VERSION ""

NS_ :

BS_:

BU_:

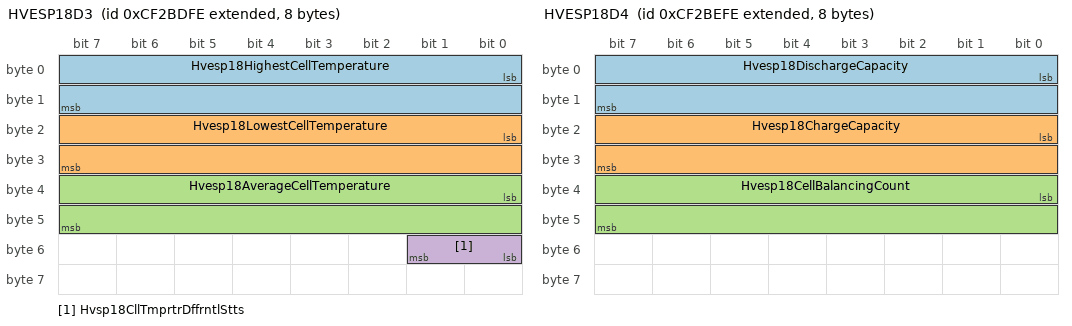
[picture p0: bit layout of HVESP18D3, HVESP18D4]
BO_ 2364718590 HVESP18D3: 8 Vector__XXX
 SG_ Hvesp18HighestCellTemperature : 0|16@1+ (0.03125,-273) [-273|1734.96875] "degC" Vector__XXX
 SG_ Hvesp18LowestCellTemperature : 16|16@1+ (0.03125,-273) [-273|1734.96875] "degC" Vector__XXX
 SG_ Hvesp18AverageCellTemperature : 32|16@1+ (0.03125,-273) [-273|1734.96875] "degC" Vector__XXX
 SG_ Hvsp18CllTmprtrDffrntlStts : 48|2@1+ (1,0) [0|3] "" Vector__XXX

BO_ 2364718846 HVESP18D4: 8 Vector__XXX
 SG_ Hvesp18DischargeCapacity : 0|16@1+ (0.01,0) [0|642.55] "Ah" Vector__XXX
 SG_ Hvesp18ChargeCapacity : 16|16@1+ (0.01,0) [0|642.55] "Ah" Vector__XXX
 SG_ Hvesp18CellBalancingCount : 32|16@1+ (1,0) [0|64255] "count" Vector__XXX

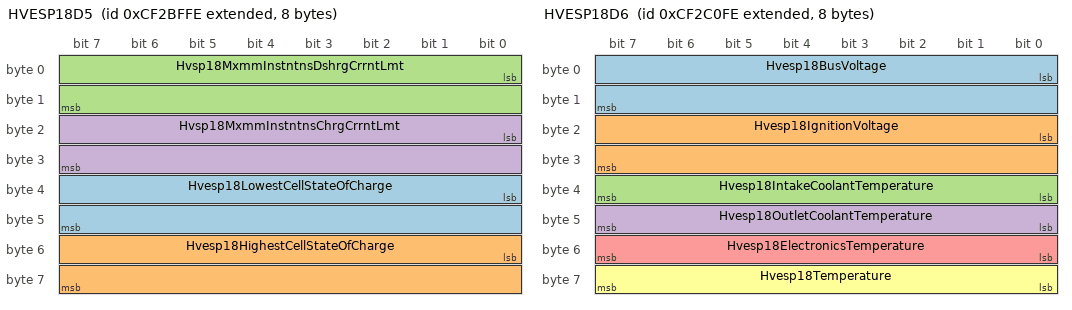
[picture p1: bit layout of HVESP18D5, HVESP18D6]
BO_ 2364719102 HVESP18D5: 8 Vector__XXX
 SG_ Hvesp18LowestCellStateOfCharge : 32|16@1+ (0.0015625,0) [0|100.3984375] "%" Vector__XXX
 SG_ Hvesp18HighestCellStateOfCharge : 48|16@1+ (0.0015625,0) [0|100.3984375] "%" Vector__XXX
 SG_ Hvsp18MxmmInstntnsDshrgCrrntLmt : 0|16@1+ (0.05,-1600) [-1600|0] "A" Vector__XXX
 SG_ Hvsp18MxmmInstntnsChrgCrrntLmt : 16|16@1+ (0.05,-1600) [0|1612.75] "A" Vector__XXX

BO_ 2364719358 HVESP18D6: 8 Vector__XXX
 SG_ Hvesp18BusVoltage : 0|16@1+ (0.05,0) [0|3212.75] "V" Vector__XXX
 SG_ Hvesp18IgnitionVoltage : 16|16@1+ (0.01,0) [0|642.55] "V" Vector__XXX
 SG_ Hvesp18IntakeCoolantTemperature : 32|8@1+ (1,-40) [-40|210] "degC" Vector__XXX
 SG_ Hvesp18OutletCoolantTemperature : 40|8@1+ (1,-40) [-40|210] "degC" Vector__XXX
 SG_ Hvesp18ElectronicsTemperature : 48|8@1+ (1,-40) [-40|210] "degC" Vector__XXX
 SG_ Hvesp18Temperature : 56|8@1+ (1,-40) [-40|210] "degC" Vector__XXX

BO_ 2364719614 HVESP18S1: 8 Vector__XXX
 SG_ Hvsp18HghVltgBsPstvCnttrStt : 0|2@1+ (1,0) [0|3] "" Vector__XXX
 SG_ Hvsp18HghVltgBsNgtvCnttrStt : 2|2@1+ (1,0) [0|3] "" Vector__XXX
 SG_ Hvsp18HghVltgBsDsnntFrwrnng : 4|4@1+ (1,0) [0|15] "" Vector__XXX
 SG_ Hvsp18HghVltgBsPrChrgRlStt : 8|2@1+ (1,0) [0|3] "" Vector__XXX
 SG_ Hvsp18CntrOfPkCnttrStt : 10|2@1+ (1,0) [0|3] "" Vector__XXX
 SG_ Hvsp18HghVltgBsAtvIsltnTstStts : 12|4@1+ (1,0) [0|15] "" Vector__XXX
 SG_ Hvsp18HghVltgBsPssvIsltnTstStts : 16|4@1+ (1,0) [0|15] "" Vector__XXX
 SG_ Hvesp18HvilStatus : 20|2@1+ (1,0) [0|3] "" Vector__XXX
 SG_ Hvesp18InertiaSwitchStatus : 22|2@1+ (1,0) [0|3] "" Vector__XXX
 SG_ Hvesp18StateOfChargeStatus : 24|4@1+ (1,0) [0|15] "" Vector__XXX
 SG_ Hvesp18CellBalanceStatus : 28|2@1+ (1,0) [0|3] "" Vector__XXX
 SG_ Hvesp18CellBalancingActive : 30|2@1+ (1,0) [0|3] "" Vector__XXX
 SG_ Hvesp18InternalChargerStatus : 32|2@1+ (1,0) [0|3] "" Vector__XXX
 SG_ Hvsp18HghVltgBsCnntnStts : 40|4@1+ (1,0) [0|15] "" Vector__XXX
 SG_ Hvesp18OperationalStatus : 44|4@1+ (1,0) [0|15] "" Vector__XXX
 SG_ Hvesp18Status1Counter : 52|4@1+ (1,0) [0|15] "" Vector__XXX
 SG_ Hvesp18Status1Crc : 56|8@1+ (1,0) [0|250] "count" Vector__XXX

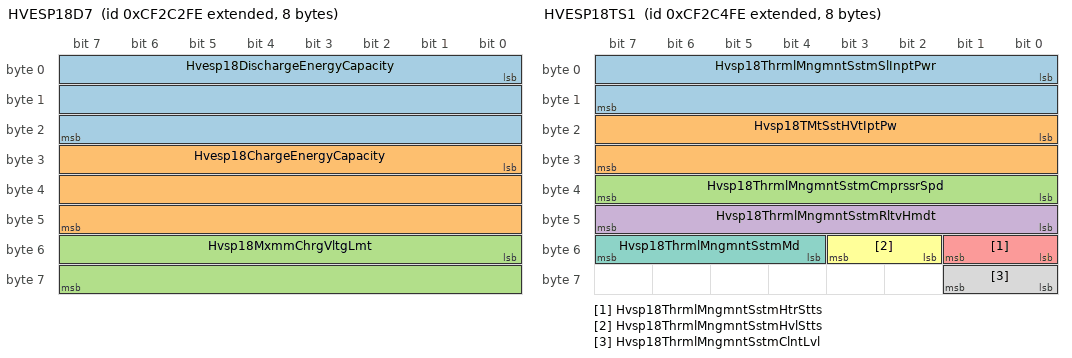
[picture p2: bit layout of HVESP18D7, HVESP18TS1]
BO_ 2364719870 HVESP18D7: 8 Vector__XXX
 SG_ Hvesp18DischargeEnergyCapacity : 0|24@1+ (0.001,0) [0|16449.535] "kWh" Vector__XXX
 SG_ Hvesp18ChargeEnergyCapacity : 24|24@1+ (0.001,0) [0|16449.535] "kWh" Vector__XXX
 SG_ Hvsp18MxmmChrgVltgLmt : 48|16@1+ (0.05,0) [0|3212.75] "V" Vector__XXX

BO_ 2364720126 HVESP18MS1: 8 Vector__XXX
 SG_ Hvesp18Module1OperationalStatus : 0|2@1+ (1,0) [0|3] "" Vector__XXX
 SG_ Hvesp18Module2OperationalStatus : 2|2@1+ (1,0) [0|3] "" Vector__XXX
 SG_ Hvesp18Module3OperationalStatus : 4|2@1+ (1,0) [0|3] "" Vector__XXX
 SG_ Hvesp18Module4OperationalStatus : 6|2@1+ (1,0) [0|3] "" Vector__XXX
 SG_ Hvesp18Module5OperationalStatus : 8|2@1+ (1,0) [0|3] "" Vector__XXX
 SG_ Hvesp18Module6OperationalStatus : 10|2@1+ (1,0) [0|3] "" Vector__XXX
 SG_ Hvesp18Module7OperationalStatus : 12|2@1+ (1,0) [0|3] "" Vector__XXX
 SG_ Hvesp18Module8OperationalStatus : 14|2@1+ (1,0) [0|3] "" Vector__XXX
 SG_ Hvesp18Module9OperationalStatus : 16|2@1+ (1,0) [0|3] "" Vector__XXX
 SG_ Hvsp18Mdl10OprtnlStts : 18|2@1+ (1,0) [0|3] "" Vector__XXX
 SG_ Hvsp18Mdl11OprtnlStts : 20|2@1+ (1,0) [0|3] "" Vector__XXX
 SG_ Hvsp18Mdl12OprtnlStts : 22|2@1+ (1,0) [0|3] "" Vector__XXX
 SG_ Hvsp18Mdl13OprtnlStts : 24|2@1+ (1,0) [0|3] "" Vector__XXX
 SG_ Hvsp18Mdl14OprtnlStts : 26|2@1+ (1,0) [0|3] "" Vector__XXX
 SG_ Hvsp18Mdl15OprtnlStts : 28|2@1+ (1,0) [0|3] "" Vector__XXX
 SG_ Hvsp18Mdl16OprtnlStts : 30|2@1+ (1,0) [0|3] "" Vector__XXX
 SG_ Hvsp18Mdl17OprtnlStts : 32|2@1+ (1,0) [0|3] "" Vector__XXX
 SG_ Hvsp18Mdl18OprtnlStts : 34|2@1+ (1,0) [0|3] "" Vector__XXX
 SG_ Hvsp18Mdl19OprtnlStts : 36|2@1+ (1,0) [0|3] "" Vector__XXX
 SG_ Hvsp18Mdl20OprtnlStts : 38|2@1+ (1,0) [0|3] "" Vector__XXX
 SG_ Hvsp18Mdl21OprtnlStts : 40|2@1+ (1,0) [0|3] "" Vector__XXX
 SG_ Hvsp18Mdl22OprtnlStts : 42|2@1+ (1,0) [0|3] "" Vector__XXX
 SG_ Hvsp18Mdl23OprtnlStts : 44|2@1+ (1,0) [0|3] "" Vector__XXX
 SG_ Hvsp18Mdl24OprtnlStts : 46|2@1+ (1,0) [0|3] "" Vector__XXX
 SG_ Hvsp18Mdl25OprtnlStts : 48|2@1+ (1,0) [0|3] "" Vector__XXX
 SG_ Hvsp18Mdl26OprtnlStts : 50|2@1+ (1,0) [0|3] "" Vector__XXX
 SG_ Hvsp18Mdl27OprtnlStts : 52|2@1+ (1,0) [0|3] "" Vector__XXX
 SG_ Hvsp18Mdl28OprtnlStts : 54|2@1+ (1,0) [0|3] "" Vector__XXX
 SG_ Hvsp18Mdl29OprtnlStts : 56|2@1+ (1,0) [0|3] "" Vector__XXX
 SG_ Hvsp18Mdl30OprtnlStts : 58|2@1+ (1,0) [0|3] "" Vector__XXX
 SG_ Hvsp18Mdl31OprtnlStts : 60|2@1+ (1,0) [0|3] "" Vector__XXX
 SG_ Hvsp18Mdl32OprtnlStts : 62|2@1+ (1,0) [0|3] "" Vector__XXX

BO_ 2364720382 HVESP18TS1: 8 Vector__XXX
 SG_ Hvsp18ThrmlMngmntSstmSlInptPwr : 0|16@1+ (0.5,0) [0|32127.5] "W" Vector__XXX
 SG_ Hvsp18TMtSstHVtIptPw : 16|16@1+ (0.5,0) [0|32127.5] "W" Vector__XXX
 SG_ Hvsp18ThrmlMngmntSstmCmprssrSpd : 32|8@1+ (32,0) [0|8000] "rpm" Vector__XXX
 SG_ Hvsp18ThrmlMngmntSstmRltvHmdt : 40|8@1+ (0.4,0) [0|100] "%" Vector__XXX
 SG_ Hvsp18ThrmlMngmntSstmHtrStts : 48|2@1+ (1,0) [0|3] "" Vector__XXX
 SG_ Hvsp18ThrmlMngmntSstmHvlStts : 50|2@1+ (1,0) [0|3] "" Vector__XXX
 SG_ Hvsp18ThrmlMngmntSstmMd : 52|4@1+ (1,0) [0|15] "" Vector__XXX
 SG_ Hvsp18ThrmlMngmntSstmClntLvl : 56|2@1+ (1,0) [0|3] "" Vector__XXX

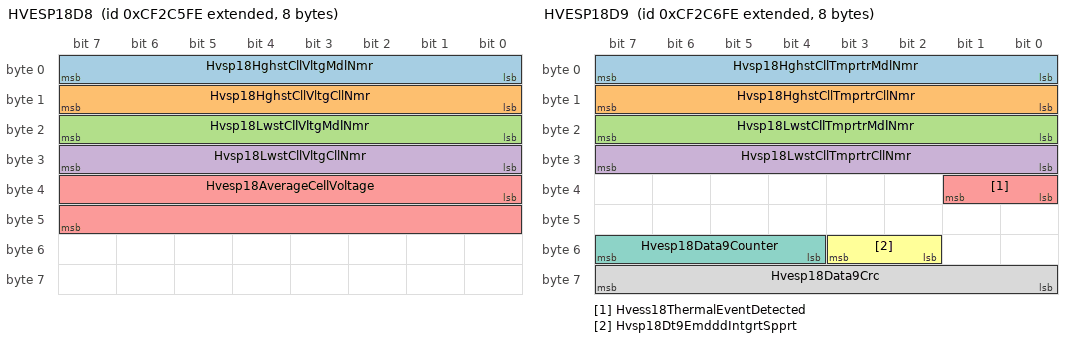
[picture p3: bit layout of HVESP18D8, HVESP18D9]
BO_ 2364720638 HVESP18D8: 8 Vector__XXX
 SG_ Hvsp18HghstCllVltgMdlNmr : 0|8@1+ (1,0) [0|250] "count" Vector__XXX
 SG_ Hvsp18HghstCllVltgCllNmr : 8|8@1+ (1,0) [0|250] "count" Vector__XXX
 SG_ Hvsp18LwstCllVltgMdlNmr : 16|8@1+ (1,0) [0|250] "count" Vector__XXX
 SG_ Hvsp18LwstCllVltgCllNmr : 24|8@1+ (1,0) [0|250] "count" Vector__XXX
 SG_ Hvesp18AverageCellVoltage : 32|16@1+ (0.001,0) [0|64.255] "V" Vector__XXX

BO_ 2364720894 HVESP18D9: 8 Vector__XXX
 SG_ Hvsp18HghstCllTmprtrMdlNmr : 0|8@1+ (1,0) [0|250] "count" Vector__XXX
 SG_ Hvsp18HghstCllTmprtrCllNmr : 8|8@1+ (1,0) [0|250] "count" Vector__XXX
 SG_ Hvsp18LwstCllTmprtrMdlNmr : 16|8@1+ (1,0) [0|250] "count" Vector__XXX
 SG_ Hvsp18LwstCllTmprtrCllNmr : 24|8@1+ (1,0) [0|250] "count" Vector__XXX
 SG_ Hvess18ThermalEventDetected : 32|2@1+ (1,0) [0|3] "" Vector__XXX
 SG_ Hvsp18Dt9EmdddIntgrtSpprt : 50|2@1+ (1,0) [0|3] "" Vector__XXX
 SG_ Hvesp18Data9Counter : 52|4@1+ (1,0) [0|15] "" Vector__XXX
 SG_ Hvesp18Data9Crc : 56|8@1+ (1,0) [0|250] "count" Vector__XXX

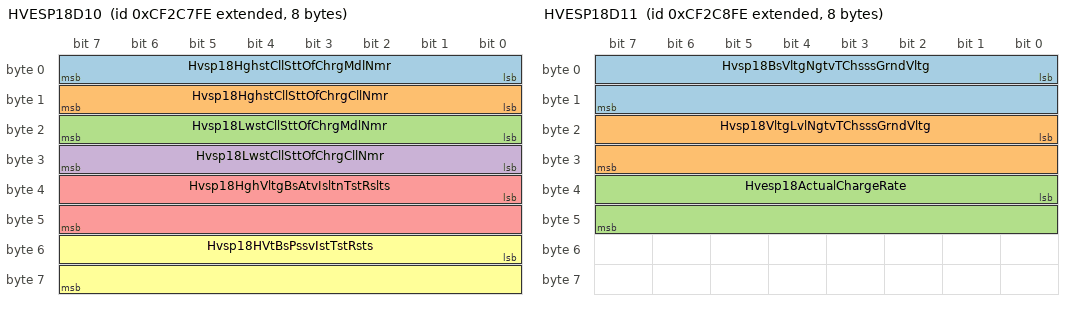
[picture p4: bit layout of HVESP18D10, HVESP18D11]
BO_ 2364721150 HVESP18D10: 8 Vector__XXX
 SG_ Hvsp18HghstCllSttOfChrgMdlNmr : 0|8@1+ (1,0) [0|250] "count" Vector__XXX
 SG_ Hvsp18HghstCllSttOfChrgCllNmr : 8|8@1+ (1,0) [0|250] "count" Vector__XXX
 SG_ Hvsp18LwstCllSttOfChrgMdlNmr : 16|8@1+ (1,0) [0|250] "count" Vector__XXX
 SG_ Hvsp18LwstCllSttOfChrgCllNmr : 24|8@1+ (1,0) [0|250] "count" Vector__XXX
 SG_ Hvsp18HghVltgBsAtvIsltnTstRslts : 32|16@1+ (0.1,0) [0|6425.5] "OhmPerV" Vector__XXX
 SG_ Hvsp18HVtBsPssvIstTstRsts : 48|16@1+ (0.1,0) [0|6425.5] "OhmPerV" Vector__XXX

BO_ 2364721406 HVESP18D11: 8 Vector__XXX
 SG_ Hvsp18BsVltgNgtvTChsssGrndVltg : 0|16@1+ (0.05,0) [0|3212.75] "V" Vector__XXX
 SG_ Hvsp18VltgLvlNgtvTChsssGrndVltg : 16|16@1+ (0.05,0) [0|3212.75] "V" Vector__XXX
 SG_ Hvesp18ActualChargeRate : 32|16@1+ (0.05,0) [0|3212.75] "kW" Vector__XXX

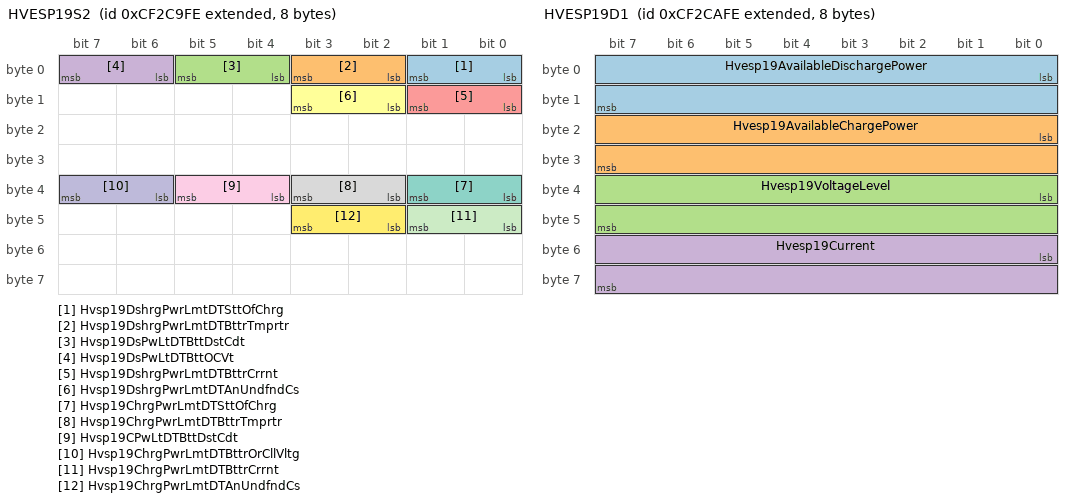
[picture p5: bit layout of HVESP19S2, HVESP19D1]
BO_ 2364721662 HVESP19S2: 8 Vector__XXX
 SG_ Hvsp19DshrgPwrLmtDTSttOfChrg : 0|2@1+ (1,0) [0|3] "" Vector__XXX
 SG_ Hvsp19DshrgPwrLmtDTBttrTmprtr : 2|2@1+ (1,0) [0|3] "" Vector__XXX
 SG_ Hvsp19DsPwLtDTBttDstCdt : 4|2@1+ (1,0) [0|3] "" Vector__XXX
 SG_ Hvsp19DsPwLtDTBttOCVt : 6|2@1+ (1,0) [0|3] "" Vector__XXX
 SG_ Hvsp19DshrgPwrLmtDTBttrCrrnt : 8|2@1+ (1,0) [0|3] "" Vector__XXX
 SG_ Hvsp19DshrgPwrLmtDTAnUndfndCs : 10|2@1+ (1,0) [0|3] "" Vector__XXX
 SG_ Hvsp19ChrgPwrLmtDTSttOfChrg : 32|2@1+ (1,0) [0|3] "" Vector__XXX
 SG_ Hvsp19ChrgPwrLmtDTBttrTmprtr : 34|2@1+ (1,0) [0|3] "" Vector__XXX
 SG_ Hvsp19CPwLtDTBttDstCdt : 36|2@1+ (1,0) [0|3] "" Vector__XXX
 SG_ Hvsp19ChrgPwrLmtDTBttrOrCllVltg : 38|2@1+ (1,0) [0|3] "" Vector__XXX
 SG_ Hvsp19ChrgPwrLmtDTBttrCrrnt : 40|2@1+ (1,0) [0|3] "" Vector__XXX
 SG_ Hvsp19ChrgPwrLmtDTAnUndfndCs : 42|2@1+ (1,0) [0|3] "" Vector__XXX

BO_ 2364721918 HVESP19D1: 8 Vector__XXX
 SG_ Hvesp19AvailableDischargePower : 0|16@1+ (0.05,0) [0|3212.75] "kW" Vector__XXX
 SG_ Hvesp19AvailableChargePower : 16|16@1+ (0.05,0) [0|3212.75] "kW" Vector__XXX
 SG_ Hvesp19VoltageLevel : 32|16@1+ (0.05,0) [0|3212.75] "V" Vector__XXX
 SG_ Hvesp19Current : 48|16@1+ (0.05,-1600) [-1600|1612.75] "A" Vector__XXX

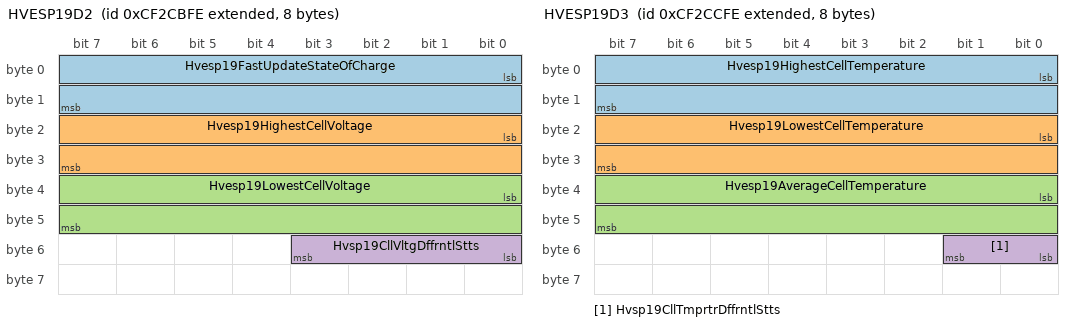
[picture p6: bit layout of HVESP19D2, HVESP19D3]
BO_ 2364722174 HVESP19D2: 8 Vector__XXX
 SG_ Hvesp19FastUpdateStateOfCharge : 0|16@1+ (0.0015625,0) [0|100.3984375] "%" Vector__XXX
 SG_ Hvesp19HighestCellVoltage : 16|16@1+ (0.001,0) [0|64.255] "V" Vector__XXX
 SG_ Hvesp19LowestCellVoltage : 32|16@1+ (0.001,0) [0|64.255] "V" Vector__XXX
 SG_ Hvsp19CllVltgDffrntlStts : 48|4@1+ (1,0) [0|15] "" Vector__XXX

BO_ 2364722430 HVESP19D3: 8 Vector__XXX
 SG_ Hvesp19HighestCellTemperature : 0|16@1+ (0.03125,-273) [-273|1734.96875] "degC" Vector__XXX
 SG_ Hvesp19LowestCellTemperature : 16|16@1+ (0.03125,-273) [-273|1734.96875] "degC" Vector__XXX
 SG_ Hvesp19AverageCellTemperature : 32|16@1+ (0.03125,-273) [-273|1734.96875] "degC" Vector__XXX
 SG_ Hvsp19CllTmprtrDffrntlStts : 48|2@1+ (1,0) [0|3] "" Vector__XXX

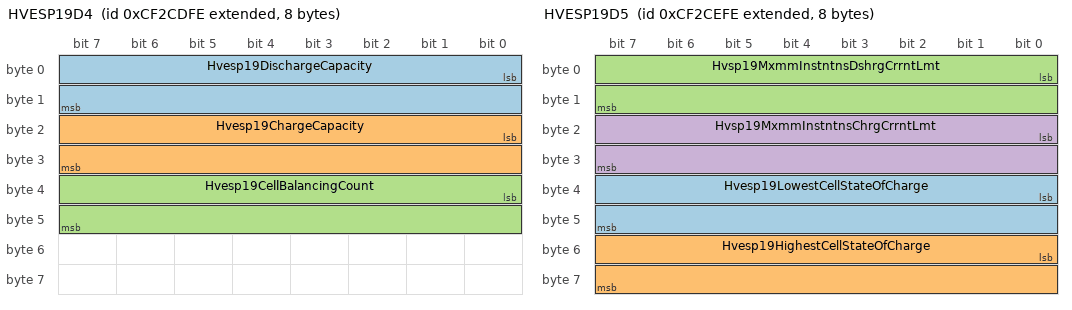
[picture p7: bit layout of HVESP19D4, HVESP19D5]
BO_ 2364722686 HVESP19D4: 8 Vector__XXX
 SG_ Hvesp19DischargeCapacity : 0|16@1+ (0.01,0) [0|642.55] "Ah" Vector__XXX
 SG_ Hvesp19ChargeCapacity : 16|16@1+ (0.01,0) [0|642.55] "Ah" Vector__XXX
 SG_ Hvesp19CellBalancingCount : 32|16@1+ (1,0) [0|64255] "count" Vector__XXX

BO_ 2364722942 HVESP19D5: 8 Vector__XXX
 SG_ Hvesp19LowestCellStateOfCharge : 32|16@1+ (0.0015625,0) [0|100.3984375] "%" Vector__XXX
 SG_ Hvesp19HighestCellStateOfCharge : 48|16@1+ (0.0015625,0) [0|100.3984375] "%" Vector__XXX
 SG_ Hvsp19MxmmInstntnsDshrgCrrntLmt : 0|16@1+ (0.05,-1600) [-1600|0] "A" Vector__XXX
 SG_ Hvsp19MxmmInstntnsChrgCrrntLmt : 16|16@1+ (0.05,-1600) [0|1612.75] "A" Vector__XXX

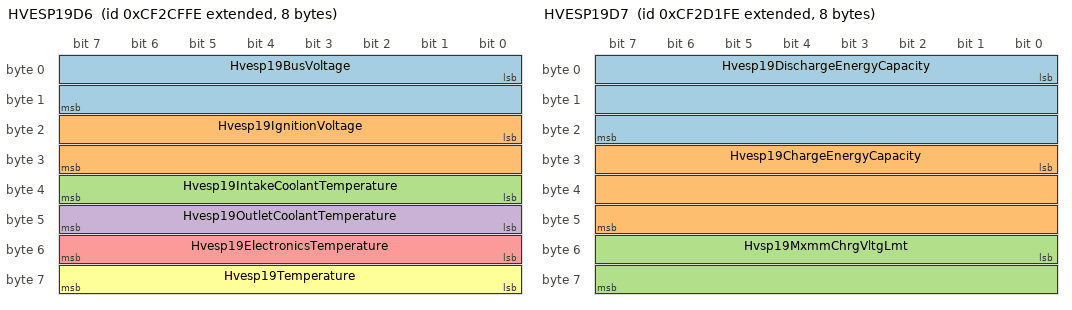
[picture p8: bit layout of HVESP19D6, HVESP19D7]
BO_ 2364723198 HVESP19D6: 8 Vector__XXX
 SG_ Hvesp19BusVoltage : 0|16@1+ (0.05,0) [0|3212.75] "V" Vector__XXX
 SG_ Hvesp19IgnitionVoltage : 16|16@1+ (0.01,0) [0|642.55] "V" Vector__XXX
 SG_ Hvesp19IntakeCoolantTemperature : 32|8@1+ (1,-40) [-40|210] "degC" Vector__XXX
 SG_ Hvesp19OutletCoolantTemperature : 40|8@1+ (1,-40) [-40|210] "degC" Vector__XXX
 SG_ Hvesp19ElectronicsTemperature : 48|8@1+ (1,-40) [-40|210] "degC" Vector__XXX
 SG_ Hvesp19Temperature : 56|8@1+ (1,-40) [-40|210] "degC" Vector__XXX

BO_ 2364723454 HVESP19S1: 8 Vector__XXX
 SG_ Hvsp19HghVltgBsPstvCnttrStt : 0|2@1+ (1,0) [0|3] "" Vector__XXX
 SG_ Hvsp19HghVltgBsNgtvCnttrStt : 2|2@1+ (1,0) [0|3] "" Vector__XXX
 SG_ Hvsp19HghVltgBsDsnntFrwrnng : 4|4@1+ (1,0) [0|15] "" Vector__XXX
 SG_ Hvsp19HghVltgBsPrChrgRlStt : 8|2@1+ (1,0) [0|3] "" Vector__XXX
 SG_ Hvsp19CntrOfPkCnttrStt : 10|2@1+ (1,0) [0|3] "" Vector__XXX
 SG_ Hvsp19HghVltgBsAtvIsltnTstStts : 12|4@1+ (1,0) [0|15] "" Vector__XXX
 SG_ Hvsp19HghVltgBsPssvIsltnTstStts : 16|4@1+ (1,0) [0|15] "" Vector__XXX
 SG_ Hvesp19HvilStatus : 20|2@1+ (1,0) [0|3] "" Vector__XXX
 SG_ Hvesp19InertiaSwitchStatus : 22|2@1+ (1,0) [0|3] "" Vector__XXX
 SG_ Hvesp19StateOfChargeStatus : 24|4@1+ (1,0) [0|15] "" Vector__XXX
 SG_ Hvesp19CellBalanceStatus : 28|2@1+ (1,0) [0|3] "" Vector__XXX
 SG_ Hvesp19CellBalancingActive : 30|2@1+ (1,0) [0|3] "" Vector__XXX
 SG_ Hvesp19InternalChargerStatus : 32|2@1+ (1,0) [0|3] "" Vector__XXX
 SG_ Hvsp19HghVltgBsCnntnStts : 40|4@1+ (1,0) [0|15] "" Vector__XXX
 SG_ Hvesp19OperationalStatus : 44|4@1+ (1,0) [0|15] "" Vector__XXX
 SG_ Hvesp19Status1Counter : 52|4@1+ (1,0) [0|15] "" Vector__XXX
 SG_ Hvesp19Status1Crc : 56|8@1+ (1,0) [0|250] "count" Vector__XXX

BO_ 2364723710 HVESP19D7: 8 Vector__XXX
 SG_ Hvesp19DischargeEnergyCapacity : 0|24@1+ (0.001,0) [0|16449.535] "kWh" Vector__XXX
 SG_ Hvesp19ChargeEnergyCapacity : 24|24@1+ (0.001,0) [0|16449.535] "kWh" Vector__XXX
 SG_ Hvsp19MxmmChrgVltgLmt : 48|16@1+ (0.05,0) [0|3212.75] "V" Vector__XXX

BO_ 2364723966 HVESP19MS1: 8 Vector__XXX
 SG_ Hvesp19Module1OperationalStatus : 0|2@1+ (1,0) [0|3] "" Vector__XXX
 SG_ Hvesp19Module2OperationalStatus : 2|2@1+ (1,0) [0|3] "" Vector__XXX
 SG_ Hvesp19Module3OperationalStatus : 4|2@1+ (1,0) [0|3] "" Vector__XXX
 SG_ Hvesp19Module4OperationalStatus : 6|2@1+ (1,0) [0|3] "" Vector__XXX
 SG_ Hvesp19Module5OperationalStatus : 8|2@1+ (1,0) [0|3] "" Vector__XXX
 SG_ Hvesp19Module6OperationalStatus : 10|2@1+ (1,0) [0|3] "" Vector__XXX
 SG_ Hvesp19Module7OperationalStatus : 12|2@1+ (1,0) [0|3] "" Vector__XXX
 SG_ Hvesp19Module8OperationalStatus : 14|2@1+ (1,0) [0|3] "" Vector__XXX
 SG_ Hvesp19Module9OperationalStatus : 16|2@1+ (1,0) [0|3] "" Vector__XXX
 SG_ Hvsp19Mdl10OprtnlStts : 18|2@1+ (1,0) [0|3] "" Vector__XXX
 SG_ Hvsp19Mdl11OprtnlStts : 20|2@1+ (1,0) [0|3] "" Vector__XXX
 SG_ Hvsp19Mdl12OprtnlStts : 22|2@1+ (1,0) [0|3] "" Vector__XXX
 SG_ Hvsp19Mdl13OprtnlStts : 24|2@1+ (1,0) [0|3] "" Vector__XXX
 SG_ Hvsp19Mdl14OprtnlStts : 26|2@1+ (1,0) [0|3] "" Vector__XXX
 SG_ Hvsp19Mdl15OprtnlStts : 28|2@1+ (1,0) [0|3] "" Vector__XXX
 SG_ Hvsp19Mdl16OprtnlStts : 30|2@1+ (1,0) [0|3] "" Vector__XXX
 SG_ Hvsp19Mdl17OprtnlStts : 32|2@1+ (1,0) [0|3] "" Vector__XXX
 SG_ Hvsp19Mdl18OprtnlStts : 34|2@1+ (1,0) [0|3] "" Vector__XXX
 SG_ Hvsp19Mdl19OprtnlStts : 36|2@1+ (1,0) [0|3] "" Vector__XXX
 SG_ Hvsp19Mdl20OprtnlStts : 38|2@1+ (1,0) [0|3] "" Vector__XXX
 SG_ Hvsp19Mdl21OprtnlStts : 40|2@1+ (1,0) [0|3] "" Vector__XXX
 SG_ Hvsp19Mdl22OprtnlStts : 42|2@1+ (1,0) [0|3] "" Vector__XXX
 SG_ Hvsp19Mdl23OprtnlStts : 44|2@1+ (1,0) [0|3] "" Vector__XXX
 SG_ Hvsp19Mdl24OprtnlStts : 46|2@1+ (1,0) [0|3] "" Vector__XXX
 SG_ Hvsp19Mdl25OprtnlStts : 48|2@1+ (1,0) [0|3] "" Vector__XXX
 SG_ Hvsp19Mdl26OprtnlStts : 50|2@1+ (1,0) [0|3] "" Vector__XXX
 SG_ Hvsp19Mdl27OprtnlStts : 52|2@1+ (1,0) [0|3] "" Vector__XXX
 SG_ Hvsp19Mdl28OprtnlStts : 54|2@1+ (1,0) [0|3] "" Vector__XXX
 SG_ Hvsp19Mdl29OprtnlStts : 56|2@1+ (1,0) [0|3] "" Vector__XXX
 SG_ Hvsp19Mdl30OprtnlStts : 58|2@1+ (1,0) [0|3] "" Vector__XXX
 SG_ Hvsp19Mdl31OprtnlStts : 60|2@1+ (1,0) [0|3] "" Vector__XXX
 SG_ Hvsp19Mdl32OprtnlStts : 62|2@1+ (1,0) [0|3] "" Vector__XXX

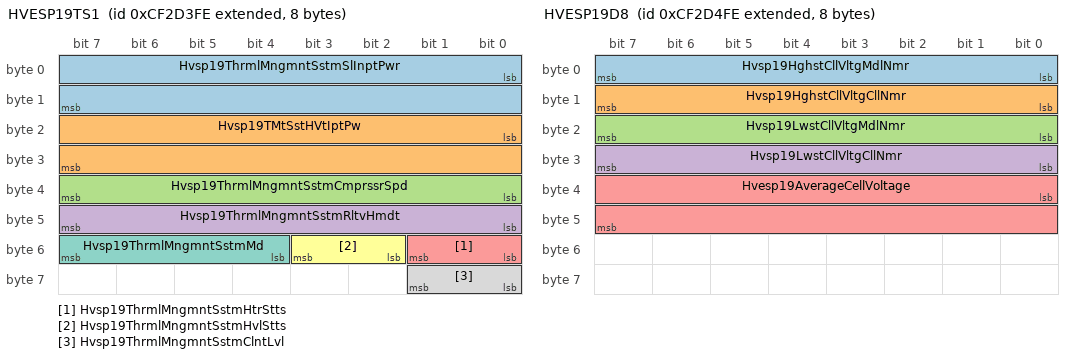
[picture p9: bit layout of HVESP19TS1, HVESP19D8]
BO_ 2364724222 HVESP19TS1: 8 Vector__XXX
 SG_ Hvsp19ThrmlMngmntSstmSlInptPwr : 0|16@1+ (0.5,0) [0|32127.5] "W" Vector__XXX
 SG_ Hvsp19TMtSstHVtIptPw : 16|16@1+ (0.5,0) [0|32127.5] "W" Vector__XXX
 SG_ Hvsp19ThrmlMngmntSstmCmprssrSpd : 32|8@1+ (32,0) [0|8000] "rpm" Vector__XXX
 SG_ Hvsp19ThrmlMngmntSstmRltvHmdt : 40|8@1+ (0.4,0) [0|100] "%" Vector__XXX
 SG_ Hvsp19ThrmlMngmntSstmHtrStts : 48|2@1+ (1,0) [0|3] "" Vector__XXX
 SG_ Hvsp19ThrmlMngmntSstmHvlStts : 50|2@1+ (1,0) [0|3] "" Vector__XXX
 SG_ Hvsp19ThrmlMngmntSstmMd : 52|4@1+ (1,0) [0|15] "" Vector__XXX
 SG_ Hvsp19ThrmlMngmntSstmClntLvl : 56|2@1+ (1,0) [0|3] "" Vector__XXX

BO_ 2364724478 HVESP19D8: 8 Vector__XXX
 SG_ Hvsp19HghstCllVltgMdlNmr : 0|8@1+ (1,0) [0|250] "count" Vector__XXX
 SG_ Hvsp19HghstCllVltgCllNmr : 8|8@1+ (1,0) [0|250] "count" Vector__XXX
 SG_ Hvsp19LwstCllVltgMdlNmr : 16|8@1+ (1,0) [0|250] "count" Vector__XXX
 SG_ Hvsp19LwstCllVltgCllNmr : 24|8@1+ (1,0) [0|250] "count" Vector__XXX
 SG_ Hvesp19AverageCellVoltage : 32|16@1+ (0.001,0) [0|64.255] "V" Vector__XXX

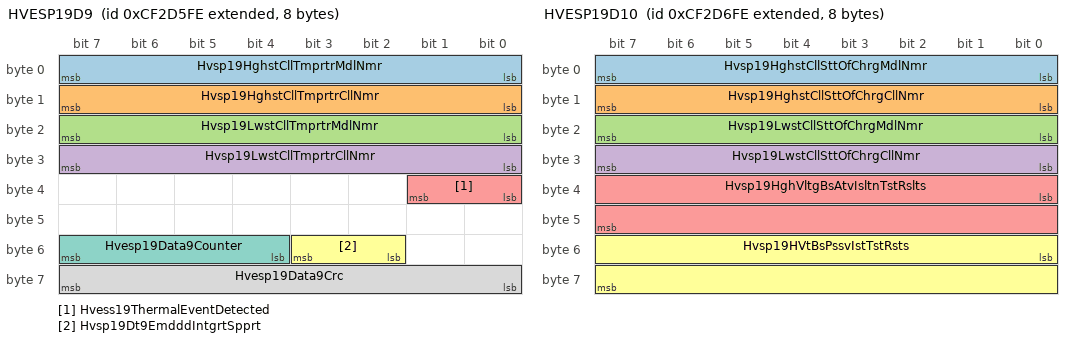
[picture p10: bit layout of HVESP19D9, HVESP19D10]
BO_ 2364724734 HVESP19D9: 8 Vector__XXX
 SG_ Hvsp19HghstCllTmprtrMdlNmr : 0|8@1+ (1,0) [0|250] "count" Vector__XXX
 SG_ Hvsp19HghstCllTmprtrCllNmr : 8|8@1+ (1,0) [0|250] "count" Vector__XXX
 SG_ Hvsp19LwstCllTmprtrMdlNmr : 16|8@1+ (1,0) [0|250] "count" Vector__XXX
 SG_ Hvsp19LwstCllTmprtrCllNmr : 24|8@1+ (1,0) [0|250] "count" Vector__XXX
 SG_ Hvess19ThermalEventDetected : 32|2@1+ (1,0) [0|3] "" Vector__XXX
 SG_ Hvsp19Dt9EmdddIntgrtSpprt : 50|2@1+ (1,0) [0|3] "" Vector__XXX
 SG_ Hvesp19Data9Counter : 52|4@1+ (1,0) [0|15] "" Vector__XXX
 SG_ Hvesp19Data9Crc : 56|8@1+ (1,0) [0|250] "count" Vector__XXX

BO_ 2364724990 HVESP19D10: 8 Vector__XXX
 SG_ Hvsp19HghstCllSttOfChrgMdlNmr : 0|8@1+ (1,0) [0|250] "count" Vector__XXX
 SG_ Hvsp19HghstCllSttOfChrgCllNmr : 8|8@1+ (1,0) [0|250] "count" Vector__XXX
 SG_ Hvsp19LwstCllSttOfChrgMdlNmr : 16|8@1+ (1,0) [0|250] "count" Vector__XXX
 SG_ Hvsp19LwstCllSttOfChrgCllNmr : 24|8@1+ (1,0) [0|250] "count" Vector__XXX
 SG_ Hvsp19HghVltgBsAtvIsltnTstRslts : 32|16@1+ (0.1,0) [0|6425.5] "OhmPerV" Vector__XXX
 SG_ Hvsp19HVtBsPssvIstTstRsts : 48|16@1+ (0.1,0) [0|6425.5] "OhmPerV" Vector__XXX

BO_ 2364725246 HVESP19D11: 8 Vector__XXX
 SG_ Hvsp19BsVltgNgtvTChsssGrndVltg : 0|16@1+ (0.05,0) [0|3212.75] "V" Vector__XXX
 SG_ Hvsp19VltgLvlNgtvTChsssGrndVltg : 16|16@1+ (0.05,0) [0|3212.75] "V" Vector__XXX
 SG_ Hvesp19ActualChargeRate : 32|16@1+ (0.05,0) [0|3212.75] "kW" Vector__XXX

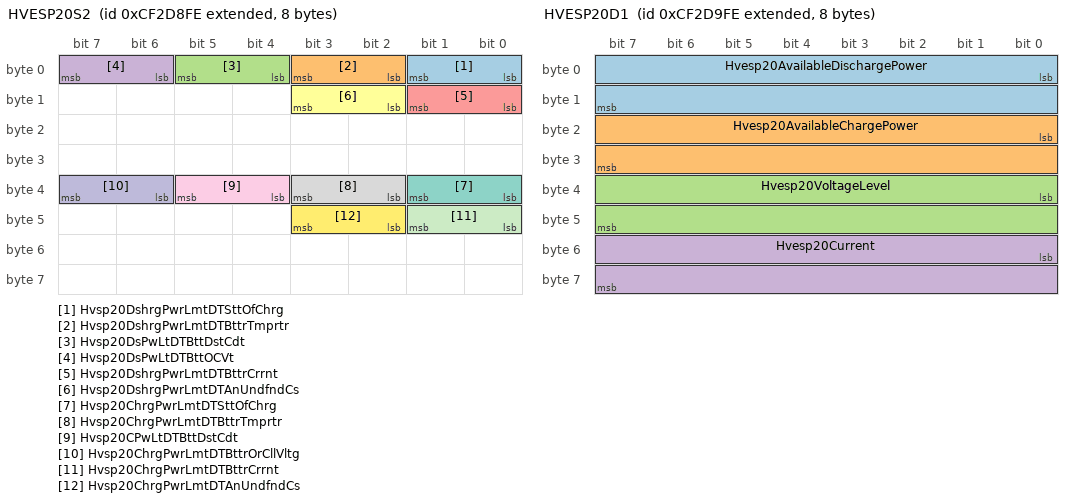
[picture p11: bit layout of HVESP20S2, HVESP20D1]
BO_ 2364725502 HVESP20S2: 8 Vector__XXX
 SG_ Hvsp20DshrgPwrLmtDTSttOfChrg : 0|2@1+ (1,0) [0|3] "" Vector__XXX
 SG_ Hvsp20DshrgPwrLmtDTBttrTmprtr : 2|2@1+ (1,0) [0|3] "" Vector__XXX
 SG_ Hvsp20DsPwLtDTBttDstCdt : 4|2@1+ (1,0) [0|3] "" Vector__XXX
 SG_ Hvsp20DsPwLtDTBttOCVt : 6|2@1+ (1,0) [0|3] "" Vector__XXX
 SG_ Hvsp20DshrgPwrLmtDTBttrCrrnt : 8|2@1+ (1,0) [0|3] "" Vector__XXX
 SG_ Hvsp20DshrgPwrLmtDTAnUndfndCs : 10|2@1+ (1,0) [0|3] "" Vector__XXX
 SG_ Hvsp20ChrgPwrLmtDTSttOfChrg : 32|2@1+ (1,0) [0|3] "" Vector__XXX
 SG_ Hvsp20ChrgPwrLmtDTBttrTmprtr : 34|2@1+ (1,0) [0|3] "" Vector__XXX
 SG_ Hvsp20CPwLtDTBttDstCdt : 36|2@1+ (1,0) [0|3] "" Vector__XXX
 SG_ Hvsp20ChrgPwrLmtDTBttrOrCllVltg : 38|2@1+ (1,0) [0|3] "" Vector__XXX
 SG_ Hvsp20ChrgPwrLmtDTBttrCrrnt : 40|2@1+ (1,0) [0|3] "" Vector__XXX
 SG_ Hvsp20ChrgPwrLmtDTAnUndfndCs : 42|2@1+ (1,0) [0|3] "" Vector__XXX

BO_ 2364725758 HVESP20D1: 8 Vector__XXX
 SG_ Hvesp20AvailableDischargePower : 0|16@1+ (0.05,0) [0|3212.75] "kW" Vector__XXX
 SG_ Hvesp20AvailableChargePower : 16|16@1+ (0.05,0) [0|3212.75] "kW" Vector__XXX
 SG_ Hvesp20VoltageLevel : 32|16@1+ (0.05,0) [0|3212.75] "V" Vector__XXX
 SG_ Hvesp20Current : 48|16@1+ (0.05,-1600) [-1600|1612.75] "A" Vector__XXX

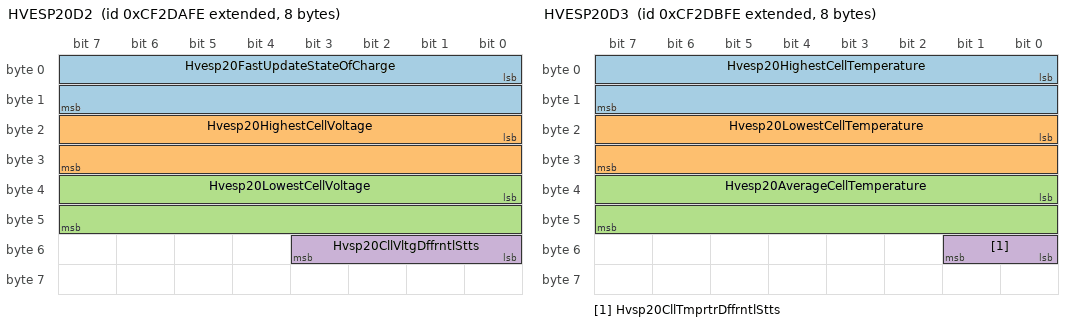
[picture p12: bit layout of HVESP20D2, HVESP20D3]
BO_ 2364726014 HVESP20D2: 8 Vector__XXX
 SG_ Hvesp20FastUpdateStateOfCharge : 0|16@1+ (0.0015625,0) [0|100.3984375] "%" Vector__XXX
 SG_ Hvesp20HighestCellVoltage : 16|16@1+ (0.001,0) [0|64.255] "V" Vector__XXX
 SG_ Hvesp20LowestCellVoltage : 32|16@1+ (0.001,0) [0|64.255] "V" Vector__XXX
 SG_ Hvsp20CllVltgDffrntlStts : 48|4@1+ (1,0) [0|15] "" Vector__XXX

BO_ 2364726270 HVESP20D3: 8 Vector__XXX
 SG_ Hvesp20HighestCellTemperature : 0|16@1+ (0.03125,-273) [-273|1734.96875] "degC" Vector__XXX
 SG_ Hvesp20LowestCellTemperature : 16|16@1+ (0.03125,-273) [-273|1734.96875] "degC" Vector__XXX
 SG_ Hvesp20AverageCellTemperature : 32|16@1+ (0.03125,-273) [-273|1734.96875] "degC" Vector__XXX
 SG_ Hvsp20CllTmprtrDffrntlStts : 48|2@1+ (1,0) [0|3] "" Vector__XXX

BO_ 2364726526 HVESP20D4: 8 Vector__XXX
 SG_ Hvesp20DischargeCapacity : 0|16@1+ (0.01,0) [0|642.55] "Ah" Vector__XXX
 SG_ Hvesp20ChargeCapacity : 16|16@1+ (0.01,0) [0|642.55] "Ah" Vector__XXX
 SG_ Hvesp20CellBalancingCount : 32|16@1+ (1,0) [0|64255] "count" Vector__XXX

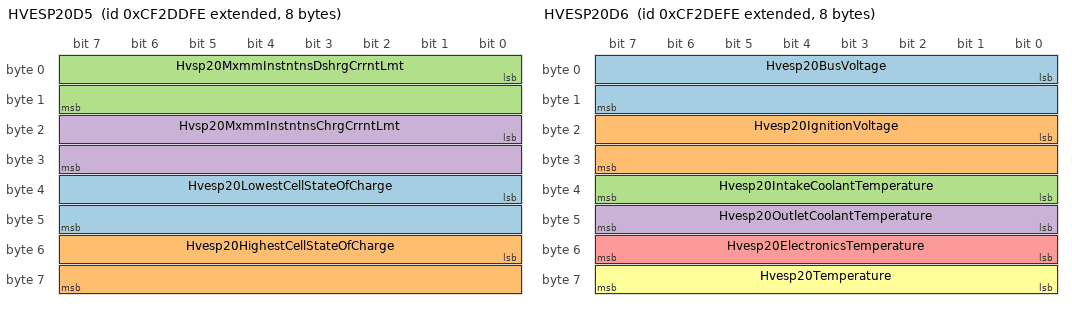
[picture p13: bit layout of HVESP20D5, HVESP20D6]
BO_ 2364726782 HVESP20D5: 8 Vector__XXX
 SG_ Hvesp20LowestCellStateOfCharge : 32|16@1+ (0.0015625,0) [0|100.3984375] "%" Vector__XXX
 SG_ Hvesp20HighestCellStateOfCharge : 48|16@1+ (0.0015625,0) [0|100.3984375] "%" Vector__XXX
 SG_ Hvsp20MxmmInstntnsDshrgCrrntLmt : 0|16@1+ (0.05,-1600) [-1600|0] "A" Vector__XXX
 SG_ Hvsp20MxmmInstntnsChrgCrrntLmt : 16|16@1+ (0.05,-1600) [0|1612.75] "A" Vector__XXX

BO_ 2364727038 HVESP20D6: 8 Vector__XXX
 SG_ Hvesp20BusVoltage : 0|16@1+ (0.05,0) [0|3212.75] "V" Vector__XXX
 SG_ Hvesp20IgnitionVoltage : 16|16@1+ (0.01,0) [0|642.55] "V" Vector__XXX
 SG_ Hvesp20IntakeCoolantTemperature : 32|8@1+ (1,-40) [-40|210] "degC" Vector__XXX
 SG_ Hvesp20OutletCoolantTemperature : 40|8@1+ (1,-40) [-40|210] "degC" Vector__XXX
 SG_ Hvesp20ElectronicsTemperature : 48|8@1+ (1,-40) [-40|210] "degC" Vector__XXX
 SG_ Hvesp20Temperature : 56|8@1+ (1,-40) [-40|210] "degC" Vector__XXX

BO_ 2364727294 HVESP20S1: 8 Vector__XXX
 SG_ Hvsp20HghVltgBsPstvCnttrStt : 0|2@1+ (1,0) [0|3] "" Vector__XXX
 SG_ Hvsp20HghVltgBsNgtvCnttrStt : 2|2@1+ (1,0) [0|3] "" Vector__XXX
 SG_ Hvsp20HghVltgBsDsnntFrwrnng : 4|4@1+ (1,0) [0|15] "" Vector__XXX
 SG_ Hvsp20HghVltgBsPrChrgRlStt : 8|2@1+ (1,0) [0|3] "" Vector__XXX
 SG_ Hvsp20CntrOfPkCnttrStt : 10|2@1+ (1,0) [0|3] "" Vector__XXX
 SG_ Hvsp20HghVltgBsAtvIsltnTstStts : 12|4@1+ (1,0) [0|15] "" Vector__XXX
 SG_ Hvsp20HghVltgBsPssvIsltnTstStts : 16|4@1+ (1,0) [0|15] "" Vector__XXX
 SG_ Hvesp20HvilStatus : 20|2@1+ (1,0) [0|3] "" Vector__XXX
 SG_ Hvesp20InertiaSwitchStatus : 22|2@1+ (1,0) [0|3] "" Vector__XXX
 SG_ Hvesp20StateOfChargeStatus : 24|4@1+ (1,0) [0|15] "" Vector__XXX
 SG_ Hvesp20CellBalanceStatus : 28|2@1+ (1,0) [0|3] "" Vector__XXX
 SG_ Hvesp20CellBalancingActive : 30|2@1+ (1,0) [0|3] "" Vector__XXX
 SG_ Hvesp20InternalChargerStatus : 32|2@1+ (1,0) [0|3] "" Vector__XXX
 SG_ Hvsp20HghVltgBsCnntnStts : 40|4@1+ (1,0) [0|15] "" Vector__XXX
 SG_ Hvesp20OperationalStatus : 44|4@1+ (1,0) [0|15] "" Vector__XXX
 SG_ Hvesp20Status1Counter : 52|4@1+ (1,0) [0|15] "" Vector__XXX
 SG_ Hvesp20Status1Crc : 56|8@1+ (1,0) [0|250] "count" Vector__XXX

BO_ 2364727550 HVESP20D7: 8 Vector__XXX
 SG_ Hvesp20DischargeEnergyCapacity : 0|24@1+ (0.001,0) [0|16449.535] "kWh" Vector__XXX
 SG_ Hvesp20ChargeEnergyCapacity : 24|24@1+ (0.001,0) [0|16449.535] "kWh" Vector__XXX
 SG_ Hvsp20MxmmChrgVltgLmt : 48|16@1+ (0.05,0) [0|3212.75] "V" Vector__XXX

BO_ 2364727806 HVESP20MS1: 8 Vector__XXX
 SG_ Hvesp20Module1OperationalStatus : 0|2@1+ (1,0) [0|3] "" Vector__XXX
 SG_ Hvesp20Module2OperationalStatus : 2|2@1+ (1,0) [0|3] "" Vector__XXX
 SG_ Hvesp20Module3OperationalStatus : 4|2@1+ (1,0) [0|3] "" Vector__XXX
 SG_ Hvesp20Module4OperationalStatus : 6|2@1+ (1,0) [0|3] "" Vector__XXX
 SG_ Hvesp20Module5OperationalStatus : 8|2@1+ (1,0) [0|3] "" Vector__XXX
 SG_ Hvesp20Module6OperationalStatus : 10|2@1+ (1,0) [0|3] "" Vector__XXX
 SG_ Hvesp20Module7OperationalStatus : 12|2@1+ (1,0) [0|3] "" Vector__XXX
 SG_ Hvesp20Module8OperationalStatus : 14|2@1+ (1,0) [0|3] "" Vector__XXX
 SG_ Hvesp20Module9OperationalStatus : 16|2@1+ (1,0) [0|3] "" Vector__XXX
 SG_ Hvsp20Mdl10OprtnlStts : 18|2@1+ (1,0) [0|3] "" Vector__XXX
 SG_ Hvsp20Mdl11OprtnlStts : 20|2@1+ (1,0) [0|3] "" Vector__XXX
 SG_ Hvsp20Mdl12OprtnlStts : 22|2@1+ (1,0) [0|3] "" Vector__XXX
 SG_ Hvsp20Mdl13OprtnlStts : 24|2@1+ (1,0) [0|3] "" Vector__XXX
 SG_ Hvsp20Mdl14OprtnlStts : 26|2@1+ (1,0) [0|3] "" Vector__XXX
 SG_ Hvsp20Mdl15OprtnlStts : 28|2@1+ (1,0) [0|3] "" Vector__XXX
 SG_ Hvsp20Mdl16OprtnlStts : 30|2@1+ (1,0) [0|3] "" Vector__XXX
 SG_ Hvsp20Mdl17OprtnlStts : 32|2@1+ (1,0) [0|3] "" Vector__XXX
 SG_ Hvsp20Mdl18OprtnlStts : 34|2@1+ (1,0) [0|3] "" Vector__XXX
 SG_ Hvsp20Mdl19OprtnlStts : 36|2@1+ (1,0) [0|3] "" Vector__XXX
 SG_ Hvsp20Mdl20OprtnlStts : 38|2@1+ (1,0) [0|3] "" Vector__XXX
 SG_ Hvsp20Mdl21OprtnlStts : 40|2@1+ (1,0) [0|3] "" Vector__XXX
 SG_ Hvsp20Mdl22OprtnlStts : 42|2@1+ (1,0) [0|3] "" Vector__XXX
 SG_ Hvsp20Mdl23OprtnlStts : 44|2@1+ (1,0) [0|3] "" Vector__XXX
 SG_ Hvsp20Mdl24OprtnlStts : 46|2@1+ (1,0) [0|3] "" Vector__XXX
 SG_ Hvsp20Mdl25OprtnlStts : 48|2@1+ (1,0) [0|3] "" Vector__XXX
 SG_ Hvsp20Mdl26OprtnlStts : 50|2@1+ (1,0) [0|3] "" Vector__XXX
 SG_ Hvsp20Mdl27OprtnlStts : 52|2@1+ (1,0) [0|3] "" Vector__XXX
 SG_ Hvsp20Mdl28OprtnlStts : 54|2@1+ (1,0) [0|3] "" Vector__XXX
 SG_ Hvsp20Mdl29OprtnlStts : 56|2@1+ (1,0) [0|3] "" Vector__XXX
 SG_ Hvsp20Mdl30OprtnlStts : 58|2@1+ (1,0) [0|3] "" Vector__XXX
 SG_ Hvsp20Mdl31OprtnlStts : 60|2@1+ (1,0) [0|3] "" Vector__XXX
 SG_ Hvsp20Mdl32OprtnlStts : 62|2@1+ (1,0) [0|3] "" Vector__XXX

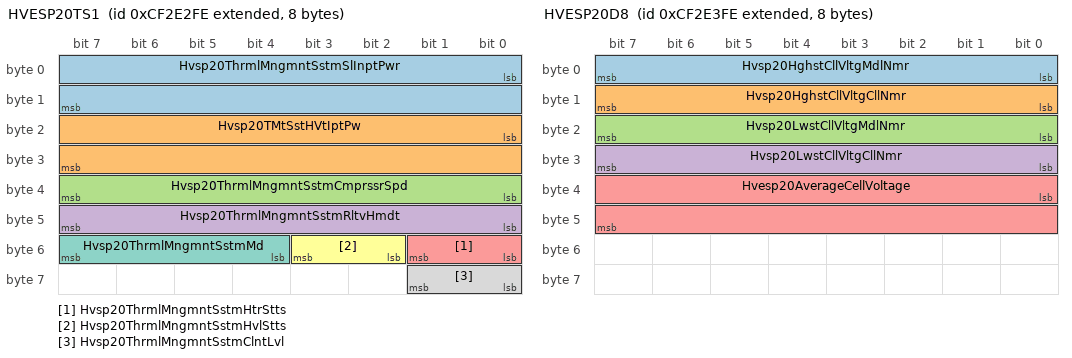
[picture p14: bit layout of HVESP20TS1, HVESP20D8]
BO_ 2364728062 HVESP20TS1: 8 Vector__XXX
 SG_ Hvsp20ThrmlMngmntSstmSlInptPwr : 0|16@1+ (0.5,0) [0|32127.5] "W" Vector__XXX
 SG_ Hvsp20TMtSstHVtIptPw : 16|16@1+ (0.5,0) [0|32127.5] "W" Vector__XXX
 SG_ Hvsp20ThrmlMngmntSstmCmprssrSpd : 32|8@1+ (32,0) [0|8000] "rpm" Vector__XXX
 SG_ Hvsp20ThrmlMngmntSstmRltvHmdt : 40|8@1+ (0.4,0) [0|100] "%" Vector__XXX
 SG_ Hvsp20ThrmlMngmntSstmHtrStts : 48|2@1+ (1,0) [0|3] "" Vector__XXX
 SG_ Hvsp20ThrmlMngmntSstmHvlStts : 50|2@1+ (1,0) [0|3] "" Vector__XXX
 SG_ Hvsp20ThrmlMngmntSstmMd : 52|4@1+ (1,0) [0|15] "" Vector__XXX
 SG_ Hvsp20ThrmlMngmntSstmClntLvl : 56|2@1+ (1,0) [0|3] "" Vector__XXX

BO_ 2364728318 HVESP20D8: 8 Vector__XXX
 SG_ Hvsp20HghstCllVltgMdlNmr : 0|8@1+ (1,0) [0|250] "count" Vector__XXX
 SG_ Hvsp20HghstCllVltgCllNmr : 8|8@1+ (1,0) [0|250] "count" Vector__XXX
 SG_ Hvsp20LwstCllVltgMdlNmr : 16|8@1+ (1,0) [0|250] "count" Vector__XXX
 SG_ Hvsp20LwstCllVltgCllNmr : 24|8@1+ (1,0) [0|250] "count" Vector__XXX
 SG_ Hvesp20AverageCellVoltage : 32|16@1+ (0.001,0) [0|64.255] "V" Vector__XXX

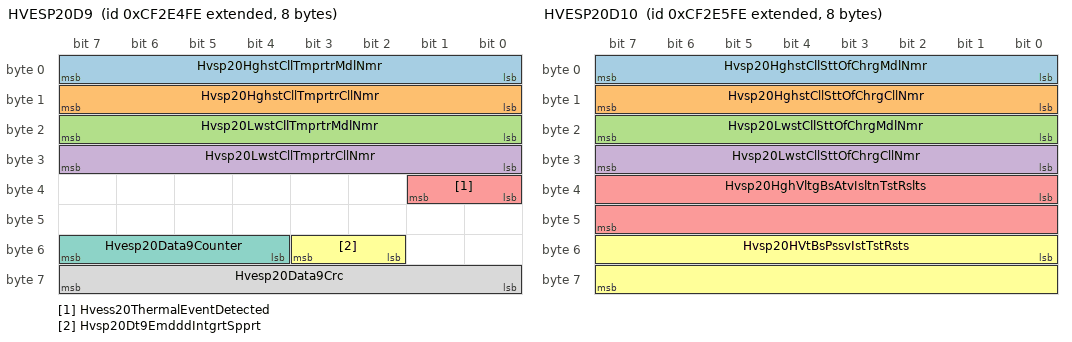
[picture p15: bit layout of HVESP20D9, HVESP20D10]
BO_ 2364728574 HVESP20D9: 8 Vector__XXX
 SG_ Hvsp20HghstCllTmprtrMdlNmr : 0|8@1+ (1,0) [0|250] "count" Vector__XXX
 SG_ Hvsp20HghstCllTmprtrCllNmr : 8|8@1+ (1,0) [0|250] "count" Vector__XXX
 SG_ Hvsp20LwstCllTmprtrMdlNmr : 16|8@1+ (1,0) [0|250] "count" Vector__XXX
 SG_ Hvsp20LwstCllTmprtrCllNmr : 24|8@1+ (1,0) [0|250] "count" Vector__XXX
 SG_ Hvess20ThermalEventDetected : 32|2@1+ (1,0) [0|3] "" Vector__XXX
 SG_ Hvsp20Dt9EmdddIntgrtSpprt : 50|2@1+ (1,0) [0|3] "" Vector__XXX
 SG_ Hvesp20Data9Counter : 52|4@1+ (1,0) [0|15] "" Vector__XXX
 SG_ Hvesp20Data9Crc : 56|8@1+ (1,0) [0|250] "count" Vector__XXX

BO_ 2364728830 HVESP20D10: 8 Vector__XXX
 SG_ Hvsp20HghstCllSttOfChrgMdlNmr : 0|8@1+ (1,0) [0|250] "count" Vector__XXX
 SG_ Hvsp20HghstCllSttOfChrgCllNmr : 8|8@1+ (1,0) [0|250] "count" Vector__XXX
 SG_ Hvsp20LwstCllSttOfChrgMdlNmr : 16|8@1+ (1,0) [0|250] "count" Vector__XXX
 SG_ Hvsp20LwstCllSttOfChrgCllNmr : 24|8@1+ (1,0) [0|250] "count" Vector__XXX
 SG_ Hvsp20HghVltgBsAtvIsltnTstRslts : 32|16@1+ (0.1,0) [0|6425.5] "OhmPerV" Vector__XXX
 SG_ Hvsp20HVtBsPssvIstTstRsts : 48|16@1+ (0.1,0) [0|6425.5] "OhmPerV" Vector__XXX

BO_ 2364729086 HVESP20D11: 8 Vector__XXX
 SG_ Hvsp20BsVltgNgtvTChsssGrndVltg : 0|16@1+ (0.05,0) [0|3212.75] "V" Vector__XXX
 SG_ Hvsp20VltgLvlNgtvTChsssGrndVltg : 16|16@1+ (0.05,0) [0|3212.75] "V" Vector__XXX
 SG_ Hvesp20ActualChargeRate : 32|16@1+ (0.05,0) [0|3212.75] "kW" Vector__XXX

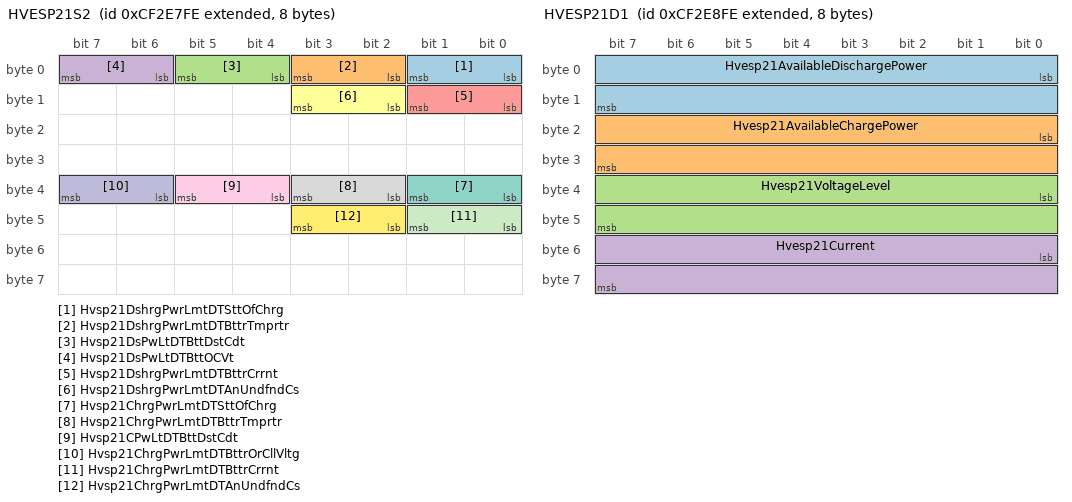
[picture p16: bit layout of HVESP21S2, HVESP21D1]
BO_ 2364729342 HVESP21S2: 8 Vector__XXX
 SG_ Hvsp21DshrgPwrLmtDTSttOfChrg : 0|2@1+ (1,0) [0|3] "" Vector__XXX
 SG_ Hvsp21DshrgPwrLmtDTBttrTmprtr : 2|2@1+ (1,0) [0|3] "" Vector__XXX
 SG_ Hvsp21DsPwLtDTBttDstCdt : 4|2@1+ (1,0) [0|3] "" Vector__XXX
 SG_ Hvsp21DsPwLtDTBttOCVt : 6|2@1+ (1,0) [0|3] "" Vector__XXX
 SG_ Hvsp21DshrgPwrLmtDTBttrCrrnt : 8|2@1+ (1,0) [0|3] "" Vector__XXX
 SG_ Hvsp21DshrgPwrLmtDTAnUndfndCs : 10|2@1+ (1,0) [0|3] "" Vector__XXX
 SG_ Hvsp21ChrgPwrLmtDTSttOfChrg : 32|2@1+ (1,0) [0|3] "" Vector__XXX
 SG_ Hvsp21ChrgPwrLmtDTBttrTmprtr : 34|2@1+ (1,0) [0|3] "" Vector__XXX
 SG_ Hvsp21CPwLtDTBttDstCdt : 36|2@1+ (1,0) [0|3] "" Vector__XXX
 SG_ Hvsp21ChrgPwrLmtDTBttrOrCllVltg : 38|2@1+ (1,0) [0|3] "" Vector__XXX
 SG_ Hvsp21ChrgPwrLmtDTBttrCrrnt : 40|2@1+ (1,0) [0|3] "" Vector__XXX
 SG_ Hvsp21ChrgPwrLmtDTAnUndfndCs : 42|2@1+ (1,0) [0|3] "" Vector__XXX

BO_ 2364729598 HVESP21D1: 8 Vector__XXX
 SG_ Hvesp21AvailableDischargePower : 0|16@1+ (0.05,0) [0|3212.75] "kW" Vector__XXX
 SG_ Hvesp21AvailableChargePower : 16|16@1+ (0.05,0) [0|3212.75] "kW" Vector__XXX
 SG_ Hvesp21VoltageLevel : 32|16@1+ (0.05,0) [0|3212.75] "V" Vector__XXX
 SG_ Hvesp21Current : 48|16@1+ (0.05,-1600) [-1600|1612.75] "A" Vector__XXX

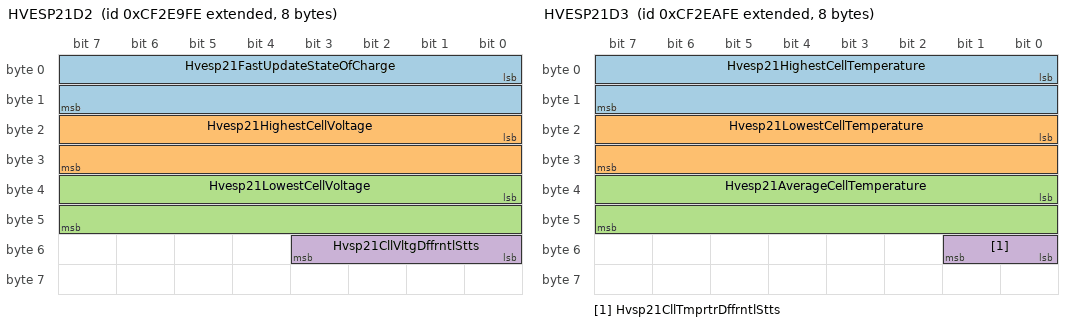
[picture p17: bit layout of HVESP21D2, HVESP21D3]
BO_ 2364729854 HVESP21D2: 8 Vector__XXX
 SG_ Hvesp21FastUpdateStateOfCharge : 0|16@1+ (0.0015625,0) [0|100.3984375] "%" Vector__XXX
 SG_ Hvesp21HighestCellVoltage : 16|16@1+ (0.001,0) [0|64.255] "V" Vector__XXX
 SG_ Hvesp21LowestCellVoltage : 32|16@1+ (0.001,0) [0|64.255] "V" Vector__XXX
 SG_ Hvsp21CllVltgDffrntlStts : 48|4@1+ (1,0) [0|15] "" Vector__XXX

BO_ 2364730110 HVESP21D3: 8 Vector__XXX
 SG_ Hvesp21HighestCellTemperature : 0|16@1+ (0.03125,-273) [-273|1734.96875] "degC" Vector__XXX
 SG_ Hvesp21LowestCellTemperature : 16|16@1+ (0.03125,-273) [-273|1734.96875] "degC" Vector__XXX
 SG_ Hvesp21AverageCellTemperature : 32|16@1+ (0.03125,-273) [-273|1734.96875] "degC" Vector__XXX
 SG_ Hvsp21CllTmprtrDffrntlStts : 48|2@1+ (1,0) [0|3] "" Vector__XXX

BO_ 2364730366 HVESP21D4: 8 Vector__XXX
 SG_ Hvesp21DischargeCapacity : 0|16@1+ (0.01,0) [0|642.55] "Ah" Vector__XXX
 SG_ Hvesp21ChargeCapacity : 16|16@1+ (0.01,0) [0|642.55] "Ah" Vector__XXX
 SG_ Hvesp21CellBalancingCount : 32|16@1+ (1,0) [0|64255] "count" Vector__XXX

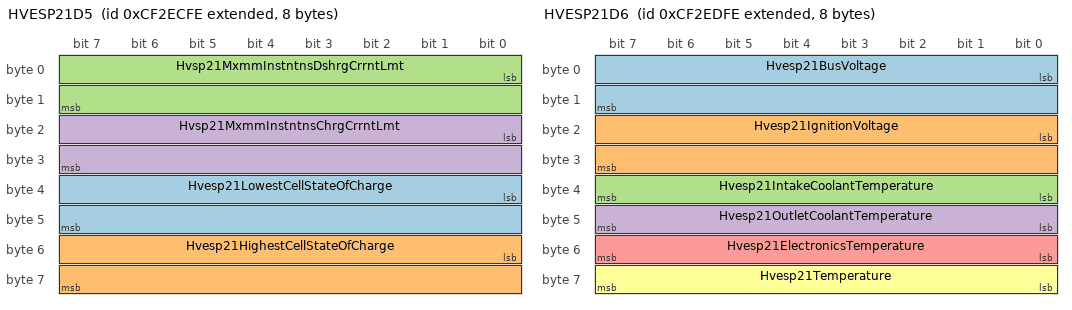
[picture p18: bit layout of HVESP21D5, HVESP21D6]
BO_ 2364730622 HVESP21D5: 8 Vector__XXX
 SG_ Hvesp21LowestCellStateOfCharge : 32|16@1+ (0.0015625,0) [0|100.3984375] "%" Vector__XXX
 SG_ Hvesp21HighestCellStateOfCharge : 48|16@1+ (0.0015625,0) [0|100.3984375] "%" Vector__XXX
 SG_ Hvsp21MxmmInstntnsDshrgCrrntLmt : 0|16@1+ (0.05,-1600) [-1600|0] "A" Vector__XXX
 SG_ Hvsp21MxmmInstntnsChrgCrrntLmt : 16|16@1+ (0.05,-1600) [0|1612.75] "A" Vector__XXX

BO_ 2364730878 HVESP21D6: 8 Vector__XXX
 SG_ Hvesp21BusVoltage : 0|16@1+ (0.05,0) [0|3212.75] "V" Vector__XXX
 SG_ Hvesp21IgnitionVoltage : 16|16@1+ (0.01,0) [0|642.55] "V" Vector__XXX
 SG_ Hvesp21IntakeCoolantTemperature : 32|8@1+ (1,-40) [-40|210] "degC" Vector__XXX
 SG_ Hvesp21OutletCoolantTemperature : 40|8@1+ (1,-40) [-40|210] "degC" Vector__XXX
 SG_ Hvesp21ElectronicsTemperature : 48|8@1+ (1,-40) [-40|210] "degC" Vector__XXX
 SG_ Hvesp21Temperature : 56|8@1+ (1,-40) [-40|210] "degC" Vector__XXX

BO_ 2364731134 HVESP21S1: 8 Vector__XXX
 SG_ Hvsp21HghVltgBsPstvCnttrStt : 0|2@1+ (1,0) [0|3] "" Vector__XXX
 SG_ Hvsp21HghVltgBsNgtvCnttrStt : 2|2@1+ (1,0) [0|3] "" Vector__XXX
 SG_ Hvsp21HghVltgBsDsnntFrwrnng : 4|4@1+ (1,0) [0|15] "" Vector__XXX
 SG_ Hvsp21HghVltgBsPrChrgRlStt : 8|2@1+ (1,0) [0|3] "" Vector__XXX
 SG_ Hvsp21CntrOfPkCnttrStt : 10|2@1+ (1,0) [0|3] "" Vector__XXX
 SG_ Hvsp21HghVltgBsAtvIsltnTstStts : 12|4@1+ (1,0) [0|15] "" Vector__XXX
 SG_ Hvsp21HghVltgBsPssvIsltnTstStts : 16|4@1+ (1,0) [0|15] "" Vector__XXX
 SG_ Hvesp21HvilStatus : 20|2@1+ (1,0) [0|3] "" Vector__XXX
 SG_ Hvesp21InertiaSwitchStatus : 22|2@1+ (1,0) [0|3] "" Vector__XXX
 SG_ Hvesp21StateOfChargeStatus : 24|4@1+ (1,0) [0|15] "" Vector__XXX
 SG_ Hvesp21CellBalanceStatus : 28|2@1+ (1,0) [0|3] "" Vector__XXX
 SG_ Hvesp21CellBalancingActive : 30|2@1+ (1,0) [0|3] "" Vector__XXX
 SG_ Hvesp21InternalChargerStatus : 32|2@1+ (1,0) [0|3] "" Vector__XXX
 SG_ Hvsp21HghVltgBsCnntnStts : 40|4@1+ (1,0) [0|15] "" Vector__XXX
 SG_ Hvesp21OperationalStatus : 44|4@1+ (1,0) [0|15] "" Vector__XXX
 SG_ Hvesp21Status1Counter : 52|4@1+ (1,0) [0|15] "" Vector__XXX
 SG_ Hvesp21Status1Crc : 56|8@1+ (1,0) [0|250] "count" Vector__XXX

BO_ 2364731390 HVESP21D7: 8 Vector__XXX
 SG_ Hvesp21DischargeEnergyCapacity : 0|24@1+ (0.001,0) [0|16449.535] "kWh" Vector__XXX
 SG_ Hvesp21ChargeEnergyCapacity : 24|24@1+ (0.001,0) [0|16449.535] "kWh" Vector__XXX
 SG_ Hvsp21MxmmChrgVltgLmt : 48|16@1+ (0.05,0) [0|3212.75] "V" Vector__XXX

BO_ 2364731646 HVESP21MS1: 8 Vector__XXX
 SG_ Hvesp21Module1OperationalStatus : 0|2@1+ (1,0) [0|3] "" Vector__XXX
 SG_ Hvesp21Module2OperationalStatus : 2|2@1+ (1,0) [0|3] "" Vector__XXX
 SG_ Hvesp21Module3OperationalStatus : 4|2@1+ (1,0) [0|3] "" Vector__XXX
 SG_ Hvesp21Module4OperationalStatus : 6|2@1+ (1,0) [0|3] "" Vector__XXX
 SG_ Hvesp21Module5OperationalStatus : 8|2@1+ (1,0) [0|3] "" Vector__XXX
 SG_ Hvesp21Module6OperationalStatus : 10|2@1+ (1,0) [0|3] "" Vector__XXX
 SG_ Hvesp21Module7OperationalStatus : 12|2@1+ (1,0) [0|3] "" Vector__XXX
 SG_ Hvesp21Module8OperationalStatus : 14|2@1+ (1,0) [0|3] "" Vector__XXX
 SG_ Hvesp21Module9OperationalStatus : 16|2@1+ (1,0) [0|3] "" Vector__XXX
 SG_ Hvsp21Mdl10OprtnlStts : 18|2@1+ (1,0) [0|3] "" Vector__XXX
 SG_ Hvsp21Mdl11OprtnlStts : 20|2@1+ (1,0) [0|3] "" Vector__XXX
 SG_ Hvsp21Mdl12OprtnlStts : 22|2@1+ (1,0) [0|3] "" Vector__XXX
 SG_ Hvsp21Mdl13OprtnlStts : 24|2@1+ (1,0) [0|3] "" Vector__XXX
 SG_ Hvsp21Mdl14OprtnlStts : 26|2@1+ (1,0) [0|3] "" Vector__XXX
 SG_ Hvsp21Mdl15OprtnlStts : 28|2@1+ (1,0) [0|3] "" Vector__XXX
 SG_ Hvsp21Mdl16OprtnlStts : 30|2@1+ (1,0) [0|3] "" Vector__XXX
 SG_ Hvsp21Mdl17OprtnlStts : 32|2@1+ (1,0) [0|3] "" Vector__XXX
 SG_ Hvsp21Mdl18OprtnlStts : 34|2@1+ (1,0) [0|3] "" Vector__XXX
 SG_ Hvsp21Mdl19OprtnlStts : 36|2@1+ (1,0) [0|3] "" Vector__XXX
 SG_ Hvsp21Mdl20OprtnlStts : 38|2@1+ (1,0) [0|3] "" Vector__XXX
 SG_ Hvsp21Mdl21OprtnlStts : 40|2@1+ (1,0) [0|3] "" Vector__XXX
 SG_ Hvsp21Mdl22OprtnlStts : 42|2@1+ (1,0) [0|3] "" Vector__XXX
 SG_ Hvsp21Mdl23OprtnlStts : 44|2@1+ (1,0) [0|3] "" Vector__XXX
 SG_ Hvsp21Mdl24OprtnlStts : 46|2@1+ (1,0) [0|3] "" Vector__XXX
 SG_ Hvsp21Mdl25OprtnlStts : 48|2@1+ (1,0) [0|3] "" Vector__XXX
 SG_ Hvsp21Mdl26OprtnlStts : 50|2@1+ (1,0) [0|3] "" Vector__XXX
 SG_ Hvsp21Mdl27OprtnlStts : 52|2@1+ (1,0) [0|3] "" Vector__XXX
 SG_ Hvsp21Mdl28OprtnlStts : 54|2@1+ (1,0) [0|3] "" Vector__XXX
 SG_ Hvsp21Mdl29OprtnlStts : 56|2@1+ (1,0) [0|3] "" Vector__XXX
 SG_ Hvsp21Mdl30OprtnlStts : 58|2@1+ (1,0) [0|3] "" Vector__XXX
 SG_ Hvsp21Mdl31OprtnlStts : 60|2@1+ (1,0) [0|3] "" Vector__XXX
 SG_ Hvsp21Mdl32OprtnlStts : 62|2@1+ (1,0) [0|3] "" Vector__XXX

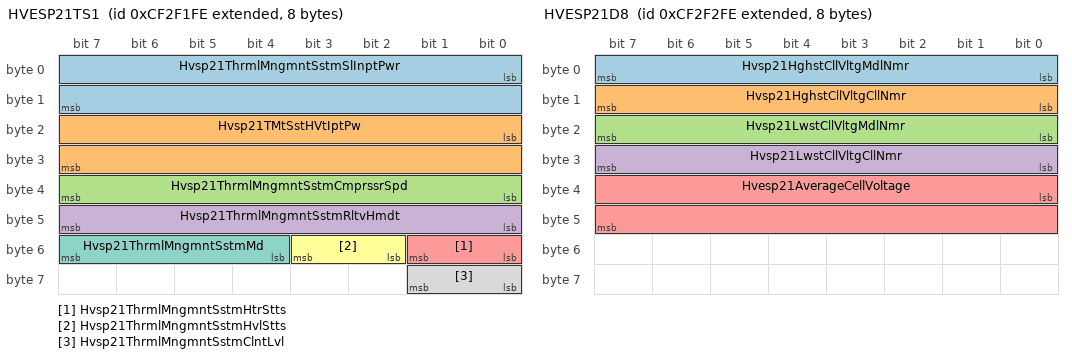
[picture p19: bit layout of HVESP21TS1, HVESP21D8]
BO_ 2364731902 HVESP21TS1: 8 Vector__XXX
 SG_ Hvsp21ThrmlMngmntSstmSlInptPwr : 0|16@1+ (0.5,0) [0|32127.5] "W" Vector__XXX
 SG_ Hvsp21TMtSstHVtIptPw : 16|16@1+ (0.5,0) [0|32127.5] "W" Vector__XXX
 SG_ Hvsp21ThrmlMngmntSstmCmprssrSpd : 32|8@1+ (32,0) [0|8000] "rpm" Vector__XXX
 SG_ Hvsp21ThrmlMngmntSstmRltvHmdt : 40|8@1+ (0.4,0) [0|100] "%" Vector__XXX
 SG_ Hvsp21ThrmlMngmntSstmHtrStts : 48|2@1+ (1,0) [0|3] "" Vector__XXX
 SG_ Hvsp21ThrmlMngmntSstmHvlStts : 50|2@1+ (1,0) [0|3] "" Vector__XXX
 SG_ Hvsp21ThrmlMngmntSstmMd : 52|4@1+ (1,0) [0|15] "" Vector__XXX
 SG_ Hvsp21ThrmlMngmntSstmClntLvl : 56|2@1+ (1,0) [0|3] "" Vector__XXX

BO_ 2364732158 HVESP21D8: 8 Vector__XXX
 SG_ Hvsp21HghstCllVltgMdlNmr : 0|8@1+ (1,0) [0|250] "count" Vector__XXX
 SG_ Hvsp21HghstCllVltgCllNmr : 8|8@1+ (1,0) [0|250] "count" Vector__XXX
 SG_ Hvsp21LwstCllVltgMdlNmr : 16|8@1+ (1,0) [0|250] "count" Vector__XXX
 SG_ Hvsp21LwstCllVltgCllNmr : 24|8@1+ (1,0) [0|250] "count" Vector__XXX
 SG_ Hvesp21AverageCellVoltage : 32|16@1+ (0.001,0) [0|64.255] "V" Vector__XXX

CM_ BO_ 2364718590 "High Voltage Energy Storage Pack 18 Data 3";
CM_ SG_ 2364718590 Hvesp18HighestCellTemperature "HVESP18 Highest Cell Temperature: The highest temperature level reported by any cell in this High Voltage Energy Storage Pack instance. If a single temperature sensor covers more than one cell, the value in this parameter is for the smallest group of...";
CM_ SG_ 2364718590 Hvesp18LowestCellTemperature "HVESP18 Lowest Cell Temperature: The lowest temperature level reported by any cell in this High Voltage Energy Storage Pack instance. If a single temperature sensor covers more than one cell, the value in this parameter is for the smallest group of c...";
CM_ SG_ 2364718590 Hvesp18AverageCellTemperature "HVESP18 Average Cell Temperature: The average temperature level of all cells in this High Voltage Energy Storage Pack instance.This parameter is for one of multiple packs in an HVESS.  If there is only one pack in the system, the HVESS parameters sho...";
CM_ SG_ 2364718590 Hvsp18CllTmprtrDffrntlStts "HVESP18 Cell Temperature Differential Status: Indicates whether or not the differential between the highest and lowest cell temperatures are within acceptable limits per this High Voltage Energy Storage Pack instance. The actual temperature different...";
CM_ BO_ 2364718846 "High Voltage Energy Storage Pack 18 Data 4";
CM_ SG_ 2364718846 Hvesp18DischargeCapacity "HVESP18 Discharge Capacity: The amount of stored electrical charge in this High Voltage Energy Storage Pack instance that is available for use by the hybrid or EV system, i.e. 'how full is the tank'. See SPN 16328 (HVESP18 Discharge Energy Capacity) ...";
CM_ SG_ 2364718846 Hvesp18ChargeCapacity "HVESP18 Charge Capacity: The amount of unused electrical charge storage in this High Voltage Energy Storage Pack instance that is available to be filled by charging, i.e. 'how much empty space is remaining in the tank'. See SPN 16329 (HVESP18 Charge ...";
CM_ SG_ 2364718846 Hvesp18CellBalancingCount "HVESP18 Cell Balancing Count: The number of cells that are currently being balanced in this High Voltage Energy Storage Pack instance.This parameter is for one of multiple packs in an HVESS.  If there is only one pack in the system, the HVESS paramet...";
CM_ BO_ 2364719102 "High Voltage Energy Storage Pack 18 Data 5";
CM_ SG_ 2364719102 Hvesp18LowestCellStateOfCharge "HVESP18 Lowest Cell State of Charge: Indicates the state of charge of the lowest-charged cell in this High Voltage Energy Storage Pack instance. 0% means no charge remaining, 100% means the cell is fully charged. If a single state of charge value cov...";
CM_ SG_ 2364719102 Hvesp18HighestCellStateOfCharge "HVESP18 Highest Cell State of Charge: Indicates the state of charge of the highest-charged cell in this High Voltage Energy Storage Pack instance. 0% means no charge remaining, 100% means the cell is fully charged. If a single state of charge value c...";
CM_ SG_ 2364719102 Hvsp18MxmmInstntnsDshrgCrrntLmt "HVESP18 Maximum Instantaneous Discharge Current Limit: The maximum instantaneous current flow limit out of this High Voltage Energy Storage Pack instance. This parameter is defined from the high voltage energy storage pack's point of view and should ...";
CM_ SG_ 2364719102 Hvsp18MxmmInstntnsChrgCrrntLmt "HVESP18 Maximum Instantaneous Charge Current Limit: The maximum instantaneous current flow limit into this High Voltage Energy Storage Pack instance. This parameter is defined from the high voltage energy storage pack's point of view and should refle...";
CM_ BO_ 2364719358 "High Voltage Energy Storage Pack 18 Data 6";
CM_ SG_ 2364719358 Hvesp18BusVoltage "HVESP18 Bus Voltage: The voltage level of the high voltage bus, as measured by this High Voltage Energy Storage Pack instance on the bus side (not the battery side) of its contactors.This parameter is for one of multiple packs in an HVESS.  If there ...";
CM_ SG_ 2364719358 Hvesp18IgnitionVoltage "HVESP18 Ignition Voltage: The voltage level at the ignition input of this High Voltage Energy Storage Pack controller.This parameter is for one of multiple packs in an HVESS.  If there is only one pack in the system, the HVESS parameters should be us...";
CM_ SG_ 2364719358 Hvesp18IntakeCoolantTemperature "HVESP18 Intake Coolant Temperature: The temperature of liquid coolant as it enters this High Voltage Energy Storage Pack instance.This parameter is for one of multiple packs in an HVESS.  If there is only one pack in the system, the HVESS parameters ...";
CM_ SG_ 2364719358 Hvesp18OutletCoolantTemperature "HVESP18 Outlet Coolant Temperature: The temperature of liquid coolant as it exits this High Voltage Energy Storage Pack instance.This parameter is for one of multiple packs in an HVESS.  If there is only one pack in the system, the HVESS parameters s...";
CM_ SG_ 2364719358 Hvesp18ElectronicsTemperature "HVESP18 Electronics Temperature: The temperature of the electronics or control modules in this High Voltage Energy Storage Pack instance.  If there are multiple temperature sensors then this parameter would be set to the maximum sensor reading.This p...";
CM_ SG_ 2364719358 Hvesp18Temperature "HVESP18 Temperature: The temperature of this High Voltage Energy Storage Pack instance. The value may be determined from a unique sensor specifically for this purpose, or by aggregating various temperature sensor readings within the pack.This paramet...";
CM_ BO_ 2364719614 "High Voltage Energy Storage Pack 18 Status 1";
CM_ SG_ 2364719614 Hvsp18HghVltgBsPstvCnttrStt "HVESP18 High-Voltage Bus (Positive) Contactor State: Position of this High Voltage Energy Storage Pack instance positive side bus contactor.  When this contactor is closed, the positive side of this HVES instance is connected to the positive side of ...";
CM_ SG_ 2364719614 Hvsp18HghVltgBsNgtvCnttrStt "HVESP18 High-Voltage Bus (Negative) Contactor State: Position of this High Voltage Energy Storage Pack instance negative side bus contactor. When this contactor is closed, the negative side of this HVES instance is connected to the negative side of t...";
CM_ SG_ 2364719614 Hvsp18HghVltgBsDsnntFrwrnng "HVESP18 High-Voltage Bus Disconnect Forewarning: Indicates that this High Voltage Energy Storage Pack instance is about to disconnect from the high voltage bus due to unacceptable conditions.This parameter is for one of multiple packs in an HVESS. If...";
CM_ SG_ 2364719614 Hvsp18HghVltgBsPrChrgRlStt "HVESP18 High-Voltage Bus Pre-Charge Relay State: Position of the high-voltage bus contactor pre-charge relay.  When this relay is closed, this High Voltage Energy Storage Pack instance is bringing the high-voltage bus up to its operating level.This p...";
CM_ SG_ 2364719614 Hvsp18CntrOfPkCnttrStt "HVESP18 Center of Pack Contactor State: Position of the center high-voltage contactor. When this contactor is closed, the positive half of this High Voltage Energy Storage Pack instance is connected to the negative half. If a system controls the posi...";
CM_ SG_ 2364719614 Hvsp18HghVltgBsAtvIsltnTstStts "HVESP18 High-Voltage Bus Active Isolation Test Status: Status of the high-voltage bus electrical active isolation test as performed by this High Voltage Energy Storage Pack instance.This parameter is for one of multiple packs in an HVESS. If there is...";
CM_ SG_ 2364719614 Hvsp18HghVltgBsPssvIsltnTstStts "HVESP18 High-Voltage Bus Passive Isolation Test Status: Status of the high-voltage bus electrical passive isolation test as performed by this High Voltage Energy Storage Pack instance.This parameter is for one of multiple packs in an HVESS. If there ...";
CM_ SG_ 2364719614 Hvesp18HvilStatus "HVESP18 HVIL Status: Status of the High Voltage Interlock Loop from the viewpoint of this High Voltage Energy Storage Pack instance.This parameter is for one of multiple packs in an HVESS. If there is only one pack in the system, the HVESS parameters...";
CM_ SG_ 2364719614 Hvesp18InertiaSwitchStatus "HVESP18 Inertia Switch Status: Switch indicating that an impact has been sensed by this High Voltage Energy Storage Pack instance. The impact indication may require action by another controller, or by this HVES instance itself.  For example, a contro...";
CM_ SG_ 2364719614 Hvesp18StateOfChargeStatus "HVESP18 State of Charge Status: Status of this High Voltage Energy Storage Pack instance State of Charge (SOC).  Note:  A given HVES controller may not support all of the states.This parameter is for one of multiple packs in an HVESS.  If there is on...";
CM_ SG_ 2364719614 Hvesp18CellBalanceStatus "HVESP18 Cell Balance Status: Indicates whether or not the cells in this High Voltage Energy Storage Pack instance are balanced.This parameter is for one of multiple packs in an HVESS.  If there is only one pack in the system, the HVESS parameters sho...";
CM_ SG_ 2364719614 Hvesp18CellBalancingActive "HVESP18 Cell Balancing Active: Indicates whether or not the cells in this High Voltage Energy Storage Pack instance are currently being balanced.This parameter is for one of multiple packs in an HVESS.  If there is only one pack in the system, the HV...";
CM_ SG_ 2364719614 Hvesp18InternalChargerStatus "HVESP18 Internal Charger Status: Indicates that the charger in this HVES instance is on.  External chargers may use the External Energy Source Connection Status (SPN 7898) and related SPs.This parameter is for one of multiple packs in an HVESS. If th...";
CM_ SG_ 2364719614 Hvsp18HghVltgBsCnntnStts "HVESP18 High-Voltage Bus Connection Status: This parameter provides high level feedback on this High Voltage Energy Storage Pack instance high voltage bus connection. For specific contactor information, see SPN 16311 (HVESP18 High-Voltage Bus (Positi...";
CM_ SG_ 2364719614 Hvesp18OperationalStatus "HVESP18 Operational Status: Provides feedback on where this High Voltage Energy Storage Pack instance is in its operating spectrum, and includes feedback in response to the Operation Consent [i.e. SPN 16269 (HVESP18 Operation Consent)] and Power Down...";
CM_ SG_ 2364719614 Hvesp18Status1Counter "HVESP18 Status 1 Counter: The message counter is used to detect situations where the transmitting ECU malfunction repeats the same frame all the time. The receiver of the information may use the counter parameter to detect this situation. The transmi...";
CM_ SG_ 2364719614 Hvesp18Status1Crc "HVESP18 Status 1 CRC: The CRC is defined as follows: - Length: 8 bits- Polynomial: x^8+x^5+x^3+x^2+x+1- Initial Value: FFh- Input Data Reflection: Not reflected- Result Data Reflection: Not reflected- XOR value: FFh SAE makes no claim of the function...";
CM_ BO_ 2364719870 "High Voltage Energy Storage Pack 18 Data 7";
CM_ SG_ 2364719870 Hvesp18DischargeEnergyCapacity "HVESP18 Discharge Energy Capacity: The amount of stored electrical energy in this High Voltage Energy Storage Pack instance that is available for use by the hybrid or EV system, i.e. 'how full is the tank'. See SPN 16298 (HVESP18 Discharge Capacity) ...";
CM_ SG_ 2364719870 Hvesp18ChargeEnergyCapacity "HVESP18 Charge Energy Capacity: The amount of unused electrical energy storage available to be filled by charging this High Voltage Energy Storage Pack instance, i.e. 'how much empty space is remaining in the tank'. See SPN 16299 (HVESP18 Charge Capa...";
CM_ SG_ 2364719870 Hvsp18MxmmChrgVltgLmt "HVESP18 Maximum Charge Voltage Limit: The maximum voltage level not to be exceeded while charging this High Voltage Energy Storage Pack instance. If this parameter is not supported, the maximum charge voltage should be limited to SPN 16397 (HVESP18 R...";
CM_ BO_ 2364720126 "High Voltage Energy Storage Pack 18 Module Status 1";
CM_ SG_ 2364720126 Hvesp18Module1OperationalStatus "HVESP18 Module 1 Operational Status: Operational Status of Module 1 in this High Voltage Energy Storage Pack Instance.  Not Operational is used when the module is initializing or not able to function (e.g. internal module level monitors have failed)....";
CM_ SG_ 2364720126 Hvesp18Module2OperationalStatus "HVESP18 Module 2 Operational Status: Operational Status of Module 2 in this High Voltage Energy Storage Pack Instance.  Not Operational is used when the module is initializing or not able to function (e.g. internal module level monitors have failed)....";
CM_ SG_ 2364720126 Hvesp18Module3OperationalStatus "HVESP18 Module 3 Operational Status: Operational Status of Module 3 in this High Voltage Energy Storage Pack Instance.  Not Operational is used when the module is initializing or not able to function (e.g. internal module level monitors have failed)....";
CM_ SG_ 2364720126 Hvesp18Module4OperationalStatus "HVESP18 Module 4 Operational Status: Operational Status of Module 4 in this High Voltage Energy Storage Pack Instance.  Not Operational is used when the module is initializing or not able to function (e.g. internal module level monitors have failed)....";
CM_ SG_ 2364720126 Hvesp18Module5OperationalStatus "HVESP18 Module 5 Operational Status: Operational Status of Module 5 in this High Voltage Energy Storage Pack Instance.  Not Operational is used when the module is initializing or not able to function (e.g. internal module level monitors have failed)....";
CM_ SG_ 2364720126 Hvesp18Module6OperationalStatus "HVESP18 Module 6 Operational Status: Operational Status of Module 6 in this High Voltage Energy Storage Pack Instance.  Not Operational is used when the module is initializing or not able to function (e.g. internal module level monitors have failed)....";
CM_ SG_ 2364720126 Hvesp18Module7OperationalStatus "HVESP18 Module 7 Operational Status: Operational Status of Module 7 in this High Voltage Energy Storage Pack Instance.  Not Operational is used when the module is initializing or not able to function (e.g. internal module level monitors have failed)....";
CM_ SG_ 2364720126 Hvesp18Module8OperationalStatus "HVESP18 Module 8 Operational Status: Operational Status of Module 8 in this High Voltage Energy Storage Pack Instance.  Not Operational is used when the module is initializing or not able to function (e.g. internal module level monitors have failed)....";
CM_ SG_ 2364720126 Hvesp18Module9OperationalStatus "HVESP18 Module 9 Operational Status: Operational Status of Module 9 in this High Voltage Energy Storage Pack Instance.  Not Operational is used when the module is initializing or not able to function (e.g. internal module level monitors have failed)....";
CM_ SG_ 2364720126 Hvsp18Mdl10OprtnlStts "HVESP18 Module 10 Operational Status: Operational Status of Module 10 in this High Voltage Energy Storage Pack Instance.  Not Operational is used when the module is initializing or not able to function (e.g. internal module level monitors have failed...";
CM_ SG_ 2364720126 Hvsp18Mdl11OprtnlStts "HVESP18 Module 11 Operational Status: Operational Status of Module 11 in this High Voltage Energy Storage Pack Instance.  Not Operational is used when the module is initializing or not able to function (e.g. internal module level monitors have failed...";
CM_ SG_ 2364720126 Hvsp18Mdl12OprtnlStts "HVESP18 Module 12 Operational Status: Operational Status of Module 12 in this High Voltage Energy Storage Pack Instance.  Not Operational is used when the module is initializing or not able to function (e.g. internal module level monitors have failed...";
CM_ SG_ 2364720126 Hvsp18Mdl13OprtnlStts "HVESP18 Module 13 Operational Status: Operational Status of Module 13 in this High Voltage Energy Storage Pack Instance.  Not Operational is used when the module is initializing or not able to function (e.g. internal module level monitors have failed...";
CM_ SG_ 2364720126 Hvsp18Mdl14OprtnlStts "HVESP18 Module 14 Operational Status: Operational Status of Module 14 in this High Voltage Energy Storage Pack Instance.  Not Operational is used when the module is initializing or not able to function (e.g. internal module level monitors have failed...";
CM_ SG_ 2364720126 Hvsp18Mdl15OprtnlStts "HVESP18 Module 15 Operational Status: Operational Status of Module 15 in this High Voltage Energy Storage Pack Instance.  Not Operational is used when the module is initializing or not able to function (e.g. internal module level monitors have failed...";
CM_ SG_ 2364720126 Hvsp18Mdl16OprtnlStts "HVESP18 Module 16 Operational Status: Operational Status of Module 16 in this High Voltage Energy Storage Pack Instance.  Not Operational is used when the module is initializing or not able to function (e.g. internal module level monitors have failed...";
CM_ SG_ 2364720126 Hvsp18Mdl17OprtnlStts "HVESP18 Module 17 Operational Status: Operational Status of Module 17 in this High Voltage Energy Storage Pack Instance.  Not Operational is used when the module is initializing or not able to function (e.g. internal module level monitors have failed...";
CM_ SG_ 2364720126 Hvsp18Mdl18OprtnlStts "HVESP18 Module 18 Operational Status: Operational Status of Module 18 in this High Voltage Energy Storage Pack Instance.  Not Operational is used when the module is initializing or not able to function (e.g. internal module level monitors have failed...";
CM_ SG_ 2364720126 Hvsp18Mdl19OprtnlStts "HVESP18 Module 19 Operational Status: Operational Status of Module 19 in this High Voltage Energy Storage Pack Instance.  Not Operational is used when the module is initializing or not able to function (e.g. internal module level monitors have failed...";
CM_ SG_ 2364720126 Hvsp18Mdl20OprtnlStts "HVESP18 Module 20 Operational Status: Operational Status of Module 20 in this High Voltage Energy Storage Pack Instance.  Not Operational is used when the module is initializing or not able to function (e.g. internal module level monitors have failed...";
CM_ SG_ 2364720126 Hvsp18Mdl21OprtnlStts "HVESP18 Module 21 Operational Status: Operational Status of Module 21 in this High Voltage Energy Storage Pack Instance.  Not Operational is used when the module is initializing or not able to function (e.g. internal module level monitors have failed...";
CM_ SG_ 2364720126 Hvsp18Mdl22OprtnlStts "HVESP18 Module 22 Operational Status: Operational Status of Module 22 in this High Voltage Energy Storage Pack Instance.  Not Operational is used when the module is initializing or not able to function (e.g. internal module level monitors have failed...";
CM_ SG_ 2364720126 Hvsp18Mdl23OprtnlStts "HVESP18 Module 23 Operational Status: Operational Status of Module 23 in this High Voltage Energy Storage Pack Instance.  Not Operational is used when the module is initializing or not able to function (e.g. internal module level monitors have failed...";
CM_ SG_ 2364720126 Hvsp18Mdl24OprtnlStts "HVESP18 Module 24 Operational Status: Operational Status of Module 24 in this High Voltage Energy Storage Pack Instance.  Not Operational is used when the module is initializing or not able to function (e.g. internal module level monitors have failed...";
CM_ SG_ 2364720126 Hvsp18Mdl25OprtnlStts "HVESP18 Module 25 Operational Status: Operational Status of Module 25 in this High Voltage Energy Storage Pack Instance.  Not Operational is used when the module is initializing or not able to function (e.g. internal module level monitors have failed...";
CM_ SG_ 2364720126 Hvsp18Mdl26OprtnlStts "HVESP18 Module 26 Operational Status: Operational Status of Module 26 in this High Voltage Energy Storage Pack Instance.  Not Operational is used when the module is initializing or not able to function (e.g. internal module level monitors have failed...";
CM_ SG_ 2364720126 Hvsp18Mdl27OprtnlStts "HVESP18 Module 27 Operational Status: Operational Status of Module 27 in this High Voltage Energy Storage Pack Instance.  Not Operational is used when the module is initializing or not able to function (e.g. internal module level monitors have failed...";
CM_ SG_ 2364720126 Hvsp18Mdl28OprtnlStts "HVESP18 Module 28 Operational Status: Operational Status of Module 28 in this High Voltage Energy Storage Pack Instance.  Not Operational is used when the module is initializing or not able to function (e.g. internal module level monitors have failed...";
CM_ SG_ 2364720126 Hvsp18Mdl29OprtnlStts "HVESP18 Module 29 Operational Status: Operational Status of Module 29 in this High Voltage Energy Storage Pack Instance.  Not Operational is used when the module is initializing or not able to function (e.g. internal module level monitors have failed...";
CM_ SG_ 2364720126 Hvsp18Mdl30OprtnlStts "HVESP18 Module 30 Operational Status: Operational Status of Module 30 in this High Voltage Energy Storage Pack Instance.  Not Operational is used when the module is initializing or not able to function (e.g. internal module level monitors have failed...";
CM_ SG_ 2364720126 Hvsp18Mdl31OprtnlStts "HVESP18 Module 31 Operational Status: Operational Status of Module 31 in this High Voltage Energy Storage Pack Instance.  Not Operational is used when the module is initializing or not able to function (e.g. internal module level monitors have failed...";
CM_ SG_ 2364720126 Hvsp18Mdl32OprtnlStts "HVESP18 Module 32 Operational Status: Operational Status of Module 32 in this High Voltage Energy Storage Pack Instance.  Not Operational is used when the module is initializing or not able to function (e.g. internal module level monitors have failed...";
CM_ BO_ 2364720382 "High Voltage Energy Storage Pack 18 Thermal Management System Status 1";
CM_ SG_ 2364720382 Hvsp18ThrmlMngmntSstmSlInptPwr "HVESP18 Thermal Management System SLI Input Power: This is the low-voltage power consumed by this HVES Thermal Management System (TMS).This parameter is for one of multiple packs in an HVESS.  If there is only one pack in the system, the HVESS parame...";
CM_ SG_ 2364720382 Hvsp18TMtSstHVtIptPw "HVESP18 Thermal Management System High-Voltage Input Power: This is the high-voltage power consumed by this HVES Thermal Management System (TMS).This parameter is for one of multiple packs in an HVESS.  If there is only one pack in the system, the HV...";
CM_ SG_ 2364720382 Hvsp18ThrmlMngmntSstmCmprssrSpd "HVESP18 Thermal Management System Compressor Speed: When this High Voltage Energy Storage Pack Thermal Management System is equipped with an active cooling system (e.g. air conditioner), this is the Compressor Speed.This parameter is for one of multi...";
CM_ SG_ 2364720382 Hvsp18ThrmlMngmntSstmRltvHmdt "HVESP18 Thermal Management System Relative Humidty: When this High Voltage Energy Storage Pack Thermal Management System is equipped with a relative humidity sensor, this is the  measured Relative Humidity.This parameter is for one of multiple packs ...";
CM_ SG_ 2364720382 Hvsp18ThrmlMngmntSstmHtrStts "HVESP18 Thermal Management System Heater Status: The state of this High Voltage Energy Storage Pack heaterThis parameter is for one of multiple packs in an HVESS.  If there is only one pack in the system, the HVESS parameters should be used. If there...";
CM_ SG_ 2364720382 Hvsp18ThrmlMngmntSstmHvlStts "HVESP18 Thermal Management System HVIL Status: In multiple HVES configurations, this is the status of the High Voltage Interlock Loop from the viewpoint of this Thermal Management System.00b = HVIL Closed01b = HVIL Open10b = Error11b = Not AvailableT...";
CM_ SG_ 2364720382 Hvsp18ThrmlMngmntSstmMd "HVESP18 Thermal Management System Mode: Indicates the operating mode of the Thermal Management System.  The heat transfer medium may be (e.g. liquid or air).  The cooling system may be fans, liquid coolant, or a combination of mediums.  The system ma...";
CM_ SG_ 2364720382 Hvsp18ThrmlMngmntSstmClntLvl "HVESP18 Thermal Management System Coolant Level: Indicates the coolant level in this HVES Thermal Management System (TMS).This parameter is for one of multiple packs in an HVESS.  If there is only one pack in the system, the HVESS parameters should b...";
CM_ BO_ 2364720638 "High Voltage Energy Storage Pack 18 Data 8";
CM_ SG_ 2364720638 Hvsp18HghstCllVltgMdlNmr "HVESP18 Highest Cell Voltage Module Number: Identifies the location of the module containing SPN 16291 (HVESP18 Highest Cell Voltage).This parameter is for one of multiple packs in an HVESS. If there is only one pack in the system, the HVESS paramete...";
CM_ SG_ 2364720638 Hvsp18HghstCllVltgCllNmr "HVESP18 Highest Cell Voltage Cell Number: Identifies the location of SPN 16291 (HVESP18 Highest Cell Voltage) within SPN 16371 (HVESP18 Highest Cell Voltage Module Number).This parameter is for one of multiple packs in an HVESS. If there is only one ...";
CM_ SG_ 2364720638 Hvsp18LwstCllVltgMdlNmr "HVESP18 Lowest Cell Voltage Module Number: Identifies the location of the module containing SPN 16292 (HVESP18 Lowest Cell Voltage).This parameter is for one of multiple packs in an HVESS. If there is only one pack in the system, the HVESS parameters...";
CM_ SG_ 2364720638 Hvsp18LwstCllVltgCllNmr "HVESP18 Lowest Cell Voltage Cell Number: Identifies the location of SPN 16292 (HVESP18 Lowest Cell Voltage) within SPN 16373 (HVESP18 Lowest Cell Voltage Module Number).This parameter is for one of multiple packs in an HVESS. If there is only one pac...";
CM_ SG_ 2364720638 Hvesp18AverageCellVoltage "HVESP18 Average Cell Voltage: The average cell voltage in this High Voltage Energy Storage Pack instance.This parameter is for one of multiple packs in an HVESS.  If there is only one pack in the system, the HVESS parameters should be used. If there ...";
CM_ BO_ 2364720894 "High Voltage Energy Storage Pack 18 Data 9";
CM_ SG_ 2364720894 Hvsp18HghstCllTmprtrMdlNmr "HVESP18 Highest Cell Temperature Module Number: Identifies the location of the module containing SPN 16294 (HVESP18 Highest Cell Temperature).This parameter is for one of multiple packs in an HVESS. If there is only one pack in the system, the HVESS ...";
CM_ SG_ 2364720894 Hvsp18HghstCllTmprtrCllNmr "HVESP18 Highest Cell Temperature Cell Number: Identifies the location of SPN 16294 (HVESP18 Highest Cell Temperature) within SPN 16376 (HVESP18 Highest Cell Temperature Module Number).This parameter is for one of multiple packs in an HVESS. If there ...";
CM_ SG_ 2364720894 Hvsp18LwstCllTmprtrMdlNmr "HVESP18 Lowest Cell Temperature Module Number: Identifies the location of the module containing SPN 16295 (HVESP18 Lowest Cell Temperature).This parameter is for one of multiple packs in an HVESS. If there is only one pack in the system, the HVESS pa...";
CM_ SG_ 2364720894 Hvsp18LwstCllTmprtrCllNmr "HVESP18 Lowest Cell Temperature Cell Number: Identifies the location of SPN 16295 (HVESP18 Lowest Cell Temperature) within SPN 16378 (HVESP18 Lowest Cell Temperature Module Number).This parameter is for one of multiple packs in an HVESS. If there is ...";
CM_ SG_ 2364720894 Hvess18ThermalEventDetected "HVESS18 Thermal Event Detected: A sensor has detected the presence of a thermal event at or near High Voltage Energy Storage Pack instance.00b = No Thermal Event Detected01b = Thermal Event Detected10b = Error11b = Not availableThis parameter is for ...";
CM_ SG_ 2364720894 Hvsp18Dt9EmdddIntgrtSpprt "HVESP18 Data 9 Embedded Integrity Support: Indicates SPN 23027 (HVESP18 Data 9 CRC) and SPN 23026 (HVESP18 Data 9 Counter) are supported by the sender.00b = Embedded CRC and Counter are supported by the sender01b = Protection is provided using an ext...";
CM_ SG_ 2364720894 Hvesp18Data9Counter "HVESP18 Data 9 Counter: The message counter is used to detect situations where the transmitting ECU malfunction repeats the same frame all the time. The receiver of the information may use the counter parameter to detect this situation. The transmitt...";
CM_ SG_ 2364720894 Hvesp18Data9Crc "HVESP18 Data 9 CRC: The CRC is defined as follows: - Length: 8 bits- Polynomial: x^8+x^5+x^3+x^2+x+1- Initial Value: FFh- Input Data Reflection: Not reflected- Result Data Reflection: Not reflected- XOR value: FFh SAE makes no claim of the functional...";
CM_ BO_ 2364721150 "High Voltage Energy Storage Pack 18 Data 10";
CM_ SG_ 2364721150 Hvsp18HghstCllSttOfChrgMdlNmr "HVESP18 Highest Cell State of Charge Module Number: Identifies the location of the module containing SPN 16304 (HVESP18 Highest Cell State of Charge).This parameter is for one of multiple packs in an HVESS. If there is only one pack in the system, th...";
CM_ SG_ 2364721150 Hvsp18HghstCllSttOfChrgCllNmr "HVESP18 Highest Cell State of Charge Cell Number: Identifies the location of SPN 16304 (HVESP18 Highest Cell State of Charge) within SPN 16380 (HVESP18 Highest Cell State of Charge Module Number).This parameter is for one of multiple packs in an HVES...";
CM_ SG_ 2364721150 Hvsp18LwstCllSttOfChrgMdlNmr "HVESP18 Lowest Cell State of Charge Module Number: Identifies the location of the module containing SPN 16303 (HVESP18 Lowest Cell State of Charge).This parameter is for one of multiple packs in an HVESS. If there is only one pack in the system, the ...";
CM_ SG_ 2364721150 Hvsp18LwstCllSttOfChrgCllNmr "HVESP18 Lowest Cell State of Charge Cell Number: Identifies the location of SPN 16303 (HVESP18 Lowest Cell State of Charge) within SPN 16382 (HVESP18 Lowest Cell State of Charge Module Number).This parameter is for one of multiple packs in an HVESS. ...";
CM_ SG_ 2364721150 Hvsp18HghVltgBsAtvIsltnTstRslts "HVESP18 High-Voltage Bus Active Isolation Test Results: The isolation resistance expressed in Ohms per Volt that resulted from the High-Voltage Bus Active Isolation Test.See SPN 16316 (HVESP18 High-Voltage Bus Active Isolation Test Status) for test s...";
CM_ SG_ 2364721150 Hvsp18HVtBsPssvIstTstRsts "HVESP18 High-Voltage Bus Passive Isolation Test Results: The isolation resistance expressed in Ohms per Volt that resulted from the High-Voltage Bus Passive Isolation Test.See SPN 16317 (HVESP18 High-Voltage Bus Passive Isolation Test Status) for tes...";
CM_ BO_ 2364721406 "High Voltage Energy Storage Pack 18 Data 11";
CM_ SG_ 2364721406 Hvsp18BsVltgNgtvTChsssGrndVltg "HVESP18 Bus Voltage Negative to Chassis Ground Voltage: Voltage difference between the most negative terminal of the HVES battery and chassis measured on the hybrid or EV system bus side (not the battery side) of any HVES contained output contactor. ...";
CM_ SG_ 2364721406 Hvsp18VltgLvlNgtvTChsssGrndVltg "HVESP18 Voltage Level Negative to Chassis Ground Voltage: Voltage difference between the most negative terminal of the HVES battery and chassis measured at the battery side of any HVES contained output contactor.  This voltage may be used for system ...";
CM_ SG_ 2364721406 Hvesp18ActualChargeRate "HVESP18 Actual Charge Rate: This signal represents the actual present charge rate of this High Voltage Energy Storage Pack instance.This parameter is for one of multiple packs in an HVESS. If there is only one pack in the system, the HVESS parameters...";
CM_ BO_ 2364721662 "High Voltage Energy Storage Pack 19 Status 2";
CM_ SG_ 2364721662 Hvsp19DshrgPwrLmtDTSttOfChrg "HVESP19 Discharge Power Limit Due to State of Charge: Indicates whether or not discharge power of this HVES instance is being limited due to state of charge.This parameter is for one of multiple packs in an HVESS.  If there is only one pack in the sy...";
CM_ SG_ 2364721662 Hvsp19DshrgPwrLmtDTBttrTmprtr "HVESP19 Discharge Power Limit Due to Battery Temperature: Indicates whether or not discharge power of this HVES instance is being limited due to battery temperature.This parameter is for one of multiple packs in an HVESS.  If there is only one pack i...";
CM_ SG_ 2364721662 Hvsp19DsPwLtDTBttDstCdt "HVESP19 Discharge Power Limit Due to Battery Diagnostic Condition: Indicates whether or not discharge power of this HVES instance is being limited due to a battery diagnostic condition.This parameter is for one of multiple packs in an HVESS.  If ther...";
CM_ SG_ 2364721662 Hvsp19DsPwLtDTBttOCVt "HVESP19 Discharge Power Limit Due to Battery or Cell Voltage: Indicates whether or not discharge power of this HVES instance is being limited due to a battery or cell voltage level.This parameter is for one of multiple packs in an HVESS.  If there is...";
CM_ SG_ 2364721662 Hvsp19DshrgPwrLmtDTBttrCrrnt "HVESP19 Discharge Power Limit Due to Battery Current: Indicates whether or not discharge power of this HVES instance is being limited due to battery current.This parameter is for one of multiple packs in an HVESS.  If there is only one pack in the sy...";
CM_ SG_ 2364721662 Hvsp19DshrgPwrLmtDTAnUndfndCs "HVESP19 Discharge Power Limit Due to an Undefined Cause: Indicates whether or not discharge power of this HVES instance is being limited due to an undefined cause.This parameter is for one of multiple packs in an HVESS.  If there is only one pack in ...";
CM_ SG_ 2364721662 Hvsp19ChrgPwrLmtDTSttOfChrg "HVESP19 Charge Power Limit Due to State of Charge: Indicates whether or not charge power of this HVES instance is being limited due to state of charge.This parameter is for one of multiple packs in an HVESS.  If there is only one pack in the system, ...";
CM_ SG_ 2364721662 Hvsp19ChrgPwrLmtDTBttrTmprtr "HVESP19 Charge Power Limit Due to Battery Temperature: Indicates whether or not charge power of this HVES instance is being limited due to battery temperature.This parameter is for one of multiple packs in an HVESS.  If there is only one pack in the ...";
CM_ SG_ 2364721662 Hvsp19CPwLtDTBttDstCdt "HVESP19 Charge Power Limit Due to Battery Diagnostic Condition: Indicates whether or not charge power of this HVES instance is being limited due to a battery diagnostic condition.This parameter is for one of multiple packs in an HVESS.  If there is o...";
CM_ SG_ 2364721662 Hvsp19ChrgPwrLmtDTBttrOrCllVltg "HVESP19 Charge Power Limit Due to Battery or Cell Voltage: Indicates whether or not charge power of this HVES instance is being limited due to a battery or cell voltage level.This parameter is for one of multiple packs in an HVESS.  If there is only ...";
CM_ SG_ 2364721662 Hvsp19ChrgPwrLmtDTBttrCrrnt "HVESP19 Charge Power Limit Due to Battery Current: Indicates whether or not charge power of this HVES instance is being limited due to battery current.This parameter is for one of multiple packs in an HVESS.  If there is only one pack in the system, ...";
CM_ SG_ 2364721662 Hvsp19ChrgPwrLmtDTAnUndfndCs "HVESP19 Charge Power Limit Due to an Undefined Cause: Indicates whether or not charge power of this HVES instance is being limited due to an undefined cause.This parameter is for one of multiple packs in an HVESS.  If there is only one pack in the sy...";
CM_ BO_ 2364721918 "High Voltage Energy Storage Pack 19 Data 1";
CM_ SG_ 2364721918 Hvesp19AvailableDischargePower "HVESP19 Available Discharge Power: The rate at which this High Voltage Energy Storage Pack instance can currently provide energy for propulsion or other uses.This parameter is for one of multiple packs in an HVESS.  If there is only one pack in the s...";
CM_ SG_ 2364721918 Hvesp19AvailableChargePower "HVESP19 Available Charge Power: The rate at which this High Voltage Energy Storage Pack instance can currently receive energy from a regenerative or recharging system.This parameter is for one of multiple packs in an HVESS.  If there is only one pack...";
CM_ SG_ 2364721918 Hvesp19VoltageLevel "HVESP19 Voltage Level: The voltage level of this High Voltage Energy Storage Pack instance. This parameter should be synchronized with SPN 16431 (HVESP19 Current) such that a realized power value can be calculated. If the HVES component physically co...";
CM_ SG_ 2364721918 Hvesp19Current "HVESP19 Current: The current in or out of this High Voltage Energy Storage Pack instance. This parameter should be synchronized with SPN 16430 (HVESP19 Voltage Level) such that a realized power value can be calculated. This parameter is defined from ...";
CM_ BO_ 2364722174 "High Voltage Energy Storage Pack 19 Data 2";
CM_ SG_ 2364722174 Hvesp19FastUpdateStateOfCharge "HVESP19 Fast Update State of Charge: Indicates this High Voltage Energy Storage Pack instance state of charge. 0% means no charge remaining, 100% means the system is fully charged in terms of physical limits of this energy storage pack instance. Acce...";
CM_ SG_ 2364722174 Hvesp19HighestCellVoltage "HVESP19 Highest Cell Voltage: The highest voltage level reported by any cell in this High Voltage Energy Storage Pack instance. If a single voltage sensor covers more than one cell, the value in this parameter is for the smallest group of cells measu...";
CM_ SG_ 2364722174 Hvesp19LowestCellVoltage "HVESP19 Lowest Cell Voltage: The lowest voltage level reported by any cell in this High Voltage Energy Storage Pack instance. If a single voltage sensor covers more than one cell, the value in this parameter is for the smallest group of cells measure...";
CM_ SG_ 2364722174 Hvsp19CllVltgDffrntlStts "HVESP19 Cell Voltage Differential Status: Indicates whether or not the differential between the highest and lowest cell voltages are within acceptable limits, according to this High Voltage Energy Storage Pack instance. The actual voltage differentia...";
CM_ BO_ 2364722430 "High Voltage Energy Storage Pack 19 Data 3";
CM_ SG_ 2364722430 Hvesp19HighestCellTemperature "HVESP19 Highest Cell Temperature: The highest temperature level reported by any cell in this High Voltage Energy Storage Pack instance. If a single temperature sensor covers more than one cell, the value in this parameter is for the smallest group of...";
CM_ SG_ 2364722430 Hvesp19LowestCellTemperature "HVESP19 Lowest Cell Temperature: The lowest temperature level reported by any cell in this High Voltage Energy Storage Pack instance. If a single temperature sensor covers more than one cell, the value in this parameter is for the smallest group of c...";
CM_ SG_ 2364722430 Hvesp19AverageCellTemperature "HVESP19 Average Cell Temperature: The average temperature level of all cells in this High Voltage Energy Storage Pack instance.This parameter is for one of multiple packs in an HVESS.  If there is only one pack in the system, the HVESS parameters sho...";
CM_ SG_ 2364722430 Hvsp19CllTmprtrDffrntlStts "HVESP19 Cell Temperature Differential Status: Indicates whether or not the differential between the highest and lowest cell temperatures are within acceptable limits per this High Voltage Energy Storage Pack instance. The actual temperature different...";
CM_ BO_ 2364722686 "High Voltage Energy Storage Pack 19 Data 4";
CM_ SG_ 2364722686 Hvesp19DischargeCapacity "HVESP19 Discharge Capacity: The amount of stored electrical charge in this High Voltage Energy Storage Pack instance that is available for use by the hybrid or EV system, i.e. 'how full is the tank'. See SPN 16470 (HVESP19 Discharge Energy Capacity) ...";
CM_ SG_ 2364722686 Hvesp19ChargeCapacity "HVESP19 Charge Capacity: The amount of unused electrical charge storage in this High Voltage Energy Storage Pack instance that is available to be filled by charging, i.e. 'how much empty space is remaining in the tank'. See SPN 16471 (HVESP19 Charge ...";
CM_ SG_ 2364722686 Hvesp19CellBalancingCount "HVESP19 Cell Balancing Count: The number of cells that are currently being balanced in this High Voltage Energy Storage Pack instance.This parameter is for one of multiple packs in an HVESS.  If there is only one pack in the system, the HVESS paramet...";
CM_ BO_ 2364722942 "High Voltage Energy Storage Pack 19 Data 5";
CM_ SG_ 2364722942 Hvesp19LowestCellStateOfCharge "HVESP19 Lowest Cell State of Charge: Indicates the state of charge of the lowest-charged cell in this High Voltage Energy Storage Pack instance. 0% means no charge remaining, 100% means the cell is fully charged. If a single state of charge value cov...";
CM_ SG_ 2364722942 Hvesp19HighestCellStateOfCharge "HVESP19 Highest Cell State of Charge: Indicates the state of charge of the highest-charged cell in this High Voltage Energy Storage Pack instance. 0% means no charge remaining, 100% means the cell is fully charged. If a single state of charge value c...";
CM_ SG_ 2364722942 Hvsp19MxmmInstntnsDshrgCrrntLmt "HVESP19 Maximum Instantaneous Discharge Current Limit: The maximum instantaneous current flow limit out of this High Voltage Energy Storage Pack instance. This parameter is defined from the high voltage energy storage pack's point of view and should ...";
CM_ SG_ 2364722942 Hvsp19MxmmInstntnsChrgCrrntLmt "HVESP19 Maximum Instantaneous Charge Current Limit: The maximum instantaneous current flow limit into this High Voltage Energy Storage Pack instance. This parameter is defined from the high voltage energy storage pack's point of view and should refle...";
CM_ BO_ 2364723198 "High Voltage Energy Storage Pack 19 Data 6";
CM_ SG_ 2364723198 Hvesp19BusVoltage "HVESP19 Bus Voltage: The voltage level of the high voltage bus, as measured by this High Voltage Energy Storage Pack instance on the bus side (not the battery side) of its contactors.This parameter is for one of multiple packs in an HVESS.  If there ...";
CM_ SG_ 2364723198 Hvesp19IgnitionVoltage "HVESP19 Ignition Voltage: The voltage level at the ignition input of this High Voltage Energy Storage Pack controller.This parameter is for one of multiple packs in an HVESS.  If there is only one pack in the system, the HVESS parameters should be us...";
CM_ SG_ 2364723198 Hvesp19IntakeCoolantTemperature "HVESP19 Intake Coolant Temperature: The temperature of liquid coolant as it enters this High Voltage Energy Storage Pack instance.This parameter is for one of multiple packs in an HVESS.  If there is only one pack in the system, the HVESS parameters ...";
CM_ SG_ 2364723198 Hvesp19OutletCoolantTemperature "HVESP19 Outlet Coolant Temperature: The temperature of liquid coolant as it exits this High Voltage Energy Storage Pack instance.This parameter is for one of multiple packs in an HVESS.  If there is only one pack in the system, the HVESS parameters s...";
CM_ SG_ 2364723198 Hvesp19ElectronicsTemperature "HVESP19 Electronics Temperature: The temperature of the electronics or control modules in this High Voltage Energy Storage Pack instance.  If there are multiple temperature sensors then this parameter would be set to the maximum sensor reading.This p...";
CM_ SG_ 2364723198 Hvesp19Temperature "HVESP19 Temperature: The temperature of this High Voltage Energy Storage Pack instance. The value may be determined from a unique sensor specifically for this purpose, or by aggregating various temperature sensor readings within the pack.This paramet...";
CM_ BO_ 2364723454 "High Voltage Energy Storage Pack 19 Status 1";
CM_ SG_ 2364723454 Hvsp19HghVltgBsPstvCnttrStt "HVESP19 High-Voltage Bus (Positive) Contactor State: Position of this High Voltage Energy Storage Pack instance positive side bus contactor.  When this contactor is closed, the positive side of this HVES instance is connected to the positive side of ...";
CM_ SG_ 2364723454 Hvsp19HghVltgBsNgtvCnttrStt "HVESP19 High-Voltage Bus (Negative) Contactor State: Position of this High Voltage Energy Storage Pack instance negative side bus contactor. When this contactor is closed, the negative side of this HVES instance is connected to the negative side of t...";
CM_ SG_ 2364723454 Hvsp19HghVltgBsDsnntFrwrnng "HVESP19 High-Voltage Bus Disconnect Forewarning: Indicates that this High Voltage Energy Storage Pack instance is about to disconnect from the high voltage bus due to unacceptable conditions.This parameter is for one of multiple packs in an HVESS. If...";
CM_ SG_ 2364723454 Hvsp19HghVltgBsPrChrgRlStt "HVESP19 High-Voltage Bus Pre-Charge Relay State: Position of the high-voltage bus contactor pre-charge relay.  When this relay is closed, this High Voltage Energy Storage Pack instance is bringing the high-voltage bus up to its operating level.This p...";
CM_ SG_ 2364723454 Hvsp19CntrOfPkCnttrStt "HVESP19 Center of Pack Contactor State: Position of the center high-voltage contactor. When this contactor is closed, the positive half of this High Voltage Energy Storage Pack instance is connected to the negative half. If a system controls the posi...";
CM_ SG_ 2364723454 Hvsp19HghVltgBsAtvIsltnTstStts "HVESP19 High-Voltage Bus Active Isolation Test Status: Status of the high-voltage bus electrical active isolation test as performed by this High Voltage Energy Storage Pack instance.This parameter is for one of multiple packs in an HVESS. If there is...";
CM_ SG_ 2364723454 Hvsp19HghVltgBsPssvIsltnTstStts "HVESP19 High-Voltage Bus Passive Isolation Test Status: Status of the high-voltage bus electrical passive isolation test as performed by this High Voltage Energy Storage Pack instance.This parameter is for one of multiple packs in an HVESS. If there ...";
CM_ SG_ 2364723454 Hvesp19HvilStatus "HVESP19 HVIL Status: Status of the High Voltage Interlock Loop from the viewpoint of this High Voltage Energy Storage Pack instance.This parameter is for one of multiple packs in an HVESS. If there is only one pack in the system, the HVESS parameters...";
CM_ SG_ 2364723454 Hvesp19InertiaSwitchStatus "HVESP19 Inertia Switch Status: Switch indicating that an impact has been sensed by this High Voltage Energy Storage Pack instance. The impact indication may require action by another controller, or by this HVES instance itself.  For example, a contro...";
CM_ SG_ 2364723454 Hvesp19StateOfChargeStatus "HVESP19 State of Charge Status: Status of this High Voltage Energy Storage Pack instance State of Charge (SOC).  Note:  A given HVES controller may not support all of the states.This parameter is for one of multiple packs in an HVESS.  If there is on...";
CM_ SG_ 2364723454 Hvesp19CellBalanceStatus "HVESP19 Cell Balance Status: Indicates whether or not the cells in this High Voltage Energy Storage Pack instance are balanced.This parameter is for one of multiple packs in an HVESS.  If there is only one pack in the system, the HVESS parameters sho...";
CM_ SG_ 2364723454 Hvesp19CellBalancingActive "HVESP19 Cell Balancing Active: Indicates whether or not the cells in this High Voltage Energy Storage Pack instance are currently being balanced.This parameter is for one of multiple packs in an HVESS.  If there is only one pack in the system, the HV...";
CM_ SG_ 2364723454 Hvesp19InternalChargerStatus "HVESP19 Internal Charger Status: Indicates that the charger in this HVES instance is on.  External chargers may use the External Energy Source Connection Status (SPN 7898) and related SPs.This parameter is for one of multiple packs in an HVESS. If th...";
CM_ SG_ 2364723454 Hvsp19HghVltgBsCnntnStts "HVESP19 High-Voltage Bus Connection Status: This parameter provides high level feedback on this High Voltage Energy Storage Pack instance high voltage bus connection. For specific contactor information, see SPN 16453 (HVESP19 High-Voltage Bus (Positi...";
CM_ SG_ 2364723454 Hvesp19OperationalStatus "HVESP19 Operational Status: Provides feedback on where this High Voltage Energy Storage Pack instance is in its operating spectrum, and includes feedback in response to the Operation Consent [i.e. SPN 16411 (HVESP19 Operation Consent)] and Power Down...";
CM_ SG_ 2364723454 Hvesp19Status1Counter "HVESP19 Status 1 Counter: The message counter is used to detect situations where the transmitting ECU malfunction repeats the same frame all the time. The receiver of the information may use the counter parameter to detect this situation. The transmi...";
CM_ SG_ 2364723454 Hvesp19Status1Crc "HVESP19 Status 1 CRC: The CRC is defined as follows: - Length: 8 bits- Polynomial: x^8+x^5+x^3+x^2+x+1- Initial Value: FFh- Input Data Reflection: Not reflected- Result Data Reflection: Not reflected- XOR value: FFh SAE makes no claim of the function...";
CM_ BO_ 2364723710 "High Voltage Energy Storage Pack 19 Data 7";
CM_ SG_ 2364723710 Hvesp19DischargeEnergyCapacity "HVESP19 Discharge Energy Capacity: The amount of stored electrical energy in this High Voltage Energy Storage Pack instance that is available for use by the hybrid or EV system, i.e. 'how full is the tank'. See SPN 16440 (HVESP19 Discharge Capacity) ...";
CM_ SG_ 2364723710 Hvesp19ChargeEnergyCapacity "HVESP19 Charge Energy Capacity: The amount of unused electrical energy storage available to be filled by charging this High Voltage Energy Storage Pack instance, i.e. 'how much empty space is remaining in the tank'. See SPN 16441 (HVESP19 Charge Capa...";
CM_ SG_ 2364723710 Hvsp19MxmmChrgVltgLmt "HVESP19 Maximum Charge Voltage Limit: The maximum voltage level not to be exceeded while charging this High Voltage Energy Storage Pack instance. If this parameter is not supported, the maximum charge voltage should be limited to SPN 16539 (HVESP19 R...";
CM_ BO_ 2364723966 "High Voltage Energy Storage Pack 19 Module Status 1";
CM_ SG_ 2364723966 Hvesp19Module1OperationalStatus "HVESP19 Module 1 Operational Status: Operational Status of Module 1 in this High Voltage Energy Storage Pack Instance.  Not Operational is used when the module is initializing or not able to function (e.g. internal module level monitors have failed)....";
CM_ SG_ 2364723966 Hvesp19Module2OperationalStatus "HVESP19 Module 2 Operational Status: Operational Status of Module 2 in this High Voltage Energy Storage Pack Instance.  Not Operational is used when the module is initializing or not able to function (e.g. internal module level monitors have failed)....";
CM_ SG_ 2364723966 Hvesp19Module3OperationalStatus "HVESP19 Module 3 Operational Status: Operational Status of Module 3 in this High Voltage Energy Storage Pack Instance.  Not Operational is used when the module is initializing or not able to function (e.g. internal module level monitors have failed)....";
CM_ SG_ 2364723966 Hvesp19Module4OperationalStatus "HVESP19 Module 4 Operational Status: Operational Status of Module 4 in this High Voltage Energy Storage Pack Instance.  Not Operational is used when the module is initializing or not able to function (e.g. internal module level monitors have failed)....";
CM_ SG_ 2364723966 Hvesp19Module5OperationalStatus "HVESP19 Module 5 Operational Status: Operational Status of Module 5 in this High Voltage Energy Storage Pack Instance.  Not Operational is used when the module is initializing or not able to function (e.g. internal module level monitors have failed)....";
CM_ SG_ 2364723966 Hvesp19Module6OperationalStatus "HVESP19 Module 6 Operational Status: Operational Status of Module 6 in this High Voltage Energy Storage Pack Instance.  Not Operational is used when the module is initializing or not able to function (e.g. internal module level monitors have failed)....";
CM_ SG_ 2364723966 Hvesp19Module7OperationalStatus "HVESP19 Module 7 Operational Status: Operational Status of Module 7 in this High Voltage Energy Storage Pack Instance.  Not Operational is used when the module is initializing or not able to function (e.g. internal module level monitors have failed)....";
CM_ SG_ 2364723966 Hvesp19Module8OperationalStatus "HVESP19 Module 8 Operational Status: Operational Status of Module 8 in this High Voltage Energy Storage Pack Instance.  Not Operational is used when the module is initializing or not able to function (e.g. internal module level monitors have failed)....";
CM_ SG_ 2364723966 Hvesp19Module9OperationalStatus "HVESP19 Module 9 Operational Status: Operational Status of Module 9 in this High Voltage Energy Storage Pack Instance.  Not Operational is used when the module is initializing or not able to function (e.g. internal module level monitors have failed)....";
CM_ SG_ 2364723966 Hvsp19Mdl10OprtnlStts "HVESP19 Module 10 Operational Status: Operational Status of Module 10 in this High Voltage Energy Storage Pack Instance.  Not Operational is used when the module is initializing or not able to function (e.g. internal module level monitors have failed...";
CM_ SG_ 2364723966 Hvsp19Mdl11OprtnlStts "HVESP19 Module 11 Operational Status: Operational Status of Module 11 in this High Voltage Energy Storage Pack Instance.  Not Operational is used when the module is initializing or not able to function (e.g. internal module level monitors have failed...";
CM_ SG_ 2364723966 Hvsp19Mdl12OprtnlStts "HVESP19 Module 12 Operational Status: Operational Status of Module 12 in this High Voltage Energy Storage Pack Instance.  Not Operational is used when the module is initializing or not able to function (e.g. internal module level monitors have failed...";
CM_ SG_ 2364723966 Hvsp19Mdl13OprtnlStts "HVESP19 Module 13 Operational Status: Operational Status of Module 13 in this High Voltage Energy Storage Pack Instance.  Not Operational is used when the module is initializing or not able to function (e.g. internal module level monitors have failed...";
CM_ SG_ 2364723966 Hvsp19Mdl14OprtnlStts "HVESP19 Module 14 Operational Status: Operational Status of Module 14 in this High Voltage Energy Storage Pack Instance.  Not Operational is used when the module is initializing or not able to function (e.g. internal module level monitors have failed...";
CM_ SG_ 2364723966 Hvsp19Mdl15OprtnlStts "HVESP19 Module 15 Operational Status: Operational Status of Module 15 in this High Voltage Energy Storage Pack Instance.  Not Operational is used when the module is initializing or not able to function (e.g. internal module level monitors have failed...";
CM_ SG_ 2364723966 Hvsp19Mdl16OprtnlStts "HVESP19 Module 16 Operational Status: Operational Status of Module 16 in this High Voltage Energy Storage Pack Instance.  Not Operational is used when the module is initializing or not able to function (e.g. internal module level monitors have failed...";
CM_ SG_ 2364723966 Hvsp19Mdl17OprtnlStts "HVESP19 Module 17 Operational Status: Operational Status of Module 17 in this High Voltage Energy Storage Pack Instance.  Not Operational is used when the module is initializing or not able to function (e.g. internal module level monitors have failed...";
CM_ SG_ 2364723966 Hvsp19Mdl18OprtnlStts "HVESP19 Module 18 Operational Status: Operational Status of Module 18 in this High Voltage Energy Storage Pack Instance.  Not Operational is used when the module is initializing or not able to function (e.g. internal module level monitors have failed...";
CM_ SG_ 2364723966 Hvsp19Mdl19OprtnlStts "HVESP19 Module 19 Operational Status: Operational Status of Module 19 in this High Voltage Energy Storage Pack Instance.  Not Operational is used when the module is initializing or not able to function (e.g. internal module level monitors have failed...";
CM_ SG_ 2364723966 Hvsp19Mdl20OprtnlStts "HVESP19 Module 20 Operational Status: Operational Status of Module 20 in this High Voltage Energy Storage Pack Instance.  Not Operational is used when the module is initializing or not able to function (e.g. internal module level monitors have failed...";
CM_ SG_ 2364723966 Hvsp19Mdl21OprtnlStts "HVESP19 Module 21 Operational Status: Operational Status of Module 21 in this High Voltage Energy Storage Pack Instance.  Not Operational is used when the module is initializing or not able to function (e.g. internal module level monitors have failed...";
CM_ SG_ 2364723966 Hvsp19Mdl22OprtnlStts "HVESP19 Module 22 Operational Status: Operational Status of Module 22 in this High Voltage Energy Storage Pack Instance.  Not Operational is used when the module is initializing or not able to function (e.g. internal module level monitors have failed...";
CM_ SG_ 2364723966 Hvsp19Mdl23OprtnlStts "HVESP19 Module 23 Operational Status: Operational Status of Module 23 in this High Voltage Energy Storage Pack Instance.  Not Operational is used when the module is initializing or not able to function (e.g. internal module level monitors have failed...";
CM_ SG_ 2364723966 Hvsp19Mdl24OprtnlStts "HVESP19 Module 24 Operational Status: Operational Status of Module 24 in this High Voltage Energy Storage Pack Instance.  Not Operational is used when the module is initializing or not able to function (e.g. internal module level monitors have failed...";
CM_ SG_ 2364723966 Hvsp19Mdl25OprtnlStts "HVESP19 Module 25 Operational Status: Operational Status of Module 25 in this High Voltage Energy Storage Pack Instance.  Not Operational is used when the module is initializing or not able to function (e.g. internal module level monitors have failed...";
CM_ SG_ 2364723966 Hvsp19Mdl26OprtnlStts "HVESP19 Module 26 Operational Status: Operational Status of Module 26 in this High Voltage Energy Storage Pack Instance.  Not Operational is used when the module is initializing or not able to function (e.g. internal module level monitors have failed...";
CM_ SG_ 2364723966 Hvsp19Mdl27OprtnlStts "HVESP19 Module 27 Operational Status: Operational Status of Module 27 in this High Voltage Energy Storage Pack Instance.  Not Operational is used when the module is initializing or not able to function (e.g. internal module level monitors have failed...";
CM_ SG_ 2364723966 Hvsp19Mdl28OprtnlStts "HVESP19 Module 28 Operational Status: Operational Status of Module 28 in this High Voltage Energy Storage Pack Instance.  Not Operational is used when the module is initializing or not able to function (e.g. internal module level monitors have failed...";
CM_ SG_ 2364723966 Hvsp19Mdl29OprtnlStts "HVESP19 Module 29 Operational Status: Operational Status of Module 29 in this High Voltage Energy Storage Pack Instance.  Not Operational is used when the module is initializing or not able to function (e.g. internal module level monitors have failed...";
CM_ SG_ 2364723966 Hvsp19Mdl30OprtnlStts "HVESP19 Module 30 Operational Status: Operational Status of Module 30 in this High Voltage Energy Storage Pack Instance.  Not Operational is used when the module is initializing or not able to function (e.g. internal module level monitors have failed...";
CM_ SG_ 2364723966 Hvsp19Mdl31OprtnlStts "HVESP19 Module 31 Operational Status: Operational Status of Module 31 in this High Voltage Energy Storage Pack Instance.  Not Operational is used when the module is initializing or not able to function (e.g. internal module level monitors have failed...";
CM_ SG_ 2364723966 Hvsp19Mdl32OprtnlStts "HVESP19 Module 32 Operational Status: Operational Status of Module 32 in this High Voltage Energy Storage Pack Instance.  Not Operational is used when the module is initializing or not able to function (e.g. internal module level monitors have failed...";
CM_ BO_ 2364724222 "High Voltage Energy Storage Pack 19 Thermal Management System Status 1";
CM_ SG_ 2364724222 Hvsp19ThrmlMngmntSstmSlInptPwr "HVESP19 Thermal Management System SLI Input Power: This is the low-voltage power consumed by this HVES Thermal Management System (TMS).This parameter is for one of multiple packs in an HVESS.  If there is only one pack in the system, the HVESS parame...";
CM_ SG_ 2364724222 Hvsp19TMtSstHVtIptPw "HVESP19 Thermal Management System High-Voltage Input Power: This is the high-voltage power consumed by this HVES Thermal Management System (TMS).This parameter is for one of multiple packs in an HVESS.  If there is only one pack in the system, the HV...";
CM_ SG_ 2364724222 Hvsp19ThrmlMngmntSstmCmprssrSpd "HVESP19 Thermal Management System Compressor Speed: When this High Voltage Energy Storage Pack Thermal Management System is equipped with an active cooling system (e.g. air conditioner), this is the Compressor Speed.This parameter is for one of multi...";
CM_ SG_ 2364724222 Hvsp19ThrmlMngmntSstmRltvHmdt "HVESP19 Thermal Management System Relative Humidty: When this High Voltage Energy Storage Pack Thermal Management System is equipped with a relative humidity sensor, this is the  measured Relative Humidity.This parameter is for one of multiple packs ...";
CM_ SG_ 2364724222 Hvsp19ThrmlMngmntSstmHtrStts "HVESP19 Thermal Management System Heater Status: The state of this High Voltage Energy Storage Pack heaterThis parameter is for one of multiple packs in an HVESS.  If there is only one pack in the system, the HVESS parameters should be used. If there...";
CM_ SG_ 2364724222 Hvsp19ThrmlMngmntSstmHvlStts "HVESP19 Thermal Management System HVIL Status: In multiple HVES configurations, this is the status of the High Voltage Interlock Loop from the viewpoint of this Thermal Management System.00b = HVIL Closed01b = HVIL Open10b = Error11b = Not AvailableT...";
CM_ SG_ 2364724222 Hvsp19ThrmlMngmntSstmMd "HVESP19 Thermal Management System Mode: Indicates the operating mode of the Thermal Management System.  The heat transfer medium may be (e.g. liquid or air).  The cooling system may be fans, liquid coolant, or a combination of mediums.  The system ma...";
CM_ SG_ 2364724222 Hvsp19ThrmlMngmntSstmClntLvl "HVESP19 Thermal Management System Coolant Level: Indicates the coolant level in this HVES Thermal Management System (TMS).This parameter is for one of multiple packs in an HVESS.  If there is only one pack in the system, the HVESS parameters should b...";
CM_ BO_ 2364724478 "High Voltage Energy Storage Pack 19 Data 8";
CM_ SG_ 2364724478 Hvsp19HghstCllVltgMdlNmr "HVESP19 Highest Cell Voltage Module Number: Identifies the location of the module containing SPN 16433 (HVESP19 Highest Cell Voltage).This parameter is for one of multiple packs in an HVESS. If there is only one pack in the system, the HVESS paramete...";
CM_ SG_ 2364724478 Hvsp19HghstCllVltgCllNmr "HVESP19 Highest Cell Voltage Cell Number: Identifies the location of SPN 16433 (HVESP19 Highest Cell Voltage) within SPN 16513 (HVESP19 Highest Cell Voltage Module Number).This parameter is for one of multiple packs in an HVESS. If there is only one ...";
CM_ SG_ 2364724478 Hvsp19LwstCllVltgMdlNmr "HVESP19 Lowest Cell Voltage Module Number: Identifies the location of the module containing SPN 16434 (HVESP19 Lowest Cell Voltage).This parameter is for one of multiple packs in an HVESS. If there is only one pack in the system, the HVESS parameters...";
CM_ SG_ 2364724478 Hvsp19LwstCllVltgCllNmr "HVESP19 Lowest Cell Voltage Cell Number: Identifies the location of SPN 16434 (HVESP19 Lowest Cell Voltage) within SPN 16515 (HVESP19 Lowest Cell Voltage Module Number).This parameter is for one of multiple packs in an HVESS. If there is only one pac...";
CM_ SG_ 2364724478 Hvesp19AverageCellVoltage "HVESP19 Average Cell Voltage: The average cell voltage in this High Voltage Energy Storage Pack instance.This parameter is for one of multiple packs in an HVESS.  If there is only one pack in the system, the HVESS parameters should be used. If there ...";
CM_ BO_ 2364724734 "High Voltage Energy Storage Pack 19 Data 9";
CM_ SG_ 2364724734 Hvsp19HghstCllTmprtrMdlNmr "HVESP19 Highest Cell Temperature Module Number: Identifies the location of the module containing SPN 16436 (HVESP19 Highest Cell Temperature).This parameter is for one of multiple packs in an HVESS. If there is only one pack in the system, the HVESS ...";
CM_ SG_ 2364724734 Hvsp19HghstCllTmprtrCllNmr "HVESP19 Highest Cell Temperature Cell Number: Identifies the location of SPN 16436 (HVESP19 Highest Cell Temperature) within SPN 16518 (HVESP19 Highest Cell Temperature Module Number).This parameter is for one of multiple packs in an HVESS. If there ...";
CM_ SG_ 2364724734 Hvsp19LwstCllTmprtrMdlNmr "HVESP19 Lowest Cell Temperature Module Number: Identifies the location of the module containing SPN 16437 (HVESP19 Lowest Cell Temperature).This parameter is for one of multiple packs in an HVESS. If there is only one pack in the system, the HVESS pa...";
CM_ SG_ 2364724734 Hvsp19LwstCllTmprtrCllNmr "HVESP19 Lowest Cell Temperature Cell Number: Identifies the location of SPN 16437 (HVESP19 Lowest Cell Temperature) within SPN 16520 (HVESP19 Lowest Cell Temperature Module Number).This parameter is for one of multiple packs in an HVESS. If there is ...";
CM_ SG_ 2364724734 Hvess19ThermalEventDetected "HVESS19 Thermal Event Detected: A sensor has detected the presence of a thermal event at or near High Voltage Energy Storage Pack instance.00b = No Thermal Event Detected01b = Thermal Event Detected10b = Error11b = Not availableThis parameter is for ...";
CM_ SG_ 2364724734 Hvsp19Dt9EmdddIntgrtSpprt "HVESP19 Data 9 Embedded Integrity Support: Indicates SPN 23030 (HVESP19 Data 9 CRC) and SPN 23029 (HVESP19 Data 9 Counter) are supported by the sender.00b = Embedded CRC and Counter are supported by the sender01b = Protection is provided using an ext...";
CM_ SG_ 2364724734 Hvesp19Data9Counter "HVESP19 Data 9 Counter: The message counter is used to detect situations where the transmitting ECU malfunction repeats the same frame all the time. The receiver of the information may use the counter parameter to detect this situation. The transmitt...";
CM_ SG_ 2364724734 Hvesp19Data9Crc "HVESP19 Data 9 CRC: The CRC is defined as follows: - Length: 8 bits- Polynomial: x^8+x^5+x^3+x^2+x+1- Initial Value: FFh- Input Data Reflection: Not reflected- Result Data Reflection: Not reflected- XOR value: FFh SAE makes no claim of the functional...";
CM_ BO_ 2364724990 "High Voltage Energy Storage Pack 19 Data 10";
CM_ SG_ 2364724990 Hvsp19HghstCllSttOfChrgMdlNmr "HVESP19 Highest Cell State of Charge Module Number: Identifies the location of the module containing SPN 16446 (HVESP19 Highest Cell State of Charge).This parameter is for one of multiple packs in an HVESS. If there is only one pack in the system, th...";
CM_ SG_ 2364724990 Hvsp19HghstCllSttOfChrgCllNmr "HVESP19 Highest Cell State of Charge Cell Number: Identifies the location of SPN 16446 (HVESP19 Highest Cell State of Charge) within SPN 16522 (HVESP19 Highest Cell State of Charge Module Number).This parameter is for one of multiple packs in an HVES...";
CM_ SG_ 2364724990 Hvsp19LwstCllSttOfChrgMdlNmr "HVESP19 Lowest Cell State of Charge Module Number: Identifies the location of the module containing SPN 16445 (HVESP19 Lowest Cell State of Charge).This parameter is for one of multiple packs in an HVESS. If there is only one pack in the system, the ...";
CM_ SG_ 2364724990 Hvsp19LwstCllSttOfChrgCllNmr "HVESP19 Lowest Cell State of Charge Cell Number: Identifies the location of SPN 16445 (HVESP19 Lowest Cell State of Charge) within SPN 16524 (HVESP19 Lowest Cell State of Charge Module Number).This parameter is for one of multiple packs in an HVESS. ...";
CM_ SG_ 2364724990 Hvsp19HghVltgBsAtvIsltnTstRslts "HVESP19 High-Voltage Bus Active Isolation Test Results: The isolation resistance expressed in Ohms per Volt that resulted from the High-Voltage Bus Active Isolation Test.See SPN 16458 (HVESP19 High-Voltage Bus Active Isolation Test Status) for test s...";
CM_ SG_ 2364724990 Hvsp19HVtBsPssvIstTstRsts "HVESP19 High-Voltage Bus Passive Isolation Test Results: The isolation resistance expressed in Ohms per Volt that resulted from the High-Voltage Bus Passive Isolation Test.See SPN 16459 (HVESP19 High-Voltage Bus Passive Isolation Test Status) for tes...";
CM_ BO_ 2364725246 "High Voltage Energy Storage Pack 19 Data 11";
CM_ SG_ 2364725246 Hvsp19BsVltgNgtvTChsssGrndVltg "HVESP19 Bus Voltage Negative to Chassis Ground Voltage: Voltage difference between the most negative terminal of the HVES battery and chassis measured on the hybrid or EV system bus side (not the battery side) of any HVES contained output contactor. ...";
CM_ SG_ 2364725246 Hvsp19VltgLvlNgtvTChsssGrndVltg "HVESP19 Voltage Level Negative to Chassis Ground Voltage: Voltage difference between the most negative terminal of the HVES battery and chassis measured at the battery side of any HVES contained output contactor.  This voltage may be used for system ...";
CM_ SG_ 2364725246 Hvesp19ActualChargeRate "HVESP19 Actual Charge Rate: This signal represents the actual present charge rate of this High Voltage Energy Storage Pack instance.This parameter is for one of multiple packs in an HVESS. If there is only one pack in the system, the HVESS parameters...";
CM_ BO_ 2364725502 "High Voltage Energy Storage Pack 20 Status 2";
CM_ SG_ 2364725502 Hvsp20DshrgPwrLmtDTSttOfChrg "HVESP20 Discharge Power Limit Due to State of Charge: Indicates whether or not discharge power of this HVES instance is being limited due to state of charge.This parameter is for one of multiple packs in an HVESS.  If there is only one pack in the sy...";
CM_ SG_ 2364725502 Hvsp20DshrgPwrLmtDTBttrTmprtr "HVESP20 Discharge Power Limit Due to Battery Temperature: Indicates whether or not discharge power of this HVES instance is being limited due to battery temperature.This parameter is for one of multiple packs in an HVESS.  If there is only one pack i...";
CM_ SG_ 2364725502 Hvsp20DsPwLtDTBttDstCdt "HVESP20 Discharge Power Limit Due to Battery Diagnostic Condition: Indicates whether or not discharge power of this HVES instance is being limited due to a battery diagnostic condition.This parameter is for one of multiple packs in an HVESS.  If ther...";
CM_ SG_ 2364725502 Hvsp20DsPwLtDTBttOCVt "HVESP20 Discharge Power Limit Due to Battery or Cell Voltage: Indicates whether or not discharge power of this HVES instance is being limited due to a battery or cell voltage level.This parameter is for one of multiple packs in an HVESS.  If there is...";
CM_ SG_ 2364725502 Hvsp20DshrgPwrLmtDTBttrCrrnt "HVESP20 Discharge Power Limit Due to Battery Current: Indicates whether or not discharge power of this HVES instance is being limited due to battery current.This parameter is for one of multiple packs in an HVESS.  If there is only one pack in the sy...";
CM_ SG_ 2364725502 Hvsp20DshrgPwrLmtDTAnUndfndCs "HVESP20 Discharge Power Limit Due to an Undefined Cause: Indicates whether or not discharge power of this HVES instance is being limited due to an undefined cause.This parameter is for one of multiple packs in an HVESS.  If there is only one pack in ...";
CM_ SG_ 2364725502 Hvsp20ChrgPwrLmtDTSttOfChrg "HVESP20 Charge Power Limit Due to State of Charge: Indicates whether or not charge power of this HVES instance is being limited due to state of charge.This parameter is for one of multiple packs in an HVESS.  If there is only one pack in the system, ...";
CM_ SG_ 2364725502 Hvsp20ChrgPwrLmtDTBttrTmprtr "HVESP20 Charge Power Limit Due to Battery Temperature: Indicates whether or not charge power of this HVES instance is being limited due to battery temperature.This parameter is for one of multiple packs in an HVESS.  If there is only one pack in the ...";
CM_ SG_ 2364725502 Hvsp20CPwLtDTBttDstCdt "HVESP20 Charge Power Limit Due to Battery Diagnostic Condition: Indicates whether or not charge power of this HVES instance is being limited due to a battery diagnostic condition.This parameter is for one of multiple packs in an HVESS.  If there is o...";
CM_ SG_ 2364725502 Hvsp20ChrgPwrLmtDTBttrOrCllVltg "HVESP20 Charge Power Limit Due to Battery or Cell Voltage: Indicates whether or not charge power of this HVES instance is being limited due to a battery or cell voltage level.This parameter is for one of multiple packs in an HVESS.  If there is only ...";
CM_ SG_ 2364725502 Hvsp20ChrgPwrLmtDTBttrCrrnt "HVESP20 Charge Power Limit Due to Battery Current: Indicates whether or not charge power of this HVES instance is being limited due to battery current.This parameter is for one of multiple packs in an HVESS.  If there is only one pack in the system, ...";
CM_ SG_ 2364725502 Hvsp20ChrgPwrLmtDTAnUndfndCs "HVESP20 Charge Power Limit Due to an Undefined Cause: Indicates whether or not charge power of this HVES instance is being limited due to an undefined cause.This parameter is for one of multiple packs in an HVESS.  If there is only one pack in the sy...";
CM_ BO_ 2364725758 "High Voltage Energy Storage Pack 20 Data 1";
CM_ SG_ 2364725758 Hvesp20AvailableDischargePower "HVESP20 Available Discharge Power: The rate at which this High Voltage Energy Storage Pack instance can currently provide energy for propulsion or other uses.This parameter is for one of multiple packs in an HVESS.  If there is only one pack in the s...";
CM_ SG_ 2364725758 Hvesp20AvailableChargePower "HVESP20 Available Charge Power: The rate at which this High Voltage Energy Storage Pack instance can currently receive energy from a regenerative or recharging system.This parameter is for one of multiple packs in an HVESS.  If there is only one pack...";
CM_ SG_ 2364725758 Hvesp20VoltageLevel "HVESP20 Voltage Level: The voltage level of this High Voltage Energy Storage Pack instance. This parameter should be synchronized with SPN 16573 (HVESP20 Current) such that a realized power value can be calculated. If the HVES component physically co...";
CM_ SG_ 2364725758 Hvesp20Current "HVESP20 Current: The current in or out of this High Voltage Energy Storage Pack instance. This parameter should be synchronized with SPN 16572 (HVESP20 Voltage Level) such that a realized power value can be calculated. This parameter is defined from ...";
CM_ BO_ 2364726014 "High Voltage Energy Storage Pack 20 Data 2";
CM_ SG_ 2364726014 Hvesp20FastUpdateStateOfCharge "HVESP20 Fast Update State of Charge: Indicates this High Voltage Energy Storage Pack instance state of charge. 0% means no charge remaining, 100% means the system is fully charged in terms of physical limits of this energy storage pack instance. Acce...";
CM_ SG_ 2364726014 Hvesp20HighestCellVoltage "HVESP20 Highest Cell Voltage: The highest voltage level reported by any cell in this High Voltage Energy Storage Pack instance. If a single voltage sensor covers more than one cell, the value in this parameter is for the smallest group of cells measu...";
CM_ SG_ 2364726014 Hvesp20LowestCellVoltage "HVESP20 Lowest Cell Voltage: The lowest voltage level reported by any cell in this High Voltage Energy Storage Pack instance. If a single voltage sensor covers more than one cell, the value in this parameter is for the smallest group of cells measure...";
CM_ SG_ 2364726014 Hvsp20CllVltgDffrntlStts "HVESP20 Cell Voltage Differential Status: Indicates whether or not the differential between the highest and lowest cell voltages are within acceptable limits, according to this High Voltage Energy Storage Pack instance. The actual voltage differentia...";
CM_ BO_ 2364726270 "High Voltage Energy Storage Pack 20 Data 3";
CM_ SG_ 2364726270 Hvesp20HighestCellTemperature "HVESP20 Highest Cell Temperature: The highest temperature level reported by any cell in this High Voltage Energy Storage Pack instance. If a single temperature sensor covers more than one cell, the value in this parameter is for the smallest group of...";
CM_ SG_ 2364726270 Hvesp20LowestCellTemperature "HVESP20 Lowest Cell Temperature: The lowest temperature level reported by any cell in this High Voltage Energy Storage Pack instance. If a single temperature sensor covers more than one cell, the value in this parameter is for the smallest group of c...";
CM_ SG_ 2364726270 Hvesp20AverageCellTemperature "HVESP20 Average Cell Temperature: The average temperature level of all cells in this High Voltage Energy Storage Pack instance.This parameter is for one of multiple packs in an HVESS.  If there is only one pack in the system, the HVESS parameters sho...";
CM_ SG_ 2364726270 Hvsp20CllTmprtrDffrntlStts "HVESP20 Cell Temperature Differential Status: Indicates whether or not the differential between the highest and lowest cell temperatures are within acceptable limits per this High Voltage Energy Storage Pack instance. The actual temperature different...";
CM_ BO_ 2364726526 "High Voltage Energy Storage Pack 20 Data 4";
CM_ SG_ 2364726526 Hvesp20DischargeCapacity "HVESP20 Discharge Capacity: The amount of stored electrical charge in this High Voltage Energy Storage Pack instance that is available for use by the hybrid or EV system, i.e. 'how full is the tank'. See SPN 16612 (HVESP20 Discharge Energy Capacity) ...";
CM_ SG_ 2364726526 Hvesp20ChargeCapacity "HVESP20 Charge Capacity: The amount of unused electrical charge storage in this High Voltage Energy Storage Pack instance that is available to be filled by charging, i.e. 'how much empty space is remaining in the tank'. See SPN 16613 (HVESP20 Charge ...";
CM_ SG_ 2364726526 Hvesp20CellBalancingCount "HVESP20 Cell Balancing Count: The number of cells that are currently being balanced in this High Voltage Energy Storage Pack instance.This parameter is for one of multiple packs in an HVESS.  If there is only one pack in the system, the HVESS paramet...";
CM_ BO_ 2364726782 "High Voltage Energy Storage Pack 20 Data 5";
CM_ SG_ 2364726782 Hvesp20LowestCellStateOfCharge "HVESP20 Lowest Cell State of Charge: Indicates the state of charge of the lowest-charged cell in this High Voltage Energy Storage Pack instance. 0% means no charge remaining, 100% means the cell is fully charged. If a single state of charge value cov...";
CM_ SG_ 2364726782 Hvesp20HighestCellStateOfCharge "HVESP20 Highest Cell State of Charge: Indicates the state of charge of the highest-charged cell in this High Voltage Energy Storage Pack instance. 0% means no charge remaining, 100% means the cell is fully charged. If a single state of charge value c...";
CM_ SG_ 2364726782 Hvsp20MxmmInstntnsDshrgCrrntLmt "HVESP20 Maximum Instantaneous Discharge Current Limit: The maximum instantaneous current flow limit out of this High Voltage Energy Storage Pack instance. This parameter is defined from the high voltage energy storage pack's point of view and should ...";
CM_ SG_ 2364726782 Hvsp20MxmmInstntnsChrgCrrntLmt "HVESP20 Maximum Instantaneous Charge Current Limit: The maximum instantaneous current flow limit into this High Voltage Energy Storage Pack instance. This parameter is defined from the high voltage energy storage pack's point of view and should refle...";
CM_ BO_ 2364727038 "High Voltage Energy Storage Pack 20 Data 6";
CM_ SG_ 2364727038 Hvesp20BusVoltage "HVESP20 Bus Voltage: The voltage level of the high voltage bus, as measured by this High Voltage Energy Storage Pack instance on the bus side (not the battery side) of its contactors.This parameter is for one of multiple packs in an HVESS.  If there ...";
CM_ SG_ 2364727038 Hvesp20IgnitionVoltage "HVESP20 Ignition Voltage: The voltage level at the ignition input of this High Voltage Energy Storage Pack controller.This parameter is for one of multiple packs in an HVESS.  If there is only one pack in the system, the HVESS parameters should be us...";
CM_ SG_ 2364727038 Hvesp20IntakeCoolantTemperature "HVESP20 Intake Coolant Temperature: The temperature of liquid coolant as it enters this High Voltage Energy Storage Pack instance.This parameter is for one of multiple packs in an HVESS.  If there is only one pack in the system, the HVESS parameters ...";
CM_ SG_ 2364727038 Hvesp20OutletCoolantTemperature "HVESP20 Outlet Coolant Temperature: The temperature of liquid coolant as it exits this High Voltage Energy Storage Pack instance.This parameter is for one of multiple packs in an HVESS.  If there is only one pack in the system, the HVESS parameters s...";
CM_ SG_ 2364727038 Hvesp20ElectronicsTemperature "HVESP20 Electronics Temperature: The temperature of the electronics or control modules in this High Voltage Energy Storage Pack instance.  If there are multiple temperature sensors then this parameter would be set to the maximum sensor reading.This p...";
CM_ SG_ 2364727038 Hvesp20Temperature "HVESP20 Temperature: The temperature of this High Voltage Energy Storage Pack instance. The value may be determined from a unique sensor specifically for this purpose, or by aggregating various temperature sensor readings within the pack.This paramet...";
CM_ BO_ 2364727294 "High Voltage Energy Storage Pack 20 Status 1";
CM_ SG_ 2364727294 Hvsp20HghVltgBsPstvCnttrStt "HVESP20 High-Voltage Bus (Positive) Contactor State: Position of this High Voltage Energy Storage Pack instance positive side bus contactor.  When this contactor is closed, the positive side of this HVES instance is connected to the positive side of ...";
CM_ SG_ 2364727294 Hvsp20HghVltgBsNgtvCnttrStt "HVESP20 High-Voltage Bus (Negative) Contactor State: Position of this High Voltage Energy Storage Pack instance negative side bus contactor. When this contactor is closed, the negative side of this HVES instance is connected to the negative side of t...";
CM_ SG_ 2364727294 Hvsp20HghVltgBsDsnntFrwrnng "HVESP20 High-Voltage Bus Disconnect Forewarning: Indicates that this High Voltage Energy Storage Pack instance is about to disconnect from the high voltage bus due to unacceptable conditions.This parameter is for one of multiple packs in an HVESS. If...";
CM_ SG_ 2364727294 Hvsp20HghVltgBsPrChrgRlStt "HVESP20 High-Voltage Bus Pre-Charge Relay State: Position of the high-voltage bus contactor pre-charge relay.  When this relay is closed, this High Voltage Energy Storage Pack instance is bringing the high-voltage bus up to its operating level.This p...";
CM_ SG_ 2364727294 Hvsp20CntrOfPkCnttrStt "HVESP20 Center of Pack Contactor State: Position of the center high-voltage contactor. When this contactor is closed, the positive half of this High Voltage Energy Storage Pack instance is connected to the negative half. If a system controls the posi...";
CM_ SG_ 2364727294 Hvsp20HghVltgBsAtvIsltnTstStts "HVESP20 High-Voltage Bus Active Isolation Test Status: Status of the high-voltage bus electrical active isolation test as performed by this High Voltage Energy Storage Pack instance.This parameter is for one of multiple packs in an HVESS. If there is...";
CM_ SG_ 2364727294 Hvsp20HghVltgBsPssvIsltnTstStts "HVESP20 High-Voltage Bus Passive Isolation Test Status: Status of the high-voltage bus electrical passive isolation test as performed by this High Voltage Energy Storage Pack instance.This parameter is for one of multiple packs in an HVESS. If there ...";
CM_ SG_ 2364727294 Hvesp20HvilStatus "HVESP20 HVIL Status: Status of the High Voltage Interlock Loop from the viewpoint of this High Voltage Energy Storage Pack instance.This parameter is for one of multiple packs in an HVESS. If there is only one pack in the system, the HVESS parameters...";
CM_ SG_ 2364727294 Hvesp20InertiaSwitchStatus "HVESP20 Inertia Switch Status: Switch indicating that an impact has been sensed by this High Voltage Energy Storage Pack instance. The impact indication may require action by another controller, or by this HVES instance itself.  For example, a contro...";
CM_ SG_ 2364727294 Hvesp20StateOfChargeStatus "HVESP20 State of Charge Status: Status of this High Voltage Energy Storage Pack instance State of Charge (SOC).  Note:  A given HVES controller may not support all of the states.This parameter is for one of multiple packs in an HVESS.  If there is on...";
CM_ SG_ 2364727294 Hvesp20CellBalanceStatus "HVESP20 Cell Balance Status: Indicates whether or not the cells in this High Voltage Energy Storage Pack instance are balanced.This parameter is for one of multiple packs in an HVESS.  If there is only one pack in the system, the HVESS parameters sho...";
CM_ SG_ 2364727294 Hvesp20CellBalancingActive "HVESP20 Cell Balancing Active: Indicates whether or not the cells in this High Voltage Energy Storage Pack instance are currently being balanced.This parameter is for one of multiple packs in an HVESS.  If there is only one pack in the system, the HV...";
CM_ SG_ 2364727294 Hvesp20InternalChargerStatus "HVESP20 Internal Charger Status: Indicates that the charger in this HVES instance is on.  External chargers may use the External Energy Source Connection Status (SPN 7898) and related SPs.This parameter is for one of multiple packs in an HVESS. If th...";
CM_ SG_ 2364727294 Hvsp20HghVltgBsCnntnStts "HVESP20 High-Voltage Bus Connection Status: This parameter provides high level feedback on this High Voltage Energy Storage Pack instance high voltage bus connection. For specific contactor information, see SPN 16595 (HVESP20 High-Voltage Bus (Positi...";
CM_ SG_ 2364727294 Hvesp20OperationalStatus "HVESP20 Operational Status: Provides feedback on where this High Voltage Energy Storage Pack instance is in its operating spectrum, and includes feedback in response to the Operation Consent [i.e. SPN 16553 (HVESP20 Operation Consent)] and Power Down...";
CM_ SG_ 2364727294 Hvesp20Status1Counter "HVESP20 Status 1 Counter: The message counter is used to detect situations where the transmitting ECU malfunction repeats the same frame all the time. The receiver of the information may use the counter parameter to detect this situation. The transmi...";
CM_ SG_ 2364727294 Hvesp20Status1Crc "HVESP20 Status 1 CRC: The CRC is defined as follows: - Length: 8 bits- Polynomial: x^8+x^5+x^3+x^2+x+1- Initial Value: FFh- Input Data Reflection: Not reflected- Result Data Reflection: Not reflected- XOR value: FFh SAE makes no claim of the function...";
CM_ BO_ 2364727550 "High Voltage Energy Storage Pack 20 Data 7";
CM_ SG_ 2364727550 Hvesp20DischargeEnergyCapacity "HVESP20 Discharge Energy Capacity: The amount of stored electrical energy in this High Voltage Energy Storage Pack instance that is available for use by the hybrid or EV system, i.e. 'how full is the tank'. See SPN 16582 (HVESP20 Discharge Capacity) ...";
CM_ SG_ 2364727550 Hvesp20ChargeEnergyCapacity "HVESP20 Charge Energy Capacity: The amount of unused electrical energy storage available to be filled by charging this High Voltage Energy Storage Pack instance, i.e. 'how much empty space is remaining in the tank'. See SPN 16583 (HVESP20 Charge Capa...";
CM_ SG_ 2364727550 Hvsp20MxmmChrgVltgLmt "HVESP20 Maximum Charge Voltage Limit: The maximum voltage level not to be exceeded while charging this High Voltage Energy Storage Pack instance. If this parameter is not supported, the maximum charge voltage should be limited to SPN 16681 (HVESP20 R...";
CM_ BO_ 2364727806 "High Voltage Energy Storage Pack 20 Module Status 1";
CM_ SG_ 2364727806 Hvesp20Module1OperationalStatus "HVESP20 Module 1 Operational Status: Operational Status of Module 1 in this High Voltage Energy Storage Pack Instance.  Not Operational is used when the module is initializing or not able to function (e.g. internal module level monitors have failed)....";
CM_ SG_ 2364727806 Hvesp20Module2OperationalStatus "HVESP20 Module 2 Operational Status: Operational Status of Module 2 in this High Voltage Energy Storage Pack Instance.  Not Operational is used when the module is initializing or not able to function (e.g. internal module level monitors have failed)....";
CM_ SG_ 2364727806 Hvesp20Module3OperationalStatus "HVESP20 Module 3 Operational Status: Operational Status of Module 3 in this High Voltage Energy Storage Pack Instance.  Not Operational is used when the module is initializing or not able to function (e.g. internal module level monitors have failed)....";
CM_ SG_ 2364727806 Hvesp20Module4OperationalStatus "HVESP20 Module 4 Operational Status: Operational Status of Module 4 in this High Voltage Energy Storage Pack Instance.  Not Operational is used when the module is initializing or not able to function (e.g. internal module level monitors have failed)....";
CM_ SG_ 2364727806 Hvesp20Module5OperationalStatus "HVESP20 Module 5 Operational Status: Operational Status of Module 5 in this High Voltage Energy Storage Pack Instance.  Not Operational is used when the module is initializing or not able to function (e.g. internal module level monitors have failed)....";
CM_ SG_ 2364727806 Hvesp20Module6OperationalStatus "HVESP20 Module 6 Operational Status: Operational Status of Module 6 in this High Voltage Energy Storage Pack Instance.  Not Operational is used when the module is initializing or not able to function (e.g. internal module level monitors have failed)....";
CM_ SG_ 2364727806 Hvesp20Module7OperationalStatus "HVESP20 Module 7 Operational Status: Operational Status of Module 7 in this High Voltage Energy Storage Pack Instance.  Not Operational is used when the module is initializing or not able to function (e.g. internal module level monitors have failed)....";
CM_ SG_ 2364727806 Hvesp20Module8OperationalStatus "HVESP20 Module 8 Operational Status: Operational Status of Module 8 in this High Voltage Energy Storage Pack Instance.  Not Operational is used when the module is initializing or not able to function (e.g. internal module level monitors have failed)....";
CM_ SG_ 2364727806 Hvesp20Module9OperationalStatus "HVESP20 Module 9 Operational Status: Operational Status of Module 9 in this High Voltage Energy Storage Pack Instance.  Not Operational is used when the module is initializing or not able to function (e.g. internal module level monitors have failed)....";
CM_ SG_ 2364727806 Hvsp20Mdl10OprtnlStts "HVESP20 Module 10 Operational Status: Operational Status of Module 10 in this High Voltage Energy Storage Pack Instance.  Not Operational is used when the module is initializing or not able to function (e.g. internal module level monitors have failed...";
CM_ SG_ 2364727806 Hvsp20Mdl11OprtnlStts "HVESP20 Module 11 Operational Status: Operational Status of Module 11 in this High Voltage Energy Storage Pack Instance.  Not Operational is used when the module is initializing or not able to function (e.g. internal module level monitors have failed...";
CM_ SG_ 2364727806 Hvsp20Mdl12OprtnlStts "HVESP20 Module 12 Operational Status: Operational Status of Module 12 in this High Voltage Energy Storage Pack Instance.  Not Operational is used when the module is initializing or not able to function (e.g. internal module level monitors have failed...";
CM_ SG_ 2364727806 Hvsp20Mdl13OprtnlStts "HVESP20 Module 13 Operational Status: Operational Status of Module 13 in this High Voltage Energy Storage Pack Instance.  Not Operational is used when the module is initializing or not able to function (e.g. internal module level monitors have failed...";
CM_ SG_ 2364727806 Hvsp20Mdl14OprtnlStts "HVESP20 Module 14 Operational Status: Operational Status of Module 14 in this High Voltage Energy Storage Pack Instance.  Not Operational is used when the module is initializing or not able to function (e.g. internal module level monitors have failed...";
CM_ SG_ 2364727806 Hvsp20Mdl15OprtnlStts "HVESP20 Module 15 Operational Status: Operational Status of Module 15 in this High Voltage Energy Storage Pack Instance.  Not Operational is used when the module is initializing or not able to function (e.g. internal module level monitors have failed...";
CM_ SG_ 2364727806 Hvsp20Mdl16OprtnlStts "HVESP20 Module 16 Operational Status: Operational Status of Module 16 in this High Voltage Energy Storage Pack Instance.  Not Operational is used when the module is initializing or not able to function (e.g. internal module level monitors have failed...";
CM_ SG_ 2364727806 Hvsp20Mdl17OprtnlStts "HVESP20 Module 17 Operational Status: Operational Status of Module 17 in this High Voltage Energy Storage Pack Instance.  Not Operational is used when the module is initializing or not able to function (e.g. internal module level monitors have failed...";
CM_ SG_ 2364727806 Hvsp20Mdl18OprtnlStts "HVESP20 Module 18 Operational Status: Operational Status of Module 18 in this High Voltage Energy Storage Pack Instance.  Not Operational is used when the module is initializing or not able to function (e.g. internal module level monitors have failed...";
CM_ SG_ 2364727806 Hvsp20Mdl19OprtnlStts "HVESP20 Module 19 Operational Status: Operational Status of Module 19 in this High Voltage Energy Storage Pack Instance.  Not Operational is used when the module is initializing or not able to function (e.g. internal module level monitors have failed...";
CM_ SG_ 2364727806 Hvsp20Mdl20OprtnlStts "HVESP20 Module 20 Operational Status: Operational Status of Module 20 in this High Voltage Energy Storage Pack Instance.  Not Operational is used when the module is initializing or not able to function (e.g. internal module level monitors have failed...";
CM_ SG_ 2364727806 Hvsp20Mdl21OprtnlStts "HVESP20 Module 21 Operational Status: Operational Status of Module 21 in this High Voltage Energy Storage Pack Instance.  Not Operational is used when the module is initializing or not able to function (e.g. internal module level monitors have failed...";
CM_ SG_ 2364727806 Hvsp20Mdl22OprtnlStts "HVESP20 Module 22 Operational Status: Operational Status of Module 22 in this High Voltage Energy Storage Pack Instance.  Not Operational is used when the module is initializing or not able to function (e.g. internal module level monitors have failed...";
CM_ SG_ 2364727806 Hvsp20Mdl23OprtnlStts "HVESP20 Module 23 Operational Status: Operational Status of Module 23 in this High Voltage Energy Storage Pack Instance.  Not Operational is used when the module is initializing or not able to function (e.g. internal module level monitors have failed...";
CM_ SG_ 2364727806 Hvsp20Mdl24OprtnlStts "HVESP20 Module 24 Operational Status: Operational Status of Module 24 in this High Voltage Energy Storage Pack Instance.  Not Operational is used when the module is initializing or not able to function (e.g. internal module level monitors have failed...";
CM_ SG_ 2364727806 Hvsp20Mdl25OprtnlStts "HVESP20 Module 25 Operational Status: Operational Status of Module 25 in this High Voltage Energy Storage Pack Instance.  Not Operational is used when the module is initializing or not able to function (e.g. internal module level monitors have failed...";
CM_ SG_ 2364727806 Hvsp20Mdl26OprtnlStts "HVESP20 Module 26 Operational Status: Operational Status of Module 26 in this High Voltage Energy Storage Pack Instance.  Not Operational is used when the module is initializing or not able to function (e.g. internal module level monitors have failed...";
CM_ SG_ 2364727806 Hvsp20Mdl27OprtnlStts "HVESP20 Module 27 Operational Status: Operational Status of Module 27 in this High Voltage Energy Storage Pack Instance.  Not Operational is used when the module is initializing or not able to function (e.g. internal module level monitors have failed...";
CM_ SG_ 2364727806 Hvsp20Mdl28OprtnlStts "HVESP20 Module 28 Operational Status: Operational Status of Module 28 in this High Voltage Energy Storage Pack Instance.  Not Operational is used when the module is initializing or not able to function (e.g. internal module level monitors have failed...";
CM_ SG_ 2364727806 Hvsp20Mdl29OprtnlStts "HVESP20 Module 29 Operational Status: Operational Status of Module 29 in this High Voltage Energy Storage Pack Instance.  Not Operational is used when the module is initializing or not able to function (e.g. internal module level monitors have failed...";
CM_ SG_ 2364727806 Hvsp20Mdl30OprtnlStts "HVESP20 Module 30 Operational Status: Operational Status of Module 30 in this High Voltage Energy Storage Pack Instance.  Not Operational is used when the module is initializing or not able to function (e.g. internal module level monitors have failed...";
CM_ SG_ 2364727806 Hvsp20Mdl31OprtnlStts "HVESP20 Module 31 Operational Status: Operational Status of Module 31 in this High Voltage Energy Storage Pack Instance.  Not Operational is used when the module is initializing or not able to function (e.g. internal module level monitors have failed...";
CM_ SG_ 2364727806 Hvsp20Mdl32OprtnlStts "HVESP20 Module 32 Operational Status: Operational Status of Module 32 in this High Voltage Energy Storage Pack Instance.  Not Operational is used when the module is initializing or not able to function (e.g. internal module level monitors have failed...";
CM_ BO_ 2364728062 "High Voltage Energy Storage Pack 20 Thermal Management System Status 1";
CM_ SG_ 2364728062 Hvsp20ThrmlMngmntSstmSlInptPwr "HVESP20 Thermal Management System SLI Input Power: This is the low-voltage power consumed by this HVES Thermal Management System (TMS).This parameter is for one of multiple packs in an HVESS.  If there is only one pack in the system, the HVESS parame...";
CM_ SG_ 2364728062 Hvsp20TMtSstHVtIptPw "HVESP20 Thermal Management System High-Voltage Input Power: This is the high-voltage power consumed by this HVES Thermal Management System (TMS).This parameter is for one of multiple packs in an HVESS.  If there is only one pack in the system, the HV...";
CM_ SG_ 2364728062 Hvsp20ThrmlMngmntSstmCmprssrSpd "HVESP20 Thermal Management System Compressor Speed: When this High Voltage Energy Storage Pack Thermal Management System is equipped with an active cooling system (e.g. air conditioner), this is the Compressor Speed.This parameter is for one of multi...";
CM_ SG_ 2364728062 Hvsp20ThrmlMngmntSstmRltvHmdt "HVESP20 Thermal Management System Relative Humidty: When this High Voltage Energy Storage Pack Thermal Management System is equipped with a relative humidity sensor, this is the  measured Relative Humidity.This parameter is for one of multiple packs ...";
CM_ SG_ 2364728062 Hvsp20ThrmlMngmntSstmHtrStts "HVESP20 Thermal Management System Heater Status: The state of this High Voltage Energy Storage Pack heaterThis parameter is for one of multiple packs in an HVESS.  If there is only one pack in the system, the HVESS parameters should be used. If there...";
CM_ SG_ 2364728062 Hvsp20ThrmlMngmntSstmHvlStts "HVESP20 Thermal Management System HVIL Status: In multiple HVES configurations, this is the status of the High Voltage Interlock Loop from the viewpoint of this Thermal Management System.00b = HVIL Closed01b = HVIL Open10b = Error11b = Not AvailableT...";
CM_ SG_ 2364728062 Hvsp20ThrmlMngmntSstmMd "HVESP20 Thermal Management System Mode: Indicates the operating mode of the Thermal Management System.  The heat transfer medium may be (e.g. liquid or air).  The cooling system may be fans, liquid coolant, or a combination of mediums.  The system ma...";
CM_ SG_ 2364728062 Hvsp20ThrmlMngmntSstmClntLvl "HVESP20 Thermal Management System Coolant Level: Indicates the coolant level in this HVES Thermal Management System (TMS).This parameter is for one of multiple packs in an HVESS.  If there is only one pack in the system, the HVESS parameters should b...";
CM_ BO_ 2364728318 "High Voltage Energy Storage Pack 20 Data 8";
CM_ SG_ 2364728318 Hvsp20HghstCllVltgMdlNmr "HVESP20 Highest Cell Voltage Module Number: Identifies the location of the module containing SPN 16575 (HVESP20 Highest Cell Voltage).This parameter is for one of multiple packs in an HVESS. If there is only one pack in the system, the HVESS paramete...";
CM_ SG_ 2364728318 Hvsp20HghstCllVltgCllNmr "HVESP20 Highest Cell Voltage Cell Number: Identifies the location of SPN 16575 (HVESP20 Highest Cell Voltage) within SPN 16655 (HVESP20 Highest Cell Voltage Module Number).This parameter is for one of multiple packs in an HVESS. If there is only one ...";
CM_ SG_ 2364728318 Hvsp20LwstCllVltgMdlNmr "HVESP20 Lowest Cell Voltage Module Number: Identifies the location of the module containing SPN 16576 (HVESP20 Lowest Cell Voltage).This parameter is for one of multiple packs in an HVESS. If there is only one pack in the system, the HVESS parameters...";
CM_ SG_ 2364728318 Hvsp20LwstCllVltgCllNmr "HVESP20 Lowest Cell Voltage Cell Number: Identifies the location of SPN 16576 (HVESP20 Lowest Cell Voltage) within SPN 16657 (HVESP20 Lowest Cell Voltage Module Number).This parameter is for one of multiple packs in an HVESS. If there is only one pac...";
CM_ SG_ 2364728318 Hvesp20AverageCellVoltage "HVESP20 Average Cell Voltage: The average cell voltage in this High Voltage Energy Storage Pack instance.This parameter is for one of multiple packs in an HVESS.  If there is only one pack in the system, the HVESS parameters should be used. If there ...";
CM_ BO_ 2364728574 "High Voltage Energy Storage Pack 20 Data 9";
CM_ SG_ 2364728574 Hvsp20HghstCllTmprtrMdlNmr "HVESP20 Highest Cell Temperature Module Number: Identifies the location of the module containing SPN 16578 (HVESP20 Highest Cell Temperature).This parameter is for one of multiple packs in an HVESS. If there is only one pack in the system, the HVESS ...";
CM_ SG_ 2364728574 Hvsp20HghstCllTmprtrCllNmr "HVESP20 Highest Cell Temperature Cell Number: Identifies the location of SPN 16578 (HVESP20 Highest Cell Temperature) within SPN 16660 (HVESP20 Highest Cell Temperature Module Number).This parameter is for one of multiple packs in an HVESS. If there ...";
CM_ SG_ 2364728574 Hvsp20LwstCllTmprtrMdlNmr "HVESP20 Lowest Cell Temperature Module Number: Identifies the location of the module containing SPN 16579 (HVESP20 Lowest Cell Temperature).This parameter is for one of multiple packs in an HVESS. If there is only one pack in the system, the HVESS pa...";
CM_ SG_ 2364728574 Hvsp20LwstCllTmprtrCllNmr "HVESP20 Lowest Cell Temperature Cell Number: Identifies the location of SPN 16579 (HVESP20 Lowest Cell Temperature) within SPN 16662 (HVESP20 Lowest Cell Temperature Module Number).This parameter is for one of multiple packs in an HVESS. If there is ...";
CM_ SG_ 2364728574 Hvess20ThermalEventDetected "HVESS20 Thermal Event Detected: A sensor has detected the presence of a thermal event at or near High Voltage Energy Storage Pack instance.00b = No Thermal Event Detected01b = Thermal Event Detected10b = Error11b = Not availableThis parameter is for ...";
CM_ SG_ 2364728574 Hvsp20Dt9EmdddIntgrtSpprt "HVESP20 Data 9 Embedded Integrity Support: Indicates SPN 23033 (HVESP20 Data 9 CRC) and SPN 23032 (HVESP20 Data 9 Counter) are supported by the sender.00b = Embedded CRC and Counter are supported by the sender01b = Protection is provided using an ext...";
CM_ SG_ 2364728574 Hvesp20Data9Counter "HVESP20 Data 9 Counter: The message counter is used to detect situations where the transmitting ECU malfunction repeats the same frame all the time. The receiver of the information may use the counter parameter to detect this situation. The transmitt...";
CM_ SG_ 2364728574 Hvesp20Data9Crc "HVESP20 Data 9 CRC: The CRC is defined as follows: - Length: 8 bits- Polynomial: x^8+x^5+x^3+x^2+x+1- Initial Value: FFh- Input Data Reflection: Not reflected- Result Data Reflection: Not reflected- XOR value: FFh SAE makes no claim of the functional...";
CM_ BO_ 2364728830 "High Voltage Energy Storage Pack 20 Data 10";
CM_ SG_ 2364728830 Hvsp20HghstCllSttOfChrgMdlNmr "HVESP20 Highest Cell State of Charge Module Number: Identifies the location of the module containing SPN 16588 (HVESP20 Highest Cell State of Charge).This parameter is for one of multiple packs in an HVESS. If there is only one pack in the system, th...";
CM_ SG_ 2364728830 Hvsp20HghstCllSttOfChrgCllNmr "HVESP20 Highest Cell State of Charge Cell Number: Identifies the location of SPN 16588 (HVESP20 Highest Cell State of Charge) within SPN 16664 (HVESP20 Highest Cell State of Charge Module Number).This parameter is for one of multiple packs in an HVES...";
CM_ SG_ 2364728830 Hvsp20LwstCllSttOfChrgMdlNmr "HVESP20 Lowest Cell State of Charge Module Number: Identifies the location of the module containing SPN 16587 (HVESP20 Lowest Cell State of Charge).This parameter is for one of multiple packs in an HVESS. If there is only one pack in the system, the ...";
CM_ SG_ 2364728830 Hvsp20LwstCllSttOfChrgCllNmr "HVESP20 Lowest Cell State of Charge Cell Number: Identifies the location of SPN 16587 (HVESP20 Lowest Cell State of Charge) within SPN 16666 (HVESP20 Lowest Cell State of Charge Module Number).This parameter is for one of multiple packs in an HVESS. ...";
CM_ SG_ 2364728830 Hvsp20HghVltgBsAtvIsltnTstRslts "HVESP20 High-Voltage Bus Active Isolation Test Results: The isolation resistance expressed in Ohms per Volt that resulted from the High-Voltage Bus Active Isolation Test.See SPN 16600 (HVESP20 High-Voltage Bus Active Isolation Test Status) for test s...";
CM_ SG_ 2364728830 Hvsp20HVtBsPssvIstTstRsts "HVESP20 High-Voltage Bus Passive Isolation Test Results: The isolation resistance expressed in Ohms per Volt that resulted from the High-Voltage Bus Passive Isolation Test.See SPN 16601 (HVESP20 High-Voltage Bus Passive Isolation Test Status) for tes...";
CM_ BO_ 2364729086 "High Voltage Energy Storage Pack 20 Data 11";
CM_ SG_ 2364729086 Hvsp20BsVltgNgtvTChsssGrndVltg "HVESP20 Bus Voltage Negative to Chassis Ground Voltage: Voltage difference between the most negative terminal of the HVES battery and chassis measured on the hybrid or EV system bus side (not the battery side) of any HVES contained output contactor. ...";
CM_ SG_ 2364729086 Hvsp20VltgLvlNgtvTChsssGrndVltg "HVESP20 Voltage Level Negative to Chassis Ground Voltage: Voltage difference between the most negative terminal of the HVES battery and chassis measured at the battery side of any HVES contained output contactor.  This voltage may be used for system ...";
CM_ SG_ 2364729086 Hvesp20ActualChargeRate "HVESP20 Actual Charge Rate: This signal represents the actual present charge rate of this High Voltage Energy Storage Pack instance.This parameter is for one of multiple packs in an HVESS. If there is only one pack in the system, the HVESS parameters...";
CM_ BO_ 2364729342 "High Voltage Energy Storage Pack 21 Status 2";
CM_ SG_ 2364729342 Hvsp21DshrgPwrLmtDTSttOfChrg "HVESP21 Discharge Power Limit Due to State of Charge: Indicates whether or not discharge power of this HVES instance is being limited due to state of charge.This parameter is for one of multiple packs in an HVESS.  If there is only one pack in the sy...";
CM_ SG_ 2364729342 Hvsp21DshrgPwrLmtDTBttrTmprtr "HVESP21 Discharge Power Limit Due to Battery Temperature: Indicates whether or not discharge power of this HVES instance is being limited due to battery temperature.This parameter is for one of multiple packs in an HVESS.  If there is only one pack i...";
CM_ SG_ 2364729342 Hvsp21DsPwLtDTBttDstCdt "HVESP21 Discharge Power Limit Due to Battery Diagnostic Condition: Indicates whether or not discharge power of this HVES instance is being limited due to a battery diagnostic condition.This parameter is for one of multiple packs in an HVESS.  If ther...";
CM_ SG_ 2364729342 Hvsp21DsPwLtDTBttOCVt "HVESP21 Discharge Power Limit Due to Battery or Cell Voltage: Indicates whether or not discharge power of this HVES instance is being limited due to a battery or cell voltage level.This parameter is for one of multiple packs in an HVESS.  If there is...";
CM_ SG_ 2364729342 Hvsp21DshrgPwrLmtDTBttrCrrnt "HVESP21 Discharge Power Limit Due to Battery Current: Indicates whether or not discharge power of this HVES instance is being limited due to battery current.This parameter is for one of multiple packs in an HVESS.  If there is only one pack in the sy...";
CM_ SG_ 2364729342 Hvsp21DshrgPwrLmtDTAnUndfndCs "HVESP21 Discharge Power Limit Due to an Undefined Cause: Indicates whether or not discharge power of this HVES instance is being limited due to an undefined cause.This parameter is for one of multiple packs in an HVESS.  If there is only one pack in ...";
CM_ SG_ 2364729342 Hvsp21ChrgPwrLmtDTSttOfChrg "HVESP21 Charge Power Limit Due to State of Charge: Indicates whether or not charge power of this HVES instance is being limited due to state of charge.This parameter is for one of multiple packs in an HVESS.  If there is only one pack in the system, ...";
CM_ SG_ 2364729342 Hvsp21ChrgPwrLmtDTBttrTmprtr "HVESP21 Charge Power Limit Due to Battery Temperature: Indicates whether or not charge power of this HVES instance is being limited due to battery temperature.This parameter is for one of multiple packs in an HVESS.  If there is only one pack in the ...";
CM_ SG_ 2364729342 Hvsp21CPwLtDTBttDstCdt "HVESP21 Charge Power Limit Due to Battery Diagnostic Condition: Indicates whether or not charge power of this HVES instance is being limited due to a battery diagnostic condition.This parameter is for one of multiple packs in an HVESS.  If there is o...";
CM_ SG_ 2364729342 Hvsp21ChrgPwrLmtDTBttrOrCllVltg "HVESP21 Charge Power Limit Due to Battery or Cell Voltage: Indicates whether or not charge power of this HVES instance is being limited due to a battery or cell voltage level.This parameter is for one of multiple packs in an HVESS.  If there is only ...";
CM_ SG_ 2364729342 Hvsp21ChrgPwrLmtDTBttrCrrnt "HVESP21 Charge Power Limit Due to Battery Current: Indicates whether or not charge power of this HVES instance is being limited due to battery current.This parameter is for one of multiple packs in an HVESS.  If there is only one pack in the system, ...";
CM_ SG_ 2364729342 Hvsp21ChrgPwrLmtDTAnUndfndCs "HVESP21 Charge Power Limit Due to an Undefined Cause: Indicates whether or not charge power of this HVES instance is being limited due to an undefined cause.This parameter is for one of multiple packs in an HVESS.  If there is only one pack in the sy...";
CM_ BO_ 2364729598 "High Voltage Energy Storage Pack 21 Data 1";
CM_ SG_ 2364729598 Hvesp21AvailableDischargePower "HVESP21 Available Discharge Power: The rate at which this High Voltage Energy Storage Pack instance can currently provide energy for propulsion or other uses.This parameter is for one of multiple packs in an HVESS.  If there is only one pack in the s...";
CM_ SG_ 2364729598 Hvesp21AvailableChargePower "HVESP21 Available Charge Power: The rate at which this High Voltage Energy Storage Pack instance can currently receive energy from a regenerative or recharging system.This parameter is for one of multiple packs in an HVESS.  If there is only one pack...";
CM_ SG_ 2364729598 Hvesp21VoltageLevel "HVESP21 Voltage Level: The voltage level of this High Voltage Energy Storage Pack instance. This parameter should be synchronized with SPN 16715 (HVESP21 Current) such that a realized power value can be calculated. If the HVES component physically co...";
CM_ SG_ 2364729598 Hvesp21Current "HVESP21 Current: The current in or out of this High Voltage Energy Storage Pack instance. This parameter should be synchronized with SPN 16714 (HVESP21 Voltage Level) such that a realized power value can be calculated. This parameter is defined from ...";
CM_ BO_ 2364729854 "High Voltage Energy Storage Pack 21 Data 2";
CM_ SG_ 2364729854 Hvesp21FastUpdateStateOfCharge "HVESP21 Fast Update State of Charge: Indicates this High Voltage Energy Storage Pack instance state of charge. 0% means no charge remaining, 100% means the system is fully charged in terms of physical limits of this energy storage pack instance. Acce...";
CM_ SG_ 2364729854 Hvesp21HighestCellVoltage "HVESP21 Highest Cell Voltage: The highest voltage level reported by any cell in this High Voltage Energy Storage Pack instance. If a single voltage sensor covers more than one cell, the value in this parameter is for the smallest group of cells measu...";
CM_ SG_ 2364729854 Hvesp21LowestCellVoltage "HVESP21 Lowest Cell Voltage: The lowest voltage level reported by any cell in this High Voltage Energy Storage Pack instance. If a single voltage sensor covers more than one cell, the value in this parameter is for the smallest group of cells measure...";
CM_ SG_ 2364729854 Hvsp21CllVltgDffrntlStts "HVESP21 Cell Voltage Differential Status: Indicates whether or not the differential between the highest and lowest cell voltages are within acceptable limits, according to this High Voltage Energy Storage Pack instance. The actual voltage differentia...";
CM_ BO_ 2364730110 "High Voltage Energy Storage Pack 21 Data 3";
CM_ SG_ 2364730110 Hvesp21HighestCellTemperature "HVESP21 Highest Cell Temperature: The highest temperature level reported by any cell in this High Voltage Energy Storage Pack instance. If a single temperature sensor covers more than one cell, the value in this parameter is for the smallest group of...";
CM_ SG_ 2364730110 Hvesp21LowestCellTemperature "HVESP21 Lowest Cell Temperature: The lowest temperature level reported by any cell in this High Voltage Energy Storage Pack instance. If a single temperature sensor covers more than one cell, the value in this parameter is for the smallest group of c...";
CM_ SG_ 2364730110 Hvesp21AverageCellTemperature "HVESP21 Average Cell Temperature: The average temperature level of all cells in this High Voltage Energy Storage Pack instance.This parameter is for one of multiple packs in an HVESS.  If there is only one pack in the system, the HVESS parameters sho...";
CM_ SG_ 2364730110 Hvsp21CllTmprtrDffrntlStts "HVESP21 Cell Temperature Differential Status: Indicates whether or not the differential between the highest and lowest cell temperatures are within acceptable limits per this High Voltage Energy Storage Pack instance. The actual temperature different...";
CM_ BO_ 2364730366 "High Voltage Energy Storage Pack 21 Data 4";
CM_ SG_ 2364730366 Hvesp21DischargeCapacity "HVESP21 Discharge Capacity: The amount of stored electrical charge in this High Voltage Energy Storage Pack instance that is available for use by the hybrid or EV system, i.e. 'how full is the tank'. See SPN 16754 (HVESP21 Discharge Energy Capacity) ...";
CM_ SG_ 2364730366 Hvesp21ChargeCapacity "HVESP21 Charge Capacity: The amount of unused electrical charge storage in this High Voltage Energy Storage Pack instance that is available to be filled by charging, i.e. 'how much empty space is remaining in the tank'. See SPN 16755 (HVESP21 Charge ...";
CM_ SG_ 2364730366 Hvesp21CellBalancingCount "HVESP21 Cell Balancing Count: The number of cells that are currently being balanced in this High Voltage Energy Storage Pack instance.This parameter is for one of multiple packs in an HVESS.  If there is only one pack in the system, the HVESS paramet...";
CM_ BO_ 2364730622 "High Voltage Energy Storage Pack 21 Data 5";
CM_ SG_ 2364730622 Hvesp21LowestCellStateOfCharge "HVESP21 Lowest Cell State of Charge: Indicates the state of charge of the lowest-charged cell in this High Voltage Energy Storage Pack instance. 0% means no charge remaining, 100% means the cell is fully charged. If a single state of charge value cov...";
CM_ SG_ 2364730622 Hvesp21HighestCellStateOfCharge "HVESP21 Highest Cell State of Charge: Indicates the state of charge of the highest-charged cell in this High Voltage Energy Storage Pack instance. 0% means no charge remaining, 100% means the cell is fully charged. If a single state of charge value c...";
CM_ SG_ 2364730622 Hvsp21MxmmInstntnsDshrgCrrntLmt "HVESP21 Maximum Instantaneous Discharge Current Limit: The maximum instantaneous current flow limit out of this High Voltage Energy Storage Pack instance. This parameter is defined from the high voltage energy storage pack's point of view and should ...";
CM_ SG_ 2364730622 Hvsp21MxmmInstntnsChrgCrrntLmt "HVESP21 Maximum Instantaneous Charge Current Limit: The maximum instantaneous current flow limit into this High Voltage Energy Storage Pack instance. This parameter is defined from the high voltage energy storage pack's point of view and should refle...";
CM_ BO_ 2364730878 "High Voltage Energy Storage Pack 21 Data 6";
CM_ SG_ 2364730878 Hvesp21BusVoltage "HVESP21 Bus Voltage: The voltage level of the high voltage bus, as measured by this High Voltage Energy Storage Pack instance on the bus side (not the battery side) of its contactors.This parameter is for one of multiple packs in an HVESS.  If there ...";
CM_ SG_ 2364730878 Hvesp21IgnitionVoltage "HVESP21 Ignition Voltage: The voltage level at the ignition input of this High Voltage Energy Storage Pack controller.This parameter is for one of multiple packs in an HVESS.  If there is only one pack in the system, the HVESS parameters should be us...";
CM_ SG_ 2364730878 Hvesp21IntakeCoolantTemperature "HVESP21 Intake Coolant Temperature: The temperature of liquid coolant as it enters this High Voltage Energy Storage Pack instance.This parameter is for one of multiple packs in an HVESS.  If there is only one pack in the system, the HVESS parameters ...";
CM_ SG_ 2364730878 Hvesp21OutletCoolantTemperature "HVESP21 Outlet Coolant Temperature: The temperature of liquid coolant as it exits this High Voltage Energy Storage Pack instance.This parameter is for one of multiple packs in an HVESS.  If there is only one pack in the system, the HVESS parameters s...";
CM_ SG_ 2364730878 Hvesp21ElectronicsTemperature "HVESP21 Electronics Temperature: The temperature of the electronics or control modules in this High Voltage Energy Storage Pack instance.  If there are multiple temperature sensors then this parameter would be set to the maximum sensor reading.This p...";
CM_ SG_ 2364730878 Hvesp21Temperature "HVESP21 Temperature: The temperature of this High Voltage Energy Storage Pack instance. The value may be determined from a unique sensor specifically for this purpose, or by aggregating various temperature sensor readings within the pack.This paramet...";
CM_ BO_ 2364731134 "High Voltage Energy Storage Pack 21 Status 1";
CM_ SG_ 2364731134 Hvsp21HghVltgBsPstvCnttrStt "HVESP21 High-Voltage Bus (Positive) Contactor State: Position of this High Voltage Energy Storage Pack instance positive side bus contactor.  When this contactor is closed, the positive side of this HVES instance is connected to the positive side of ...";
CM_ SG_ 2364731134 Hvsp21HghVltgBsNgtvCnttrStt "HVESP21 High-Voltage Bus (Negative) Contactor State: Position of this High Voltage Energy Storage Pack instance negative side bus contactor. When this contactor is closed, the negative side of this HVES instance is connected to the negative side of t...";
CM_ SG_ 2364731134 Hvsp21HghVltgBsDsnntFrwrnng "HVESP21 High-Voltage Bus Disconnect Forewarning: Indicates that this High Voltage Energy Storage Pack instance is about to disconnect from the high voltage bus due to unacceptable conditions.This parameter is for one of multiple packs in an HVESS. If...";
CM_ SG_ 2364731134 Hvsp21HghVltgBsPrChrgRlStt "HVESP21 High-Voltage Bus Pre-Charge Relay State: Position of the high-voltage bus contactor pre-charge relay.  When this relay is closed, this High Voltage Energy Storage Pack instance is bringing the high-voltage bus up to its operating level.This p...";
CM_ SG_ 2364731134 Hvsp21CntrOfPkCnttrStt "HVESP21 Center of Pack Contactor State: Position of the center high-voltage contactor. When this contactor is closed, the positive half of this High Voltage Energy Storage Pack instance is connected to the negative half. If a system controls the posi...";
CM_ SG_ 2364731134 Hvsp21HghVltgBsAtvIsltnTstStts "HVESP21 High-Voltage Bus Active Isolation Test Status: Status of the high-voltage bus electrical active isolation test as performed by this High Voltage Energy Storage Pack instance.This parameter is for one of multiple packs in an HVESS. If there is...";
CM_ SG_ 2364731134 Hvsp21HghVltgBsPssvIsltnTstStts "HVESP21 High-Voltage Bus Passive Isolation Test Status: Status of the high-voltage bus electrical passive isolation test as performed by this High Voltage Energy Storage Pack instance.This parameter is for one of multiple packs in an HVESS. If there ...";
CM_ SG_ 2364731134 Hvesp21HvilStatus "HVESP21 HVIL Status: Status of the High Voltage Interlock Loop from the viewpoint of this High Voltage Energy Storage Pack instance.This parameter is for one of multiple packs in an HVESS. If there is only one pack in the system, the HVESS parameters...";
CM_ SG_ 2364731134 Hvesp21InertiaSwitchStatus "HVESP21 Inertia Switch Status: Switch indicating that an impact has been sensed by this High Voltage Energy Storage Pack instance. The impact indication may require action by another controller, or by this HVES instance itself.  For example, a contro...";
CM_ SG_ 2364731134 Hvesp21StateOfChargeStatus "HVESP21 State of Charge Status: Status of this High Voltage Energy Storage Pack instance State of Charge (SOC).  Note:  A given HVES controller may not support all of the states.This parameter is for one of multiple packs in an HVESS.  If there is on...";
CM_ SG_ 2364731134 Hvesp21CellBalanceStatus "HVESP21 Cell Balance Status: Indicates whether or not the cells in this High Voltage Energy Storage Pack instance are balanced.This parameter is for one of multiple packs in an HVESS.  If there is only one pack in the system, the HVESS parameters sho...";
CM_ SG_ 2364731134 Hvesp21CellBalancingActive "HVESP21 Cell Balancing Active: Indicates whether or not the cells in this High Voltage Energy Storage Pack instance are currently being balanced.This parameter is for one of multiple packs in an HVESS.  If there is only one pack in the system, the HV...";
CM_ SG_ 2364731134 Hvesp21InternalChargerStatus "HVESP21 Internal Charger Status: Indicates that the charger in this HVES instance is on.  External chargers may use the External Energy Source Connection Status (SPN 7898) and related SPs.This parameter is for one of multiple packs in an HVESS. If th...";
CM_ SG_ 2364731134 Hvsp21HghVltgBsCnntnStts "HVESP21 High-Voltage Bus Connection Status: This parameter provides high level feedback on this High Voltage Energy Storage Pack instance high voltage bus connection. For specific contactor information, see SPN 16737 (HVESP21 High-Voltage Bus (Positi...";
CM_ SG_ 2364731134 Hvesp21OperationalStatus "HVESP21 Operational Status: Provides feedback on where this High Voltage Energy Storage Pack instance is in its operating spectrum, and includes feedback in response to the Operation Consent [i.e. SPN 16695 (HVESP21 Operation Consent)] and Power Down...";
CM_ SG_ 2364731134 Hvesp21Status1Counter "HVESP21 Status 1 Counter: The message counter is used to detect situations where the transmitting ECU malfunction repeats the same frame all the time. The receiver of the information may use the counter parameter to detect this situation. The transmi...";
CM_ SG_ 2364731134 Hvesp21Status1Crc "HVESP21 Status 1 CRC: The CRC is defined as follows: - Length: 8 bits- Polynomial: x^8+x^5+x^3+x^2+x+1- Initial Value: FFh- Input Data Reflection: Not reflected- Result Data Reflection: Not reflected- XOR value: FFh SAE makes no claim of the function...";
CM_ BO_ 2364731390 "High Voltage Energy Storage Pack 21 Data 7";
CM_ SG_ 2364731390 Hvesp21DischargeEnergyCapacity "HVESP21 Discharge Energy Capacity: The amount of stored electrical energy in this High Voltage Energy Storage Pack instance that is available for use by the hybrid or EV system, i.e. 'how full is the tank'. See SPN 16724 (HVESP21 Discharge Capacity) ...";
CM_ SG_ 2364731390 Hvesp21ChargeEnergyCapacity "HVESP21 Charge Energy Capacity: The amount of unused electrical energy storage available to be filled by charging this High Voltage Energy Storage Pack instance, i.e. 'how much empty space is remaining in the tank'. See SPN 16725 (HVESP21 Charge Capa...";
CM_ SG_ 2364731390 Hvsp21MxmmChrgVltgLmt "HVESP21 Maximum Charge Voltage Limit: The maximum voltage level not to be exceeded while charging this High Voltage Energy Storage Pack instance. If this parameter is not supported, the maximum charge voltage should be limited to SPN 16823 (HVESP21 R...";
CM_ BO_ 2364731646 "High Voltage Energy Storage Pack 21 Module Status 1";
CM_ SG_ 2364731646 Hvesp21Module1OperationalStatus "HVESP21 Module 1 Operational Status: Operational Status of Module 1 in this High Voltage Energy Storage Pack Instance.  Not Operational is used when the module is initializing or not able to function (e.g. internal module level monitors have failed)....";
CM_ SG_ 2364731646 Hvesp21Module2OperationalStatus "HVESP21 Module 2 Operational Status: Operational Status of Module 2 in this High Voltage Energy Storage Pack Instance.  Not Operational is used when the module is initializing or not able to function (e.g. internal module level monitors have failed)....";
CM_ SG_ 2364731646 Hvesp21Module3OperationalStatus "HVESP21 Module 3 Operational Status: Operational Status of Module 3 in this High Voltage Energy Storage Pack Instance.  Not Operational is used when the module is initializing or not able to function (e.g. internal module level monitors have failed)....";
CM_ SG_ 2364731646 Hvesp21Module4OperationalStatus "HVESP21 Module 4 Operational Status: Operational Status of Module 4 in this High Voltage Energy Storage Pack Instance.  Not Operational is used when the module is initializing or not able to function (e.g. internal module level monitors have failed)....";
CM_ SG_ 2364731646 Hvesp21Module5OperationalStatus "HVESP21 Module 5 Operational Status: Operational Status of Module 5 in this High Voltage Energy Storage Pack Instance.  Not Operational is used when the module is initializing or not able to function (e.g. internal module level monitors have failed)....";
CM_ SG_ 2364731646 Hvesp21Module6OperationalStatus "HVESP21 Module 6 Operational Status: Operational Status of Module 6 in this High Voltage Energy Storage Pack Instance.  Not Operational is used when the module is initializing or not able to function (e.g. internal module level monitors have failed)....";
CM_ SG_ 2364731646 Hvesp21Module7OperationalStatus "HVESP21 Module 7 Operational Status: Operational Status of Module 7 in this High Voltage Energy Storage Pack Instance.  Not Operational is used when the module is initializing or not able to function (e.g. internal module level monitors have failed)....";
CM_ SG_ 2364731646 Hvesp21Module8OperationalStatus "HVESP21 Module 8 Operational Status: Operational Status of Module 8 in this High Voltage Energy Storage Pack Instance.  Not Operational is used when the module is initializing or not able to function (e.g. internal module level monitors have failed)....";
CM_ SG_ 2364731646 Hvesp21Module9OperationalStatus "HVESP21 Module 9 Operational Status: Operational Status of Module 9 in this High Voltage Energy Storage Pack Instance.  Not Operational is used when the module is initializing or not able to function (e.g. internal module level monitors have failed)....";
CM_ SG_ 2364731646 Hvsp21Mdl10OprtnlStts "HVESP21 Module 10 Operational Status: Operational Status of Module 10 in this High Voltage Energy Storage Pack Instance.  Not Operational is used when the module is initializing or not able to function (e.g. internal module level monitors have failed...";
CM_ SG_ 2364731646 Hvsp21Mdl11OprtnlStts "HVESP21 Module 11 Operational Status: Operational Status of Module 11 in this High Voltage Energy Storage Pack Instance.  Not Operational is used when the module is initializing or not able to function (e.g. internal module level monitors have failed...";
CM_ SG_ 2364731646 Hvsp21Mdl12OprtnlStts "HVESP21 Module 12 Operational Status: Operational Status of Module 12 in this High Voltage Energy Storage Pack Instance.  Not Operational is used when the module is initializing or not able to function (e.g. internal module level monitors have failed...";
CM_ SG_ 2364731646 Hvsp21Mdl13OprtnlStts "HVESP21 Module 13 Operational Status: Operational Status of Module 13 in this High Voltage Energy Storage Pack Instance.  Not Operational is used when the module is initializing or not able to function (e.g. internal module level monitors have failed...";
CM_ SG_ 2364731646 Hvsp21Mdl14OprtnlStts "HVESP21 Module 14 Operational Status: Operational Status of Module 14 in this High Voltage Energy Storage Pack Instance.  Not Operational is used when the module is initializing or not able to function (e.g. internal module level monitors have failed...";
CM_ SG_ 2364731646 Hvsp21Mdl15OprtnlStts "HVESP21 Module 15 Operational Status: Operational Status of Module 15 in this High Voltage Energy Storage Pack Instance.  Not Operational is used when the module is initializing or not able to function (e.g. internal module level monitors have failed...";
CM_ SG_ 2364731646 Hvsp21Mdl16OprtnlStts "HVESP21 Module 16 Operational Status: Operational Status of Module 16 in this High Voltage Energy Storage Pack Instance.  Not Operational is used when the module is initializing or not able to function (e.g. internal module level monitors have failed...";
CM_ SG_ 2364731646 Hvsp21Mdl17OprtnlStts "HVESP21 Module 17 Operational Status: Operational Status of Module 17 in this High Voltage Energy Storage Pack Instance.  Not Operational is used when the module is initializing or not able to function (e.g. internal module level monitors have failed...";
CM_ SG_ 2364731646 Hvsp21Mdl18OprtnlStts "HVESP21 Module 18 Operational Status: Operational Status of Module 18 in this High Voltage Energy Storage Pack Instance.  Not Operational is used when the module is initializing or not able to function (e.g. internal module level monitors have failed...";
CM_ SG_ 2364731646 Hvsp21Mdl19OprtnlStts "HVESP21 Module 19 Operational Status: Operational Status of Module 19 in this High Voltage Energy Storage Pack Instance.  Not Operational is used when the module is initializing or not able to function (e.g. internal module level monitors have failed...";
CM_ SG_ 2364731646 Hvsp21Mdl20OprtnlStts "HVESP21 Module 20 Operational Status: Operational Status of Module 20 in this High Voltage Energy Storage Pack Instance.  Not Operational is used when the module is initializing or not able to function (e.g. internal module level monitors have failed...";
CM_ SG_ 2364731646 Hvsp21Mdl21OprtnlStts "HVESP21 Module 21 Operational Status: Operational Status of Module 21 in this High Voltage Energy Storage Pack Instance.  Not Operational is used when the module is initializing or not able to function (e.g. internal module level monitors have failed...";
CM_ SG_ 2364731646 Hvsp21Mdl22OprtnlStts "HVESP21 Module 22 Operational Status: Operational Status of Module 22 in this High Voltage Energy Storage Pack Instance.  Not Operational is used when the module is initializing or not able to function (e.g. internal module level monitors have failed...";
CM_ SG_ 2364731646 Hvsp21Mdl23OprtnlStts "HVESP21 Module 23 Operational Status: Operational Status of Module 23 in this High Voltage Energy Storage Pack Instance.  Not Operational is used when the module is initializing or not able to function (e.g. internal module level monitors have failed...";
CM_ SG_ 2364731646 Hvsp21Mdl24OprtnlStts "HVESP21 Module 24 Operational Status: Operational Status of Module 24 in this High Voltage Energy Storage Pack Instance.  Not Operational is used when the module is initializing or not able to function (e.g. internal module level monitors have failed...";
CM_ SG_ 2364731646 Hvsp21Mdl25OprtnlStts "HVESP21 Module 25 Operational Status: Operational Status of Module 25 in this High Voltage Energy Storage Pack Instance.  Not Operational is used when the module is initializing or not able to function (e.g. internal module level monitors have failed...";
CM_ SG_ 2364731646 Hvsp21Mdl26OprtnlStts "HVESP21 Module 26 Operational Status: Operational Status of Module 26 in this High Voltage Energy Storage Pack Instance.  Not Operational is used when the module is initializing or not able to function (e.g. internal module level monitors have failed...";
CM_ SG_ 2364731646 Hvsp21Mdl27OprtnlStts "HVESP21 Module 27 Operational Status: Operational Status of Module 27 in this High Voltage Energy Storage Pack Instance.  Not Operational is used when the module is initializing or not able to function (e.g. internal module level monitors have failed...";
CM_ SG_ 2364731646 Hvsp21Mdl28OprtnlStts "HVESP21 Module 28 Operational Status: Operational Status of Module 28 in this High Voltage Energy Storage Pack Instance.  Not Operational is used when the module is initializing or not able to function (e.g. internal module level monitors have failed...";
CM_ SG_ 2364731646 Hvsp21Mdl29OprtnlStts "HVESP21 Module 29 Operational Status: Operational Status of Module 29 in this High Voltage Energy Storage Pack Instance.  Not Operational is used when the module is initializing or not able to function (e.g. internal module level monitors have failed...";
CM_ SG_ 2364731646 Hvsp21Mdl30OprtnlStts "HVESP21 Module 30 Operational Status: Operational Status of Module 30 in this High Voltage Energy Storage Pack Instance.  Not Operational is used when the module is initializing or not able to function (e.g. internal module level monitors have failed...";
CM_ SG_ 2364731646 Hvsp21Mdl31OprtnlStts "HVESP21 Module 31 Operational Status: Operational Status of Module 31 in this High Voltage Energy Storage Pack Instance.  Not Operational is used when the module is initializing or not able to function (e.g. internal module level monitors have failed...";
CM_ SG_ 2364731646 Hvsp21Mdl32OprtnlStts "HVESP21 Module 32 Operational Status: Operational Status of Module 32 in this High Voltage Energy Storage Pack Instance.  Not Operational is used when the module is initializing or not able to function (e.g. internal module level monitors have failed...";
CM_ BO_ 2364731902 "High Voltage Energy Storage Pack 21 Thermal Management System Status 1";
CM_ SG_ 2364731902 Hvsp21ThrmlMngmntSstmSlInptPwr "HVESP21 Thermal Management System SLI Input Power: This is the low-voltage power consumed by this HVES Thermal Management System (TMS).This parameter is for one of multiple packs in an HVESS.  If there is only one pack in the system, the HVESS parame...";
CM_ SG_ 2364731902 Hvsp21TMtSstHVtIptPw "HVESP21 Thermal Management System High-Voltage Input Power: This is the high-voltage power consumed by this HVES Thermal Management System (TMS).This parameter is for one of multiple packs in an HVESS.  If there is only one pack in the system, the HV...";
CM_ SG_ 2364731902 Hvsp21ThrmlMngmntSstmCmprssrSpd "HVESP21 Thermal Management System Compressor Speed: When this High Voltage Energy Storage Pack Thermal Management System is equipped with an active cooling system (e.g. air conditioner), this is the Compressor Speed.This parameter is for one of multi...";
CM_ SG_ 2364731902 Hvsp21ThrmlMngmntSstmRltvHmdt "HVESP21 Thermal Management System Relative Humidty: When this High Voltage Energy Storage Pack Thermal Management System is equipped with a relative humidity sensor, this is the  measured Relative Humidity.This parameter is for one of multiple packs ...";
CM_ SG_ 2364731902 Hvsp21ThrmlMngmntSstmHtrStts "HVESP21 Thermal Management System Heater Status: The state of this High Voltage Energy Storage Pack heaterThis parameter is for one of multiple packs in an HVESS.  If there is only one pack in the system, the HVESS parameters should be used. If there...";
CM_ SG_ 2364731902 Hvsp21ThrmlMngmntSstmHvlStts "HVESP21 Thermal Management System HVIL Status: In multiple HVES configurations, this is the status of the High Voltage Interlock Loop from the viewpoint of this Thermal Management System.00b = HVIL Closed01b = HVIL Open10b = Error11b = Not AvailableT...";
CM_ SG_ 2364731902 Hvsp21ThrmlMngmntSstmMd "HVESP21 Thermal Management System Mode: Indicates the operating mode of the Thermal Management System.  The heat transfer medium may be (e.g. liquid or air).  The cooling system may be fans, liquid coolant, or a combination of mediums.  The system ma...";
CM_ SG_ 2364731902 Hvsp21ThrmlMngmntSstmClntLvl "HVESP21 Thermal Management System Coolant Level: Indicates the coolant level in this HVES Thermal Management System (TMS).This parameter is for one of multiple packs in an HVESS.  If there is only one pack in the system, the HVESS parameters should b...";
CM_ BO_ 2364732158 "High Voltage Energy Storage Pack 21 Data 8";
CM_ SG_ 2364732158 Hvsp21HghstCllVltgMdlNmr "HVESP21 Highest Cell Voltage Module Number: Identifies the location of the module containing SPN 16717 (HVESP21 Highest Cell Voltage).This parameter is for one of multiple packs in an HVESS. If there is only one pack in the system, the HVESS paramete...";
CM_ SG_ 2364732158 Hvsp21HghstCllVltgCllNmr "HVESP21 Highest Cell Voltage Cell Number: Identifies the location of SPN 16717 (HVESP21 Highest Cell Voltage) within SPN 16797 (HVESP21 Highest Cell Voltage Module Number).This parameter is for one of multiple packs in an HVESS. If there is only one ...";
CM_ SG_ 2364732158 Hvsp21LwstCllVltgMdlNmr "HVESP21 Lowest Cell Voltage Module Number: Identifies the location of the module containing SPN 16718 (HVESP21 Lowest Cell Voltage).This parameter is for one of multiple packs in an HVESS. If there is only one pack in the system, the HVESS parameters...";
CM_ SG_ 2364732158 Hvsp21LwstCllVltgCllNmr "HVESP21 Lowest Cell Voltage Cell Number: Identifies the location of SPN 16718 (HVESP21 Lowest Cell Voltage) within SPN 16799 (HVESP21 Lowest Cell Voltage Module Number).This parameter is for one of multiple packs in an HVESS. If there is only one pac...";
CM_ SG_ 2364732158 Hvesp21AverageCellVoltage "HVESP21 Average Cell Voltage: The average cell voltage in this High Voltage Energy Storage Pack instance.This parameter is for one of multiple packs in an HVESS.  If there is only one pack in the system, the HVESS parameters should be used. If there ...";
BA_DEF_ SG_  "SPN" INT 0 524287;
BA_DEF_ BO_  "VFrameFormat" ENUM  "StandardCAN","ExtendedCAN","reserved","J1939PG";
BA_DEF_DEF_  "SPN" 0;
BA_DEF_DEF_  "VFrameFormat" "J1939PG";
BA_ "SPN" SG_ 2364718590 Hvesp18HighestCellTemperature 16294;
BA_ "SPN" SG_ 2364718590 Hvesp18LowestCellTemperature 16295;
BA_ "SPN" SG_ 2364718590 Hvesp18AverageCellTemperature 16296;
BA_ "SPN" SG_ 2364718590 Hvsp18CllTmprtrDffrntlStts 16297;
BA_ "SPN" SG_ 2364718846 Hvesp18DischargeCapacity 16298;
BA_ "SPN" SG_ 2364718846 Hvesp18ChargeCapacity 16299;
BA_ "SPN" SG_ 2364718846 Hvesp18CellBalancingCount 16300;
BA_ "SPN" SG_ 2364719102 Hvesp18LowestCellStateOfCharge 16303;
BA_ "SPN" SG_ 2364719102 Hvesp18HighestCellStateOfCharge 16304;
BA_ "SPN" SG_ 2364719102 Hvsp18MxmmInstntnsDshrgCrrntLmt 16301;
BA_ "SPN" SG_ 2364719102 Hvsp18MxmmInstntnsChrgCrrntLmt 16302;
BA_ "SPN" SG_ 2364719358 Hvesp18BusVoltage 16305;
BA_ "SPN" SG_ 2364719358 Hvesp18IgnitionVoltage 16306;
BA_ "SPN" SG_ 2364719358 Hvesp18IntakeCoolantTemperature 16307;
BA_ "SPN" SG_ 2364719358 Hvesp18OutletCoolantTemperature 16308;
BA_ "SPN" SG_ 2364719358 Hvesp18ElectronicsTemperature 16309;
BA_ "SPN" SG_ 2364719358 Hvesp18Temperature 16310;
BA_ "SPN" SG_ 2364719614 Hvsp18HghVltgBsPstvCnttrStt 16311;
BA_ "SPN" SG_ 2364719614 Hvsp18HghVltgBsNgtvCnttrStt 16312;
BA_ "SPN" SG_ 2364719614 Hvsp18HghVltgBsDsnntFrwrnng 16313;
BA_ "SPN" SG_ 2364719614 Hvsp18HghVltgBsPrChrgRlStt 16314;
BA_ "SPN" SG_ 2364719614 Hvsp18CntrOfPkCnttrStt 16315;
BA_ "SPN" SG_ 2364719614 Hvsp18HghVltgBsAtvIsltnTstStts 16316;
BA_ "SPN" SG_ 2364719614 Hvsp18HghVltgBsPssvIsltnTstStts 16317;
BA_ "SPN" SG_ 2364719614 Hvesp18HvilStatus 16318;
BA_ "SPN" SG_ 2364719614 Hvesp18InertiaSwitchStatus 16319;
BA_ "SPN" SG_ 2364719614 Hvesp18StateOfChargeStatus 16320;
BA_ "SPN" SG_ 2364719614 Hvesp18CellBalanceStatus 16321;
BA_ "SPN" SG_ 2364719614 Hvesp18CellBalancingActive 16322;
BA_ "SPN" SG_ 2364719614 Hvesp18InternalChargerStatus 16323;
BA_ "SPN" SG_ 2364719614 Hvsp18HghVltgBsCnntnStts 16324;
BA_ "SPN" SG_ 2364719614 Hvesp18OperationalStatus 16325;
BA_ "SPN" SG_ 2364719614 Hvesp18Status1Counter 16326;
BA_ "SPN" SG_ 2364719614 Hvesp18Status1Crc 16327;
BA_ "SPN" SG_ 2364719870 Hvesp18DischargeEnergyCapacity 16328;
BA_ "SPN" SG_ 2364719870 Hvesp18ChargeEnergyCapacity 16329;
BA_ "SPN" SG_ 2364719870 Hvsp18MxmmChrgVltgLmt 16330;
BA_ "SPN" SG_ 2364720126 Hvesp18Module1OperationalStatus 16331;
BA_ "SPN" SG_ 2364720126 Hvesp18Module2OperationalStatus 16332;
BA_ "SPN" SG_ 2364720126 Hvesp18Module3OperationalStatus 16333;
BA_ "SPN" SG_ 2364720126 Hvesp18Module4OperationalStatus 16334;
BA_ "SPN" SG_ 2364720126 Hvesp18Module5OperationalStatus 16335;
BA_ "SPN" SG_ 2364720126 Hvesp18Module6OperationalStatus 16336;
BA_ "SPN" SG_ 2364720126 Hvesp18Module7OperationalStatus 16337;
BA_ "SPN" SG_ 2364720126 Hvesp18Module8OperationalStatus 16338;
BA_ "SPN" SG_ 2364720126 Hvesp18Module9OperationalStatus 16339;
BA_ "SPN" SG_ 2364720126 Hvsp18Mdl10OprtnlStts 16340;
BA_ "SPN" SG_ 2364720126 Hvsp18Mdl11OprtnlStts 16341;
BA_ "SPN" SG_ 2364720126 Hvsp18Mdl12OprtnlStts 16342;
BA_ "SPN" SG_ 2364720126 Hvsp18Mdl13OprtnlStts 16343;
BA_ "SPN" SG_ 2364720126 Hvsp18Mdl14OprtnlStts 16344;
BA_ "SPN" SG_ 2364720126 Hvsp18Mdl15OprtnlStts 16345;
BA_ "SPN" SG_ 2364720126 Hvsp18Mdl16OprtnlStts 16346;
BA_ "SPN" SG_ 2364720126 Hvsp18Mdl17OprtnlStts 16347;
BA_ "SPN" SG_ 2364720126 Hvsp18Mdl18OprtnlStts 16348;
BA_ "SPN" SG_ 2364720126 Hvsp18Mdl19OprtnlStts 16349;
BA_ "SPN" SG_ 2364720126 Hvsp18Mdl20OprtnlStts 16350;
BA_ "SPN" SG_ 2364720126 Hvsp18Mdl21OprtnlStts 16351;
BA_ "SPN" SG_ 2364720126 Hvsp18Mdl22OprtnlStts 16352;
BA_ "SPN" SG_ 2364720126 Hvsp18Mdl23OprtnlStts 16353;
BA_ "SPN" SG_ 2364720126 Hvsp18Mdl24OprtnlStts 16354;
BA_ "SPN" SG_ 2364720126 Hvsp18Mdl25OprtnlStts 16355;
BA_ "SPN" SG_ 2364720126 Hvsp18Mdl26OprtnlStts 16356;
BA_ "SPN" SG_ 2364720126 Hvsp18Mdl27OprtnlStts 16357;
BA_ "SPN" SG_ 2364720126 Hvsp18Mdl28OprtnlStts 16358;
BA_ "SPN" SG_ 2364720126 Hvsp18Mdl29OprtnlStts 16359;
BA_ "SPN" SG_ 2364720126 Hvsp18Mdl30OprtnlStts 16360;
BA_ "SPN" SG_ 2364720126 Hvsp18Mdl31OprtnlStts 16361;
BA_ "SPN" SG_ 2364720126 Hvsp18Mdl32OprtnlStts 16362;
BA_ "SPN" SG_ 2364720382 Hvsp18ThrmlMngmntSstmSlInptPwr 16363;
BA_ "SPN" SG_ 2364720382 Hvsp18TMtSstHVtIptPw 16364;
BA_ "SPN" SG_ 2364720382 Hvsp18ThrmlMngmntSstmCmprssrSpd 16365;
BA_ "SPN" SG_ 2364720382 Hvsp18ThrmlMngmntSstmRltvHmdt 16366;
BA_ "SPN" SG_ 2364720382 Hvsp18ThrmlMngmntSstmHtrStts 16367;
BA_ "SPN" SG_ 2364720382 Hvsp18ThrmlMngmntSstmHvlStts 16368;
BA_ "SPN" SG_ 2364720382 Hvsp18ThrmlMngmntSstmMd 16369;
BA_ "SPN" SG_ 2364720382 Hvsp18ThrmlMngmntSstmClntLvl 16370;
BA_ "SPN" SG_ 2364720638 Hvsp18HghstCllVltgMdlNmr 16371;
BA_ "SPN" SG_ 2364720638 Hvsp18HghstCllVltgCllNmr 16372;
BA_ "SPN" SG_ 2364720638 Hvsp18LwstCllVltgMdlNmr 16373;
BA_ "SPN" SG_ 2364720638 Hvsp18LwstCllVltgCllNmr 16374;
BA_ "SPN" SG_ 2364720638 Hvesp18AverageCellVoltage 16375;
BA_ "SPN" SG_ 2364720894 Hvsp18HghstCllTmprtrMdlNmr 16376;
BA_ "SPN" SG_ 2364720894 Hvsp18HghstCllTmprtrCllNmr 16377;
BA_ "SPN" SG_ 2364720894 Hvsp18LwstCllTmprtrMdlNmr 16378;
BA_ "SPN" SG_ 2364720894 Hvsp18LwstCllTmprtrCllNmr 16379;
BA_ "SPN" SG_ 2364720894 Hvess18ThermalEventDetected 21305;
BA_ "SPN" SG_ 2364720894 Hvsp18Dt9EmdddIntgrtSpprt 23025;
BA_ "SPN" SG_ 2364720894 Hvesp18Data9Counter 23026;
BA_ "SPN" SG_ 2364720894 Hvesp18Data9Crc 23027;
BA_ "SPN" SG_ 2364721150 Hvsp18HghstCllSttOfChrgMdlNmr 16380;
BA_ "SPN" SG_ 2364721150 Hvsp18HghstCllSttOfChrgCllNmr 16381;
BA_ "SPN" SG_ 2364721150 Hvsp18LwstCllSttOfChrgMdlNmr 16382;
BA_ "SPN" SG_ 2364721150 Hvsp18LwstCllSttOfChrgCllNmr 16383;
BA_ "SPN" SG_ 2364721150 Hvsp18HghVltgBsAtvIsltnTstRslts 16384;
BA_ "SPN" SG_ 2364721150 Hvsp18HVtBsPssvIstTstRsts 16385;
BA_ "SPN" SG_ 2364721406 Hvsp18BsVltgNgtvTChsssGrndVltg 16386;
BA_ "SPN" SG_ 2364721406 Hvsp18VltgLvlNgtvTChsssGrndVltg 16387;
BA_ "SPN" SG_ 2364721406 Hvesp18ActualChargeRate 16388;
BA_ "SPN" SG_ 2364721662 Hvsp19DshrgPwrLmtDTSttOfChrg 16416;
BA_ "SPN" SG_ 2364721662 Hvsp19DshrgPwrLmtDTBttrTmprtr 16417;
BA_ "SPN" SG_ 2364721662 Hvsp19DsPwLtDTBttDstCdt 16418;
BA_ "SPN" SG_ 2364721662 Hvsp19DsPwLtDTBttOCVt 16419;
BA_ "SPN" SG_ 2364721662 Hvsp19DshrgPwrLmtDTBttrCrrnt 16420;
BA_ "SPN" SG_ 2364721662 Hvsp19DshrgPwrLmtDTAnUndfndCs 16421;
BA_ "SPN" SG_ 2364721662 Hvsp19ChrgPwrLmtDTSttOfChrg 16422;
BA_ "SPN" SG_ 2364721662 Hvsp19ChrgPwrLmtDTBttrTmprtr 16423;
BA_ "SPN" SG_ 2364721662 Hvsp19CPwLtDTBttDstCdt 16424;
BA_ "SPN" SG_ 2364721662 Hvsp19ChrgPwrLmtDTBttrOrCllVltg 16425;
BA_ "SPN" SG_ 2364721662 Hvsp19ChrgPwrLmtDTBttrCrrnt 16426;
BA_ "SPN" SG_ 2364721662 Hvsp19ChrgPwrLmtDTAnUndfndCs 16427;
BA_ "SPN" SG_ 2364721918 Hvesp19AvailableDischargePower 16428;
BA_ "SPN" SG_ 2364721918 Hvesp19AvailableChargePower 16429;
BA_ "SPN" SG_ 2364721918 Hvesp19VoltageLevel 16430;
BA_ "SPN" SG_ 2364721918 Hvesp19Current 16431;
BA_ "SPN" SG_ 2364722174 Hvesp19FastUpdateStateOfCharge 16432;
BA_ "SPN" SG_ 2364722174 Hvesp19HighestCellVoltage 16433;
BA_ "SPN" SG_ 2364722174 Hvesp19LowestCellVoltage 16434;
BA_ "SPN" SG_ 2364722174 Hvsp19CllVltgDffrntlStts 16435;
BA_ "SPN" SG_ 2364722430 Hvesp19HighestCellTemperature 16436;
BA_ "SPN" SG_ 2364722430 Hvesp19LowestCellTemperature 16437;
BA_ "SPN" SG_ 2364722430 Hvesp19AverageCellTemperature 16438;
BA_ "SPN" SG_ 2364722430 Hvsp19CllTmprtrDffrntlStts 16439;
BA_ "SPN" SG_ 2364722686 Hvesp19DischargeCapacity 16440;
BA_ "SPN" SG_ 2364722686 Hvesp19ChargeCapacity 16441;
BA_ "SPN" SG_ 2364722686 Hvesp19CellBalancingCount 16442;
BA_ "SPN" SG_ 2364722942 Hvesp19LowestCellStateOfCharge 16445;
BA_ "SPN" SG_ 2364722942 Hvesp19HighestCellStateOfCharge 16446;
BA_ "SPN" SG_ 2364722942 Hvsp19MxmmInstntnsDshrgCrrntLmt 16443;
BA_ "SPN" SG_ 2364722942 Hvsp19MxmmInstntnsChrgCrrntLmt 16444;
BA_ "SPN" SG_ 2364723198 Hvesp19BusVoltage 16447;
BA_ "SPN" SG_ 2364723198 Hvesp19IgnitionVoltage 16448;
BA_ "SPN" SG_ 2364723198 Hvesp19IntakeCoolantTemperature 16449;
BA_ "SPN" SG_ 2364723198 Hvesp19OutletCoolantTemperature 16450;
BA_ "SPN" SG_ 2364723198 Hvesp19ElectronicsTemperature 16451;
BA_ "SPN" SG_ 2364723198 Hvesp19Temperature 16452;
BA_ "SPN" SG_ 2364723454 Hvsp19HghVltgBsPstvCnttrStt 16453;
BA_ "SPN" SG_ 2364723454 Hvsp19HghVltgBsNgtvCnttrStt 16454;
BA_ "SPN" SG_ 2364723454 Hvsp19HghVltgBsDsnntFrwrnng 16455;
BA_ "SPN" SG_ 2364723454 Hvsp19HghVltgBsPrChrgRlStt 16456;
BA_ "SPN" SG_ 2364723454 Hvsp19CntrOfPkCnttrStt 16457;
BA_ "SPN" SG_ 2364723454 Hvsp19HghVltgBsAtvIsltnTstStts 16458;
BA_ "SPN" SG_ 2364723454 Hvsp19HghVltgBsPssvIsltnTstStts 16459;
BA_ "SPN" SG_ 2364723454 Hvesp19HvilStatus 16460;
BA_ "SPN" SG_ 2364723454 Hvesp19InertiaSwitchStatus 16461;
BA_ "SPN" SG_ 2364723454 Hvesp19StateOfChargeStatus 16462;
BA_ "SPN" SG_ 2364723454 Hvesp19CellBalanceStatus 16463;
BA_ "SPN" SG_ 2364723454 Hvesp19CellBalancingActive 16464;
BA_ "SPN" SG_ 2364723454 Hvesp19InternalChargerStatus 16465;
BA_ "SPN" SG_ 2364723454 Hvsp19HghVltgBsCnntnStts 16466;
BA_ "SPN" SG_ 2364723454 Hvesp19OperationalStatus 16467;
BA_ "SPN" SG_ 2364723454 Hvesp19Status1Counter 16468;
BA_ "SPN" SG_ 2364723454 Hvesp19Status1Crc 16469;
BA_ "SPN" SG_ 2364723710 Hvesp19DischargeEnergyCapacity 16470;
BA_ "SPN" SG_ 2364723710 Hvesp19ChargeEnergyCapacity 16471;
BA_ "SPN" SG_ 2364723710 Hvsp19MxmmChrgVltgLmt 16472;
BA_ "SPN" SG_ 2364723966 Hvesp19Module1OperationalStatus 16473;
BA_ "SPN" SG_ 2364723966 Hvesp19Module2OperationalStatus 16474;
BA_ "SPN" SG_ 2364723966 Hvesp19Module3OperationalStatus 16475;
BA_ "SPN" SG_ 2364723966 Hvesp19Module4OperationalStatus 16476;
BA_ "SPN" SG_ 2364723966 Hvesp19Module5OperationalStatus 16477;
BA_ "SPN" SG_ 2364723966 Hvesp19Module6OperationalStatus 16478;
BA_ "SPN" SG_ 2364723966 Hvesp19Module7OperationalStatus 16479;
BA_ "SPN" SG_ 2364723966 Hvesp19Module8OperationalStatus 16480;
BA_ "SPN" SG_ 2364723966 Hvesp19Module9OperationalStatus 16481;
BA_ "SPN" SG_ 2364723966 Hvsp19Mdl10OprtnlStts 16482;
BA_ "SPN" SG_ 2364723966 Hvsp19Mdl11OprtnlStts 16483;
BA_ "SPN" SG_ 2364723966 Hvsp19Mdl12OprtnlStts 16484;
BA_ "SPN" SG_ 2364723966 Hvsp19Mdl13OprtnlStts 16485;
BA_ "SPN" SG_ 2364723966 Hvsp19Mdl14OprtnlStts 16486;
BA_ "SPN" SG_ 2364723966 Hvsp19Mdl15OprtnlStts 16487;
BA_ "SPN" SG_ 2364723966 Hvsp19Mdl16OprtnlStts 16488;
BA_ "SPN" SG_ 2364723966 Hvsp19Mdl17OprtnlStts 16489;
BA_ "SPN" SG_ 2364723966 Hvsp19Mdl18OprtnlStts 16490;
BA_ "SPN" SG_ 2364723966 Hvsp19Mdl19OprtnlStts 16491;
BA_ "SPN" SG_ 2364723966 Hvsp19Mdl20OprtnlStts 16492;
BA_ "SPN" SG_ 2364723966 Hvsp19Mdl21OprtnlStts 16493;
BA_ "SPN" SG_ 2364723966 Hvsp19Mdl22OprtnlStts 16494;
BA_ "SPN" SG_ 2364723966 Hvsp19Mdl23OprtnlStts 16495;
BA_ "SPN" SG_ 2364723966 Hvsp19Mdl24OprtnlStts 16496;
BA_ "SPN" SG_ 2364723966 Hvsp19Mdl25OprtnlStts 16497;
BA_ "SPN" SG_ 2364723966 Hvsp19Mdl26OprtnlStts 16498;
BA_ "SPN" SG_ 2364723966 Hvsp19Mdl27OprtnlStts 16499;
BA_ "SPN" SG_ 2364723966 Hvsp19Mdl28OprtnlStts 16500;
BA_ "SPN" SG_ 2364723966 Hvsp19Mdl29OprtnlStts 16501;
BA_ "SPN" SG_ 2364723966 Hvsp19Mdl30OprtnlStts 16502;
BA_ "SPN" SG_ 2364723966 Hvsp19Mdl31OprtnlStts 16503;
BA_ "SPN" SG_ 2364723966 Hvsp19Mdl32OprtnlStts 16504;
BA_ "SPN" SG_ 2364724222 Hvsp19ThrmlMngmntSstmSlInptPwr 16505;
BA_ "SPN" SG_ 2364724222 Hvsp19TMtSstHVtIptPw 16506;
BA_ "SPN" SG_ 2364724222 Hvsp19ThrmlMngmntSstmCmprssrSpd 16507;
BA_ "SPN" SG_ 2364724222 Hvsp19ThrmlMngmntSstmRltvHmdt 16508;
BA_ "SPN" SG_ 2364724222 Hvsp19ThrmlMngmntSstmHtrStts 16509;
BA_ "SPN" SG_ 2364724222 Hvsp19ThrmlMngmntSstmHvlStts 16510;
BA_ "SPN" SG_ 2364724222 Hvsp19ThrmlMngmntSstmMd 16511;
BA_ "SPN" SG_ 2364724222 Hvsp19ThrmlMngmntSstmClntLvl 16512;
BA_ "SPN" SG_ 2364724478 Hvsp19HghstCllVltgMdlNmr 16513;
BA_ "SPN" SG_ 2364724478 Hvsp19HghstCllVltgCllNmr 16514;
BA_ "SPN" SG_ 2364724478 Hvsp19LwstCllVltgMdlNmr 16515;
BA_ "SPN" SG_ 2364724478 Hvsp19LwstCllVltgCllNmr 16516;
BA_ "SPN" SG_ 2364724478 Hvesp19AverageCellVoltage 16517;
BA_ "SPN" SG_ 2364724734 Hvsp19HghstCllTmprtrMdlNmr 16518;
BA_ "SPN" SG_ 2364724734 Hvsp19HghstCllTmprtrCllNmr 16519;
BA_ "SPN" SG_ 2364724734 Hvsp19LwstCllTmprtrMdlNmr 16520;
BA_ "SPN" SG_ 2364724734 Hvsp19LwstCllTmprtrCllNmr 16521;
BA_ "SPN" SG_ 2364724734 Hvess19ThermalEventDetected 21306;
BA_ "SPN" SG_ 2364724734 Hvsp19Dt9EmdddIntgrtSpprt 23028;
BA_ "SPN" SG_ 2364724734 Hvesp19Data9Counter 23029;
BA_ "SPN" SG_ 2364724734 Hvesp19Data9Crc 23030;
BA_ "SPN" SG_ 2364724990 Hvsp19HghstCllSttOfChrgMdlNmr 16522;
BA_ "SPN" SG_ 2364724990 Hvsp19HghstCllSttOfChrgCllNmr 16523;
BA_ "SPN" SG_ 2364724990 Hvsp19LwstCllSttOfChrgMdlNmr 16524;
BA_ "SPN" SG_ 2364724990 Hvsp19LwstCllSttOfChrgCllNmr 16525;
BA_ "SPN" SG_ 2364724990 Hvsp19HghVltgBsAtvIsltnTstRslts 16526;
BA_ "SPN" SG_ 2364724990 Hvsp19HVtBsPssvIstTstRsts 16527;
BA_ "SPN" SG_ 2364725246 Hvsp19BsVltgNgtvTChsssGrndVltg 16528;
BA_ "SPN" SG_ 2364725246 Hvsp19VltgLvlNgtvTChsssGrndVltg 16529;
BA_ "SPN" SG_ 2364725246 Hvesp19ActualChargeRate 16530;
BA_ "SPN" SG_ 2364725502 Hvsp20DshrgPwrLmtDTSttOfChrg 16558;
BA_ "SPN" SG_ 2364725502 Hvsp20DshrgPwrLmtDTBttrTmprtr 16559;
BA_ "SPN" SG_ 2364725502 Hvsp20DsPwLtDTBttDstCdt 16560;
BA_ "SPN" SG_ 2364725502 Hvsp20DsPwLtDTBttOCVt 16561;
BA_ "SPN" SG_ 2364725502 Hvsp20DshrgPwrLmtDTBttrCrrnt 16562;
BA_ "SPN" SG_ 2364725502 Hvsp20DshrgPwrLmtDTAnUndfndCs 16563;
BA_ "SPN" SG_ 2364725502 Hvsp20ChrgPwrLmtDTSttOfChrg 16564;
BA_ "SPN" SG_ 2364725502 Hvsp20ChrgPwrLmtDTBttrTmprtr 16565;
BA_ "SPN" SG_ 2364725502 Hvsp20CPwLtDTBttDstCdt 16566;
BA_ "SPN" SG_ 2364725502 Hvsp20ChrgPwrLmtDTBttrOrCllVltg 16567;
BA_ "SPN" SG_ 2364725502 Hvsp20ChrgPwrLmtDTBttrCrrnt 16568;
BA_ "SPN" SG_ 2364725502 Hvsp20ChrgPwrLmtDTAnUndfndCs 16569;
BA_ "SPN" SG_ 2364725758 Hvesp20AvailableDischargePower 16570;
BA_ "SPN" SG_ 2364725758 Hvesp20AvailableChargePower 16571;
BA_ "SPN" SG_ 2364725758 Hvesp20VoltageLevel 16572;
BA_ "SPN" SG_ 2364725758 Hvesp20Current 16573;
BA_ "SPN" SG_ 2364726014 Hvesp20FastUpdateStateOfCharge 16574;
BA_ "SPN" SG_ 2364726014 Hvesp20HighestCellVoltage 16575;
BA_ "SPN" SG_ 2364726014 Hvesp20LowestCellVoltage 16576;
BA_ "SPN" SG_ 2364726014 Hvsp20CllVltgDffrntlStts 16577;
BA_ "SPN" SG_ 2364726270 Hvesp20HighestCellTemperature 16578;
BA_ "SPN" SG_ 2364726270 Hvesp20LowestCellTemperature 16579;
BA_ "SPN" SG_ 2364726270 Hvesp20AverageCellTemperature 16580;
BA_ "SPN" SG_ 2364726270 Hvsp20CllTmprtrDffrntlStts 16581;
BA_ "SPN" SG_ 2364726526 Hvesp20DischargeCapacity 16582;
BA_ "SPN" SG_ 2364726526 Hvesp20ChargeCapacity 16583;
BA_ "SPN" SG_ 2364726526 Hvesp20CellBalancingCount 16584;
BA_ "SPN" SG_ 2364726782 Hvesp20LowestCellStateOfCharge 16587;
BA_ "SPN" SG_ 2364726782 Hvesp20HighestCellStateOfCharge 16588;
BA_ "SPN" SG_ 2364726782 Hvsp20MxmmInstntnsDshrgCrrntLmt 16585;
BA_ "SPN" SG_ 2364726782 Hvsp20MxmmInstntnsChrgCrrntLmt 16586;
BA_ "SPN" SG_ 2364727038 Hvesp20BusVoltage 16589;
BA_ "SPN" SG_ 2364727038 Hvesp20IgnitionVoltage 16590;
BA_ "SPN" SG_ 2364727038 Hvesp20IntakeCoolantTemperature 16591;
BA_ "SPN" SG_ 2364727038 Hvesp20OutletCoolantTemperature 16592;
BA_ "SPN" SG_ 2364727038 Hvesp20ElectronicsTemperature 16593;
BA_ "SPN" SG_ 2364727038 Hvesp20Temperature 16594;
BA_ "SPN" SG_ 2364727294 Hvsp20HghVltgBsPstvCnttrStt 16595;
BA_ "SPN" SG_ 2364727294 Hvsp20HghVltgBsNgtvCnttrStt 16596;
BA_ "SPN" SG_ 2364727294 Hvsp20HghVltgBsDsnntFrwrnng 16597;
BA_ "SPN" SG_ 2364727294 Hvsp20HghVltgBsPrChrgRlStt 16598;
BA_ "SPN" SG_ 2364727294 Hvsp20CntrOfPkCnttrStt 16599;
BA_ "SPN" SG_ 2364727294 Hvsp20HghVltgBsAtvIsltnTstStts 16600;
BA_ "SPN" SG_ 2364727294 Hvsp20HghVltgBsPssvIsltnTstStts 16601;
BA_ "SPN" SG_ 2364727294 Hvesp20HvilStatus 16602;
BA_ "SPN" SG_ 2364727294 Hvesp20InertiaSwitchStatus 16603;
BA_ "SPN" SG_ 2364727294 Hvesp20StateOfChargeStatus 16604;
BA_ "SPN" SG_ 2364727294 Hvesp20CellBalanceStatus 16605;
BA_ "SPN" SG_ 2364727294 Hvesp20CellBalancingActive 16606;
BA_ "SPN" SG_ 2364727294 Hvesp20InternalChargerStatus 16607;
BA_ "SPN" SG_ 2364727294 Hvsp20HghVltgBsCnntnStts 16608;
BA_ "SPN" SG_ 2364727294 Hvesp20OperationalStatus 16609;
BA_ "SPN" SG_ 2364727294 Hvesp20Status1Counter 16610;
BA_ "SPN" SG_ 2364727294 Hvesp20Status1Crc 16611;
BA_ "SPN" SG_ 2364727550 Hvesp20DischargeEnergyCapacity 16612;
BA_ "SPN" SG_ 2364727550 Hvesp20ChargeEnergyCapacity 16613;
BA_ "SPN" SG_ 2364727550 Hvsp20MxmmChrgVltgLmt 16614;
BA_ "SPN" SG_ 2364727806 Hvesp20Module1OperationalStatus 16615;
BA_ "SPN" SG_ 2364727806 Hvesp20Module2OperationalStatus 16616;
BA_ "SPN" SG_ 2364727806 Hvesp20Module3OperationalStatus 16617;
BA_ "SPN" SG_ 2364727806 Hvesp20Module4OperationalStatus 16618;
BA_ "SPN" SG_ 2364727806 Hvesp20Module5OperationalStatus 16619;
BA_ "SPN" SG_ 2364727806 Hvesp20Module6OperationalStatus 16620;
BA_ "SPN" SG_ 2364727806 Hvesp20Module7OperationalStatus 16621;
BA_ "SPN" SG_ 2364727806 Hvesp20Module8OperationalStatus 16622;
BA_ "SPN" SG_ 2364727806 Hvesp20Module9OperationalStatus 16623;
BA_ "SPN" SG_ 2364727806 Hvsp20Mdl10OprtnlStts 16624;
BA_ "SPN" SG_ 2364727806 Hvsp20Mdl11OprtnlStts 16625;
BA_ "SPN" SG_ 2364727806 Hvsp20Mdl12OprtnlStts 16626;
BA_ "SPN" SG_ 2364727806 Hvsp20Mdl13OprtnlStts 16627;
BA_ "SPN" SG_ 2364727806 Hvsp20Mdl14OprtnlStts 16628;
BA_ "SPN" SG_ 2364727806 Hvsp20Mdl15OprtnlStts 16629;
BA_ "SPN" SG_ 2364727806 Hvsp20Mdl16OprtnlStts 16630;
BA_ "SPN" SG_ 2364727806 Hvsp20Mdl17OprtnlStts 16631;
BA_ "SPN" SG_ 2364727806 Hvsp20Mdl18OprtnlStts 16632;
BA_ "SPN" SG_ 2364727806 Hvsp20Mdl19OprtnlStts 16633;
BA_ "SPN" SG_ 2364727806 Hvsp20Mdl20OprtnlStts 16634;
BA_ "SPN" SG_ 2364727806 Hvsp20Mdl21OprtnlStts 16635;
BA_ "SPN" SG_ 2364727806 Hvsp20Mdl22OprtnlStts 16636;
BA_ "SPN" SG_ 2364727806 Hvsp20Mdl23OprtnlStts 16637;
BA_ "SPN" SG_ 2364727806 Hvsp20Mdl24OprtnlStts 16638;
BA_ "SPN" SG_ 2364727806 Hvsp20Mdl25OprtnlStts 16639;
BA_ "SPN" SG_ 2364727806 Hvsp20Mdl26OprtnlStts 16640;
BA_ "SPN" SG_ 2364727806 Hvsp20Mdl27OprtnlStts 16641;
BA_ "SPN" SG_ 2364727806 Hvsp20Mdl28OprtnlStts 16642;
BA_ "SPN" SG_ 2364727806 Hvsp20Mdl29OprtnlStts 16643;
BA_ "SPN" SG_ 2364727806 Hvsp20Mdl30OprtnlStts 16644;
BA_ "SPN" SG_ 2364727806 Hvsp20Mdl31OprtnlStts 16645;
BA_ "SPN" SG_ 2364727806 Hvsp20Mdl32OprtnlStts 16646;
BA_ "SPN" SG_ 2364728062 Hvsp20ThrmlMngmntSstmSlInptPwr 16647;
BA_ "SPN" SG_ 2364728062 Hvsp20TMtSstHVtIptPw 16648;
BA_ "SPN" SG_ 2364728062 Hvsp20ThrmlMngmntSstmCmprssrSpd 16649;
BA_ "SPN" SG_ 2364728062 Hvsp20ThrmlMngmntSstmRltvHmdt 16650;
BA_ "SPN" SG_ 2364728062 Hvsp20ThrmlMngmntSstmHtrStts 16651;
BA_ "SPN" SG_ 2364728062 Hvsp20ThrmlMngmntSstmHvlStts 16652;
BA_ "SPN" SG_ 2364728062 Hvsp20ThrmlMngmntSstmMd 16653;
BA_ "SPN" SG_ 2364728062 Hvsp20ThrmlMngmntSstmClntLvl 16654;
BA_ "SPN" SG_ 2364728318 Hvsp20HghstCllVltgMdlNmr 16655;
BA_ "SPN" SG_ 2364728318 Hvsp20HghstCllVltgCllNmr 16656;
BA_ "SPN" SG_ 2364728318 Hvsp20LwstCllVltgMdlNmr 16657;
BA_ "SPN" SG_ 2364728318 Hvsp20LwstCllVltgCllNmr 16658;
BA_ "SPN" SG_ 2364728318 Hvesp20AverageCellVoltage 16659;
BA_ "SPN" SG_ 2364728574 Hvsp20HghstCllTmprtrMdlNmr 16660;
BA_ "SPN" SG_ 2364728574 Hvsp20HghstCllTmprtrCllNmr 16661;
BA_ "SPN" SG_ 2364728574 Hvsp20LwstCllTmprtrMdlNmr 16662;
BA_ "SPN" SG_ 2364728574 Hvsp20LwstCllTmprtrCllNmr 16663;
BA_ "SPN" SG_ 2364728574 Hvess20ThermalEventDetected 21307;
BA_ "SPN" SG_ 2364728574 Hvsp20Dt9EmdddIntgrtSpprt 23031;
BA_ "SPN" SG_ 2364728574 Hvesp20Data9Counter 23032;
BA_ "SPN" SG_ 2364728574 Hvesp20Data9Crc 23033;
BA_ "SPN" SG_ 2364728830 Hvsp20HghstCllSttOfChrgMdlNmr 16664;
BA_ "SPN" SG_ 2364728830 Hvsp20HghstCllSttOfChrgCllNmr 16665;
BA_ "SPN" SG_ 2364728830 Hvsp20LwstCllSttOfChrgMdlNmr 16666;
BA_ "SPN" SG_ 2364728830 Hvsp20LwstCllSttOfChrgCllNmr 16667;
BA_ "SPN" SG_ 2364728830 Hvsp20HghVltgBsAtvIsltnTstRslts 16668;
BA_ "SPN" SG_ 2364728830 Hvsp20HVtBsPssvIstTstRsts 16669;
BA_ "SPN" SG_ 2364729086 Hvsp20BsVltgNgtvTChsssGrndVltg 16670;
BA_ "SPN" SG_ 2364729086 Hvsp20VltgLvlNgtvTChsssGrndVltg 16671;
BA_ "SPN" SG_ 2364729086 Hvesp20ActualChargeRate 16672;
BA_ "SPN" SG_ 2364729342 Hvsp21DshrgPwrLmtDTSttOfChrg 16700;
BA_ "SPN" SG_ 2364729342 Hvsp21DshrgPwrLmtDTBttrTmprtr 16701;
BA_ "SPN" SG_ 2364729342 Hvsp21DsPwLtDTBttDstCdt 16702;
BA_ "SPN" SG_ 2364729342 Hvsp21DsPwLtDTBttOCVt 16703;
BA_ "SPN" SG_ 2364729342 Hvsp21DshrgPwrLmtDTBttrCrrnt 16704;
BA_ "SPN" SG_ 2364729342 Hvsp21DshrgPwrLmtDTAnUndfndCs 16705;
BA_ "SPN" SG_ 2364729342 Hvsp21ChrgPwrLmtDTSttOfChrg 16706;
BA_ "SPN" SG_ 2364729342 Hvsp21ChrgPwrLmtDTBttrTmprtr 16707;
BA_ "SPN" SG_ 2364729342 Hvsp21CPwLtDTBttDstCdt 16708;
BA_ "SPN" SG_ 2364729342 Hvsp21ChrgPwrLmtDTBttrOrCllVltg 16709;
BA_ "SPN" SG_ 2364729342 Hvsp21ChrgPwrLmtDTBttrCrrnt 16710;
BA_ "SPN" SG_ 2364729342 Hvsp21ChrgPwrLmtDTAnUndfndCs 16711;
BA_ "SPN" SG_ 2364729598 Hvesp21AvailableDischargePower 16712;
BA_ "SPN" SG_ 2364729598 Hvesp21AvailableChargePower 16713;
BA_ "SPN" SG_ 2364729598 Hvesp21VoltageLevel 16714;
BA_ "SPN" SG_ 2364729598 Hvesp21Current 16715;
BA_ "SPN" SG_ 2364729854 Hvesp21FastUpdateStateOfCharge 16716;
BA_ "SPN" SG_ 2364729854 Hvesp21HighestCellVoltage 16717;
BA_ "SPN" SG_ 2364729854 Hvesp21LowestCellVoltage 16718;
BA_ "SPN" SG_ 2364729854 Hvsp21CllVltgDffrntlStts 16719;
BA_ "SPN" SG_ 2364730110 Hvesp21HighestCellTemperature 16720;
BA_ "SPN" SG_ 2364730110 Hvesp21LowestCellTemperature 16721;
BA_ "SPN" SG_ 2364730110 Hvesp21AverageCellTemperature 16722;
BA_ "SPN" SG_ 2364730110 Hvsp21CllTmprtrDffrntlStts 16723;
BA_ "SPN" SG_ 2364730366 Hvesp21DischargeCapacity 16724;
BA_ "SPN" SG_ 2364730366 Hvesp21ChargeCapacity 16725;
BA_ "SPN" SG_ 2364730366 Hvesp21CellBalancingCount 16726;
BA_ "SPN" SG_ 2364730622 Hvesp21LowestCellStateOfCharge 16729;
BA_ "SPN" SG_ 2364730622 Hvesp21HighestCellStateOfCharge 16730;
BA_ "SPN" SG_ 2364730622 Hvsp21MxmmInstntnsDshrgCrrntLmt 16727;
BA_ "SPN" SG_ 2364730622 Hvsp21MxmmInstntnsChrgCrrntLmt 16728;
BA_ "SPN" SG_ 2364730878 Hvesp21BusVoltage 16731;
BA_ "SPN" SG_ 2364730878 Hvesp21IgnitionVoltage 16732;
BA_ "SPN" SG_ 2364730878 Hvesp21IntakeCoolantTemperature 16733;
BA_ "SPN" SG_ 2364730878 Hvesp21OutletCoolantTemperature 16734;
BA_ "SPN" SG_ 2364730878 Hvesp21ElectronicsTemperature 16735;
BA_ "SPN" SG_ 2364730878 Hvesp21Temperature 16736;
BA_ "SPN" SG_ 2364731134 Hvsp21HghVltgBsPstvCnttrStt 16737;
BA_ "SPN" SG_ 2364731134 Hvsp21HghVltgBsNgtvCnttrStt 16738;
BA_ "SPN" SG_ 2364731134 Hvsp21HghVltgBsDsnntFrwrnng 16739;
BA_ "SPN" SG_ 2364731134 Hvsp21HghVltgBsPrChrgRlStt 16740;
BA_ "SPN" SG_ 2364731134 Hvsp21CntrOfPkCnttrStt 16741;
BA_ "SPN" SG_ 2364731134 Hvsp21HghVltgBsAtvIsltnTstStts 16742;
BA_ "SPN" SG_ 2364731134 Hvsp21HghVltgBsPssvIsltnTstStts 16743;
BA_ "SPN" SG_ 2364731134 Hvesp21HvilStatus 16744;
BA_ "SPN" SG_ 2364731134 Hvesp21InertiaSwitchStatus 16745;
BA_ "SPN" SG_ 2364731134 Hvesp21StateOfChargeStatus 16746;
BA_ "SPN" SG_ 2364731134 Hvesp21CellBalanceStatus 16747;
BA_ "SPN" SG_ 2364731134 Hvesp21CellBalancingActive 16748;
BA_ "SPN" SG_ 2364731134 Hvesp21InternalChargerStatus 16749;
BA_ "SPN" SG_ 2364731134 Hvsp21HghVltgBsCnntnStts 16750;
BA_ "SPN" SG_ 2364731134 Hvesp21OperationalStatus 16751;
BA_ "SPN" SG_ 2364731134 Hvesp21Status1Counter 16752;
BA_ "SPN" SG_ 2364731134 Hvesp21Status1Crc 16753;
BA_ "SPN" SG_ 2364731390 Hvesp21DischargeEnergyCapacity 16754;
BA_ "SPN" SG_ 2364731390 Hvesp21ChargeEnergyCapacity 16755;
BA_ "SPN" SG_ 2364731390 Hvsp21MxmmChrgVltgLmt 16756;
BA_ "SPN" SG_ 2364731646 Hvesp21Module1OperationalStatus 16757;
BA_ "SPN" SG_ 2364731646 Hvesp21Module2OperationalStatus 16758;
BA_ "SPN" SG_ 2364731646 Hvesp21Module3OperationalStatus 16759;
BA_ "SPN" SG_ 2364731646 Hvesp21Module4OperationalStatus 16760;
BA_ "SPN" SG_ 2364731646 Hvesp21Module5OperationalStatus 16761;
BA_ "SPN" SG_ 2364731646 Hvesp21Module6OperationalStatus 16762;
BA_ "SPN" SG_ 2364731646 Hvesp21Module7OperationalStatus 16763;
BA_ "SPN" SG_ 2364731646 Hvesp21Module8OperationalStatus 16764;
BA_ "SPN" SG_ 2364731646 Hvesp21Module9OperationalStatus 16765;
BA_ "SPN" SG_ 2364731646 Hvsp21Mdl10OprtnlStts 16766;
BA_ "SPN" SG_ 2364731646 Hvsp21Mdl11OprtnlStts 16767;
BA_ "SPN" SG_ 2364731646 Hvsp21Mdl12OprtnlStts 16768;
BA_ "SPN" SG_ 2364731646 Hvsp21Mdl13OprtnlStts 16769;
BA_ "SPN" SG_ 2364731646 Hvsp21Mdl14OprtnlStts 16770;
BA_ "SPN" SG_ 2364731646 Hvsp21Mdl15OprtnlStts 16771;
BA_ "SPN" SG_ 2364731646 Hvsp21Mdl16OprtnlStts 16772;
BA_ "SPN" SG_ 2364731646 Hvsp21Mdl17OprtnlStts 16773;
BA_ "SPN" SG_ 2364731646 Hvsp21Mdl18OprtnlStts 16774;
BA_ "SPN" SG_ 2364731646 Hvsp21Mdl19OprtnlStts 16775;
BA_ "SPN" SG_ 2364731646 Hvsp21Mdl20OprtnlStts 16776;
BA_ "SPN" SG_ 2364731646 Hvsp21Mdl21OprtnlStts 16777;
BA_ "SPN" SG_ 2364731646 Hvsp21Mdl22OprtnlStts 16778;
BA_ "SPN" SG_ 2364731646 Hvsp21Mdl23OprtnlStts 16779;
BA_ "SPN" SG_ 2364731646 Hvsp21Mdl24OprtnlStts 16780;
BA_ "SPN" SG_ 2364731646 Hvsp21Mdl25OprtnlStts 16781;
BA_ "SPN" SG_ 2364731646 Hvsp21Mdl26OprtnlStts 16782;
BA_ "SPN" SG_ 2364731646 Hvsp21Mdl27OprtnlStts 16783;
BA_ "SPN" SG_ 2364731646 Hvsp21Mdl28OprtnlStts 16784;
BA_ "SPN" SG_ 2364731646 Hvsp21Mdl29OprtnlStts 16785;
BA_ "SPN" SG_ 2364731646 Hvsp21Mdl30OprtnlStts 16786;
BA_ "SPN" SG_ 2364731646 Hvsp21Mdl31OprtnlStts 16787;
BA_ "SPN" SG_ 2364731646 Hvsp21Mdl32OprtnlStts 16788;
BA_ "SPN" SG_ 2364731902 Hvsp21ThrmlMngmntSstmSlInptPwr 16789;
BA_ "SPN" SG_ 2364731902 Hvsp21TMtSstHVtIptPw 16790;
BA_ "SPN" SG_ 2364731902 Hvsp21ThrmlMngmntSstmCmprssrSpd 16791;
BA_ "SPN" SG_ 2364731902 Hvsp21ThrmlMngmntSstmRltvHmdt 16792;
BA_ "SPN" SG_ 2364731902 Hvsp21ThrmlMngmntSstmHtrStts 16793;
BA_ "SPN" SG_ 2364731902 Hvsp21ThrmlMngmntSstmHvlStts 16794;
BA_ "SPN" SG_ 2364731902 Hvsp21ThrmlMngmntSstmMd 16795;
BA_ "SPN" SG_ 2364731902 Hvsp21ThrmlMngmntSstmClntLvl 16796;
BA_ "SPN" SG_ 2364732158 Hvsp21HghstCllVltgMdlNmr 16797;
BA_ "SPN" SG_ 2364732158 Hvsp21HghstCllVltgCllNmr 16798;
BA_ "SPN" SG_ 2364732158 Hvsp21LwstCllVltgMdlNmr 16799;
BA_ "SPN" SG_ 2364732158 Hvsp21LwstCllVltgCllNmr 16800;
BA_ "SPN" SG_ 2364732158 Hvesp21AverageCellVoltage 16801;
